VERSION ""

NS_ :

BS_:

BU_: RAD_RR RAD_RL RAD_FR RAD_FL RAD_FC CGW APA ADC

BO_ 537 VCU_CGW_219: 8 CGW
 SG_ VCURemainingRng : 17|10@0+ (1,0) [0|1000] "" Vector__XXX
 SG_ VCUMotOverSpd : 55|1@0+ (1,0) [0|1] "" Vector__XXX
 SG_ VCUPwrDisp : 33|10@0+ (1,-300) [-300|700] "kw" Vector__XXX
 SG_ VCUMotOverTemp : 54|1@0+ (1,0) [0|1] "" Vector__XXX
 SG_ VCUImdStopDriving : 63|1@0+ (1,0) [0|1] "" Vector__XXX
 SG_ VCUDrvModIndcn : 20|3@0+ (1,0) [0|7] "" Vector__XXX
 SG_ VCURmvAcChger : 62|1@0+ (1,0) [0|1] "" Vector__XXX
 SG_ CrrntLimdClsAirCdnrIndcn : 4|1@0+ (1,0) [0|1] "" Vector__XXX
 SG_ DCStationCrrntLimdIndcn : 15|1@0+ (1,0) [0|1] "" Vector__XXX
 SG_ DCChrgrPluginSts : 9|1@0+ (1,0) [0|1] "" Vector__XXX
 SG_ CrrntLimdLockVehIndcn : 5|1@0+ (1,0) [0|1] "" Vector__XXX
 SG_ ACChrgrOverT : 39|1@0+ (1,0) [0|1] "" Vector__XXX
 SG_ VehPwrLimdlampReq : 61|1@0+ (1,0) [0|1] "" Vector__XXX
 SG_ DCChrgPortTempHighIndcn : 1|1@0+ (1,0) [0|1] "" Vector__XXX
 SG_ VCURgnCpLimdIndcn : 14|1@0+ (1,0) [0|1] "" Vector__XXX
 SG_ VCUElecLockfail : 8|1@0+ (1,0) [0|1] "" Vector__XXX
 SG_ VCUShiftChangefail : 59|1@0+ (1,0) [0|1] "" Vector__XXX
 SG_ VCUBrakeRemind : 60|1@0+ (1,0) [0|1] "" Vector__XXX
 SG_ VCUVehRdy : 53|1@0+ (1,0) [0|1] ""  RAD_FC
 SG_ VCURegenSts : 49|2@0+ (1,0) [0|3] "" Vector__XXX
 SG_ DCChrgrOverT : 38|1@0+ (1,0) [0|1] "" Vector__XXX
 SG_ HiVoltCntctrSts : 58|3@0+ (1,0) [0|7] "" Vector__XXX
 SG_ ACChrgrPluginSts : 52|1@0+ (1,0) [0|1] "" Vector__XXX
 SG_ VCUChrgDispLampReq : 23|3@0+ (1,0) [0|7] "" Vector__XXX
 SG_ DCChrgPortTempLowIndcn : 0|1@0+ (1,0) [0|1] "" Vector__XXX
 SG_ ACChrgPortTempLowIndcn : 2|1@0+ (1,0) [0|1] "" Vector__XXX
 SG_ VCUHVILError : 51|1@0+ (1,0) [0|1] "" Vector__XXX
 SG_ ACChrgCurrentRng : 11|2@0+ (1,0) [0|3] "" Vector__XXX
 SG_ ACChrgPortTempHighIndcn : 3|1@0+ (1,0) [0|1] "" Vector__XXX
 SG_ ACChrgCmplSts : 13|2@0+ (1,0) [0|3] "" Vector__XXX
 SG_ VCUFourWhlDrvIndcn : 37|2@0+ (1,0) [0|3] "" Vector__XXX
 SG_ EPFaultLevelWarning : 35|2@0+ (1,0) [0|3] "" Vector__XXX
 SG_ VCUChgLineSts : 50|1@0+ (1,0) [0|1] "" Vector__XXX

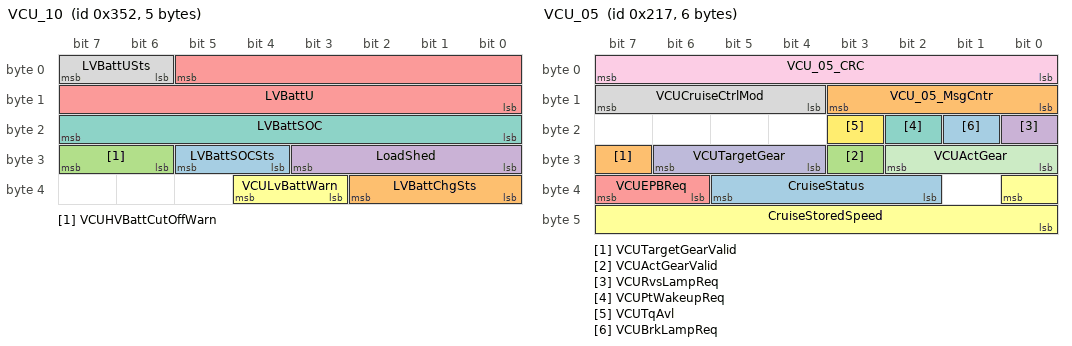
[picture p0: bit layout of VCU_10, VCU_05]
BO_ 850 VCU_10: 5 CGW
 SG_ LVBattSOCSts : 29|2@0+ (1,0) [0|3] "" Vector__XXX
 SG_ LVBattChgSts : 34|3@0+ (1,0) [0|7] "" Vector__XXX
 SG_ VCUHVBattCutOffWarn : 31|2@0+ (1,0) [0|3] "" Vector__XXX
 SG_ LoadShed : 27|4@0+ (1,0) [0|15] "" Vector__XXX
 SG_ LVBattU : 5|14@0+ (0.000976563,3) [3|18] "V"  RAD_RL,RAD_FR,ADC,RAD_RR,RAD_FC,RAD_FL
 SG_ VCULvBattWarn : 36|2@0+ (1,0) [0|3] "" Vector__XXX
 SG_ LVBattSOC : 23|8@0+ (1,0) [0|100] "%" Vector__XXX
 SG_ LVBattUSts : 7|2@0+ (1,0) [0|3] ""  ADC,RAD_FC,RAD_RL,APA,RAD_FR,RAD_FL,RAD_RR

BO_ 535 VCU_05: 6 CGW
 SG_ CruiseStatus : 37|4@0+ (1,0) [0|15] "" Vector__XXX
 SG_ VCUTargetGearValid : 31|1@0+ (1,0) [0|1] "" Vector__XXX
 SG_ VCUActGearValid : 27|1@0+ (1,0) [0|1] ""  RAD_FL,RAD_RR,APA,RAD_RL,RAD_FC,RAD_FR
 SG_ VCURvsLampReq : 16|1@0+ (1,0) [0|1] "" Vector__XXX
 SG_ VCUEPBReq : 39|2@0+ (1,0) [0|3] "" Vector__XXX
 SG_ CruiseStoredSpeed : 32|9@0+ (0.5,0) [0|255.5] "" Vector__XXX
 SG_ VCUPtWakeupReq : 18|1@0+ (1,0) [0|1] "" Vector__XXX
 SG_ VCUCruiseCtrlMod : 15|4@0+ (1,0) [0|15] "" Vector__XXX
 SG_ VCU_05_CRC : 7|8@0+ (1,0) [0|255] ""  RAD_FR,RAD_FC,RAD_FL,RAD_RL,APA,RAD_RR
 SG_ VCUTargetGear : 30|3@0+ (1,0) [0|7] "" Vector__XXX
 SG_ VCUActGear : 26|3@0+ (1,0) [0|7] ""  RAD_RR,APA,RAD_FL,RAD_RL,RAD_FC,RAD_FR
 SG_ VCUTqAvl : 19|1@0+ (1,0) [0|1] ""  ADC
 SG_ VCUBrkLampReq : 17|1@0+ (1,0) [0|1] "" Vector__XXX
 SG_ VCU_05_MsgCntr : 11|4@0+ (1,0) [0|15] ""  RAD_RL,APA,RAD_RR,RAD_FC,RAD_FR,RAD_FL

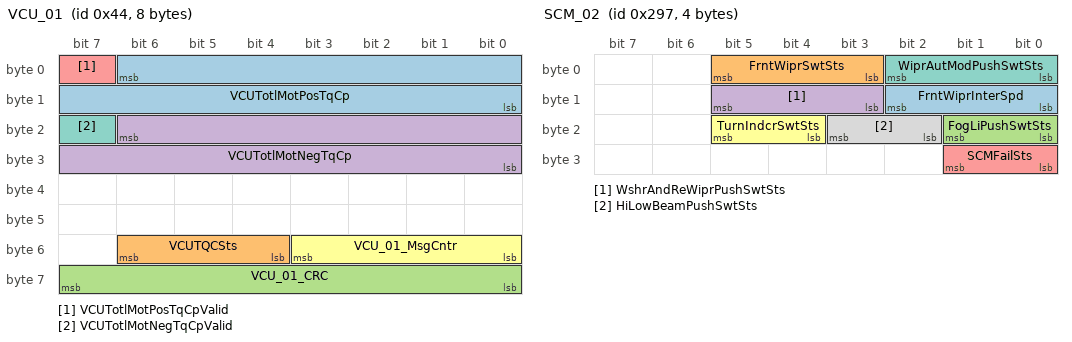
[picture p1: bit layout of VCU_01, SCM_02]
BO_ 68 VCU_01: 8 CGW
 SG_ VCUTotlMotPosTqCp : 6|15@0- (0.125,0) [-2048|2047.875] "Nm"  ADC
 SG_ VCUTQCSts : 54|3@0+ (1,0) [0|7] ""  ADC
 SG_ VCU_01_CRC : 63|8@0+ (1,0) [0|255] "" Vector__XXX
 SG_ VCUTotlMotNegTqCp : 22|15@0- (0.125,0) [-2048|2047.875] "Nm"  ADC
 SG_ VCUTotlMotPosTqCpValid : 7|1@0+ (1,0) [0|1] "" Vector__XXX
 SG_ VCU_01_MsgCntr : 51|4@0+ (1,0) [0|15] "" Vector__XXX
 SG_ VCUTotlMotNegTqCpValid : 23|1@0+ (1,0) [0|1] "" Vector__XXX

BO_ 663 SCM_02: 4 CGW
 SG_ FrntWiprInterSpd : 10|3@0+ (1,0) [0|7] "" Vector__XXX
 SG_ FrntWiprSwtSts : 5|3@0+ (1,0) [0|7] "" Vector__XXX
 SG_ FogLiPushSwtSts : 17|2@0+ (1,0) [0|3] "" Vector__XXX
 SG_ WshrAndReWiprPushSwtSts : 13|3@0+ (1,0) [0|7] "" Vector__XXX
 SG_ SCMFailSts : 25|2@0+ (1,0) [0|3] "" Vector__XXX
 SG_ TurnIndcrSwtSts : 21|2@0+ (1,0) [0|3] ""  RAD_RR,RAD_RL,RAD_FR,RAD_FL
 SG_ WiprAutModPushSwtSts : 2|3@0+ (1,0) [0|3] "" Vector__XXX
 SG_ HiLowBeamPushSwtSts : 19|2@0+ (1,0) [0|3] "" Vector__XXX

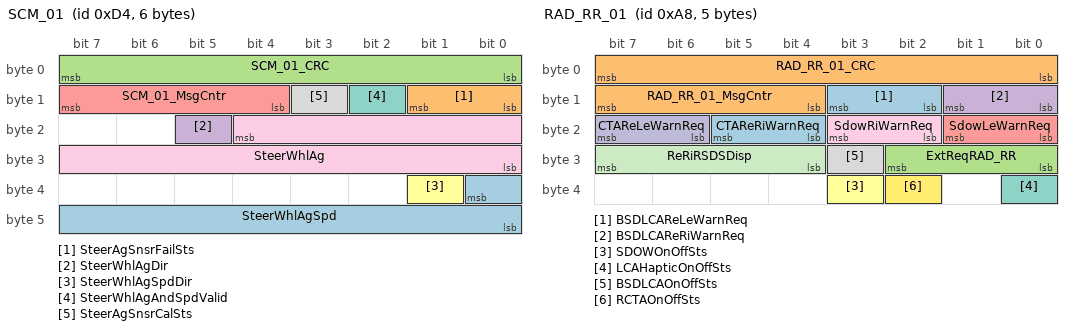
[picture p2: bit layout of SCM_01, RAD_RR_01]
BO_ 212 SCM_01: 6 CGW
 SG_ SteerWhlAgSpd : 32|9@0+ (5,0) [0|2550] "Deg/sec"  RAD_RR,RAD_FL,RAD_FR,RAD_FC,RAD_RL
 SG_ SteerAgSnsrFailSts : 9|2@0+ (1,0) [0|3] ""  RAD_FR,RAD_FL,RAD_RR,RAD_RL,RAD_FC
 SG_ SCM_01_CRC : 7|8@0+ (1,0) [0|255] ""  RAD_RL,RAD_RR,RAD_FL,RAD_FR,RAD_FC
 SG_ SteerWhlAgDir : 21|1@0+ (1,0) [0|1] ""  RAD_FR,RAD_FC,RAD_RR,RAD_FL,RAD_RL
 SG_ SCM_01_MsgCntr : 15|4@0+ (1,0) [0|15] ""  RAD_RL,RAD_FR,RAD_FC,RAD_RR,RAD_FL
 SG_ SteerWhlAgSpdDir : 33|1@0+ (1,0) [0|1] ""  RAD_RR,RAD_FL,RAD_RL,RAD_FC,RAD_FR
 SG_ SteerWhlAgAndSpdValid : 10|1@0+ (1,0) [0|1] ""  RAD_FC,RAD_RR,RAD_FL,RAD_FR,RAD_RL
 SG_ SteerAgSnsrCalSts : 11|1@0+ (1,0) [0|1] ""  RAD_RL,RAD_FR,RAD_FL,RAD_FC,RAD_RR
 SG_ SteerWhlAg : 20|13@0+ (0.1,0) [0|800] "Deg"  RAD_FL,RAD_RL,RAD_FR,RAD_FC,RAD_RR

BO_ 168 RAD_RR_01: 5 RAD_RR
 SG_ BSDLCAReLeWarnReq : 11|2@0+ (1,0) [0|3] ""  CGW
 SG_ RAD_RR_01_MsgCntr : 15|4@0+ (1,0) [0|15] ""  CGW
 SG_ ExtReqRAD_RR : 26|3@0+ (1,0) [0|7] ""  CGW
 SG_ BSDLCAReRiWarnReq : 9|2@0+ (1,0) [0|3] ""  CGW
 SG_ SdowLeWarnReq : 17|2@0+ (1,0) [0|3] ""  CGW
 SG_ SDOWOnOffSts : 35|1@0+ (1,0) [0|1] ""  CGW
 SG_ LCAHapticOnOffSts : 32|1@0+ (1,0) [0|1] ""  CGW
 SG_ BSDLCAOnOffSts : 27|1@0+ (1,0) [0|1] ""  CGW
 SG_ SdowRiWarnReq : 19|2@0+ (1,0) [0|3] ""  CGW
 SG_ CTAReLeWarnReq : 23|2@0+ (1,0) [0|3] ""  CGW
 SG_ ReRiRSDSDisp : 31|4@0+ (1,0) [0|15] ""  CGW
 SG_ RCTAOnOffSts : 34|1@0+ (1,0) [0|1] ""  CGW
 SG_ CTAReRiWarnReq : 21|2@0+ (1,0) [0|3] ""  CGW
 SG_ RAD_RR_01_CRC : 7|8@0+ (1,0) [0|255] ""  CGW

BO_ 607 RAD_RL_SYNC: 8 RAD_RL
 SG_ Dummy_RAD_RL : 7|8@0+ (1,0) [0|255] ""  RAD_RR,CGW

BO_ 603 RAD_FR_SYNC: 8 RAD_FR
 SG_ Dummy_RAD_FR : 7|8@0+ (1,0) [0|255] ""  CGW

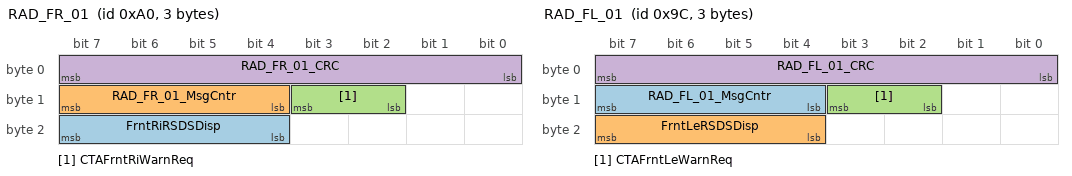
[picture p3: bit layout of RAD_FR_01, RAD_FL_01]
BO_ 160 RAD_FR_01: 3 ADC
 SG_ FrntRiRSDSDisp : 23|4@0+ (1,0) [0|15] ""  CGW
 SG_ RAD_FR_01_MsgCntr : 15|4@0+ (1,0) [0|15] ""  CGW
 SG_ CTAFrntRiWarnReq : 11|2@0+ (1,0) [0|3] ""  CGW
 SG_ RAD_FR_01_CRC : 7|8@0+ (1,0) [0|255] ""  CGW

BO_ 599 RAD_FL_SYNC: 8 RAD_FL
 SG_ Dummy_RAD_FL : 7|8@0+ (1,0) [0|255] ""  CGW

BO_ 156 RAD_FL_01: 3 ADC
 SG_ RAD_FL_01_MsgCntr : 15|4@0+ (1,0) [0|15] ""  CGW
 SG_ FrntLeRSDSDisp : 23|4@0+ (1,0) [0|15] ""  CGW
 SG_ CTAFrntLeWarnReq : 11|2@0+ (1,0) [0|3] ""  CGW
 SG_ RAD_FL_01_CRC : 7|8@0+ (1,0) [0|255] ""  CGW

BO_ 567 RAD_FC_SYNC: 8 RAD_FC
 SG_ Dummy_RAD_FC : 7|8@0+ (1,0) [0|255] ""  CGW

BO_ 126 RAD_FC_03: 8 ADC
 SG_ ClsObjTyp : 59|4@0+ (1,0) [0|15] ""  CGW
 SG_ DisplayVelocitySet : 31|9@0+ (0.5,0) [0|255.5] "Km/h"  CGW
 SG_ PCWLatentWarnOnOffSts : 19|1@0+ (1,0) [0|1] ""  CGW
 SG_ GoNotifierOnOffSts : 8|1@0+ (1,0) [0|1] ""  CGW
 SG_ Textinfo : 44|5@0+ (1,0) [0|15] ""  CGW
 SG_ TSRSpdLimDataOnOffSts : 9|1@0+ (1,0) [0|1] ""  CGW
 SG_ AEBSts : 11|2@0+ (1,0) [0|3] ""  CGW
 SG_ ClsObjDst : 55|8@0+ (1,0) [0|255] ""  CGW
 SG_ FCWSetSts : 21|2@0+ (1,0) [0|3] ""  CGW
 SG_ RAD_FC_03_MsgCntr : 15|4@0+ (1,0) [0|15] ""  CGW
 SG_ RAD_FC_03_CRC : 7|8@0+ (1,0) [0|255] ""  CGW
 SG_ TakeOverReq : 35|1@0+ (1,0) [0|1] ""  CGW
 SG_ ObjValid : 38|1@0+ (1,0) [0|1] ""  CGW
 SG_ PCWPreWarnOnOffSts : 18|1@0+ (1,0) [0|1] ""  CGW
 SG_ ACC_FreeSpaceIntrusion : 63|2@0+ (1,0) [0|3] ""  CGW
 SG_ ACC_CutInDetected : 61|2@0+ (1,0) [0|3] ""  CGW
 SG_ ACCMode : 34|3@0+ (1,0) [0|7] ""  CGW
 SG_ GoNotifierReq : 17|2@0+ (1,0) [0|3] ""  CGW
 SG_ PCW_latentWarning : 37|1@0+ (1,0) [0|1] ""  CGW
 SG_ TauGapSet : 47|3@0+ (1,0) [0|7] ""  CGW
 SG_ PCW_preWarning : 36|1@0+ (1,0) [0|1] ""  CGW

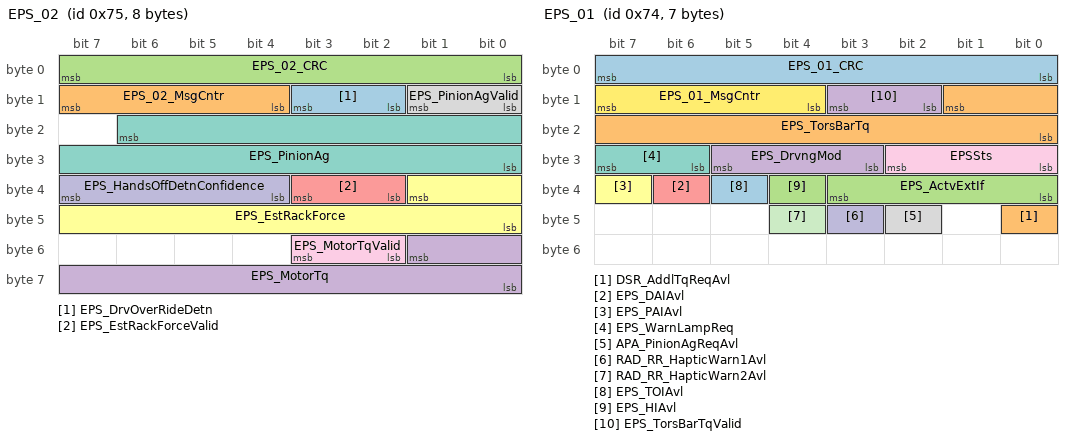
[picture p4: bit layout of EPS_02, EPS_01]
BO_ 117 EPS_02: 8 CGW
 SG_ EPS_DrvOverRideDetn : 11|2@0+ (1,0) [0|3] ""  APA
 SG_ EPS_02_MsgCntr : 15|4@0+ (1,0) [0|15] ""  RAD_RR,RAD_FC,RAD_FR,RAD_RL,RAD_FL,APA
 SG_ EPS_02_CRC : 7|8@0+ (1,0) [0|255] ""  RAD_FC,RAD_RL,APA,RAD_FL,RAD_FR,RAD_RR
 SG_ EPS_MotorTq : 49|10@0+ (0.02,-10.24) [-10.24|10.22] "Nm" Vector__XXX
 SG_ EPS_EstRackForceValid : 35|2@0+ (1,0) [0|3] "" Vector__XXX
 SG_ EPS_EstRackForce : 33|10@0+ (0.04,-20.48) [-20.48|20.44] "KN" Vector__XXX
 SG_ EPS_PinionAg : 22|15@0+ (0.1,-1638.4) [-1638.4|1638.2] "Deg"  RAD_RR,RAD_FL,RAD_FC,RAD_RL,RAD_FR,APA
 SG_ EPS_PinionAgValid : 9|2@0+ (1,0) [0|3] ""  APA,RAD_FC,RAD_RL,RAD_RR,RAD_FR,RAD_FL
 SG_ EPS_MotorTqValid : 51|2@0+ (1,0) [0|3] "" Vector__XXX
 SG_ EPS_HandsOffDetnConfidence : 39|4@0+ (1,0) [0|15] "" Vector__XXX

BO_ 116 EPS_01: 7 CGW
 SG_ EPS_01_CRC : 7|8@0+ (1,0) [0|255] ""  APA,RAD_RR
 SG_ DSR_AddlTqReqAvl : 40|1@0+ (1,0) [0|1] "" Vector__XXX
 SG_ EPS_ActvExtIf : 35|4@0+ (1,0) [0|15] ""  APA,RAD_RR
 SG_ EPS_DrvngMod : 29|3@0+ (1,0) [0|7] "" Vector__XXX
 SG_ EPS_DAIAvl : 38|1@0+ (1,0) [0|1] "" Vector__XXX
 SG_ EPS_PAIAvl : 39|1@0+ (1,0) [0|1] "" Vector__XXX
 SG_ EPS_WarnLampReq : 31|2@0+ (1,0) [0|3] "" Vector__XXX
 SG_ APA_PinionAgReqAvl : 42|1@0+ (1,0) [0|1] ""  APA
 SG_ EPSSts : 26|3@0+ (1,0) [0|7] ""  APA,RAD_RR
 SG_ RAD_RR_HapticWarn1Avl : 43|1@0+ (1,0) [0|1] ""  RAD_RR
 SG_ RAD_RR_HapticWarn2Avl : 44|1@0+ (1,0) [0|1] ""  RAD_RR
 SG_ EPS_01_MsgCntr : 15|4@0+ (1,0) [0|15] ""  RAD_RR,APA
 SG_ EPS_TOIAvl : 37|1@0+ (1,0) [0|1] "" Vector__XXX
 SG_ EPS_TorsBarTq : 9|10@0+ (0.02,-10.24) [-10.24|10.22] "Nm" Vector__XXX
 SG_ EPS_HIAvl : 36|1@0+ (1,0) [0|1] "" Vector__XXX
 SG_ EPS_TorsBarTqValid : 11|2@0+ (1,0) [0|3] "" Vector__XXX

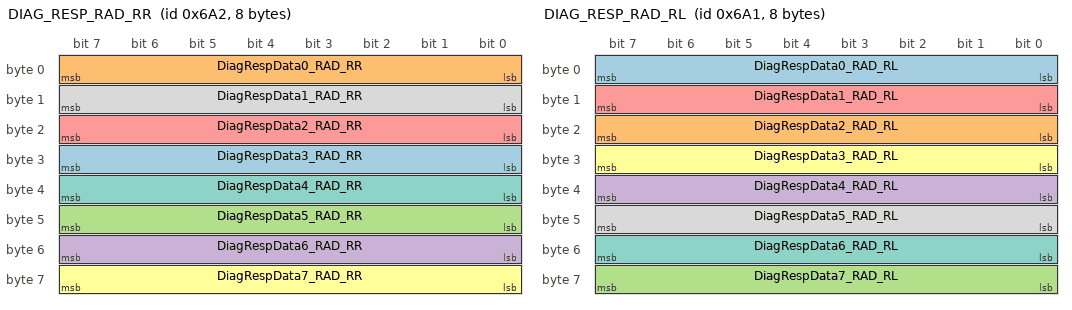
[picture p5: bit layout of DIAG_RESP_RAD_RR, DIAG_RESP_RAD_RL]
BO_ 1698 DIAG_RESP_RAD_RR: 8 RAD_RR
 SG_ DiagRespData3_RAD_RR : 31|8@0+ (1,0) [0|255] ""  CGW
 SG_ DiagRespData0_RAD_RR : 7|8@0+ (1,0) [0|255] ""  CGW
 SG_ DiagRespData5_RAD_RR : 47|8@0+ (1,0) [0|255] ""  CGW
 SG_ DiagRespData6_RAD_RR : 55|8@0+ (1,0) [0|255] ""  CGW
 SG_ DiagRespData2_RAD_RR : 23|8@0+ (1,0) [0|255] ""  CGW
 SG_ DiagRespData7_RAD_RR : 63|8@0+ (1,0) [0|255] ""  CGW
 SG_ DiagRespData4_RAD_RR : 39|8@0+ (1,0) [0|255] ""  CGW
 SG_ DiagRespData1_RAD_RR : 15|8@0+ (1,0) [0|255] ""  CGW

BO_ 1697 DIAG_RESP_RAD_RL: 8 RAD_RL
 SG_ DiagRespData0_RAD_RL : 7|8@0+ (1,0) [0|255] ""  CGW
 SG_ DiagRespData2_RAD_RL : 23|8@0+ (1,0) [0|255] ""  CGW
 SG_ DiagRespData7_RAD_RL : 63|8@0+ (1,0) [0|255] ""  CGW
 SG_ DiagRespData4_RAD_RL : 39|8@0+ (1,0) [0|255] ""  CGW
 SG_ DiagRespData1_RAD_RL : 15|8@0+ (1,0) [0|255] ""  CGW
 SG_ DiagRespData3_RAD_RL : 31|8@0+ (1,0) [0|255] ""  CGW
 SG_ DiagRespData6_RAD_RL : 55|8@0+ (1,0) [0|255] ""  CGW
 SG_ DiagRespData5_RAD_RL : 47|8@0+ (1,0) [0|255] ""  CGW

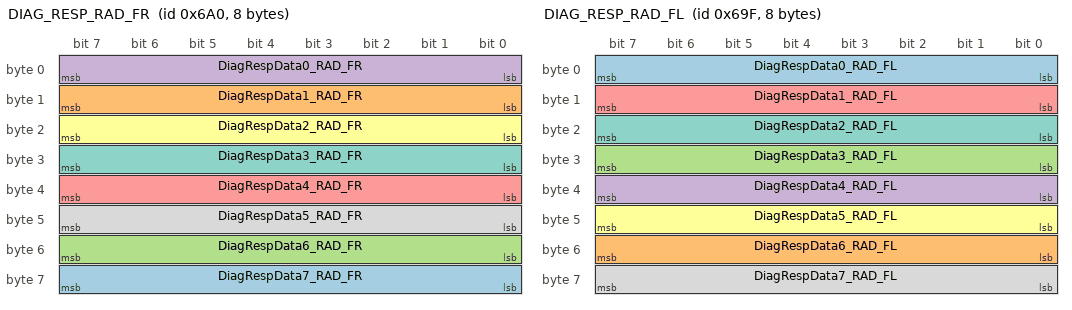
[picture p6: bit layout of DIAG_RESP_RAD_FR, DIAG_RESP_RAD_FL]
BO_ 1696 DIAG_RESP_RAD_FR: 8 RAD_FR
 SG_ DiagRespData7_RAD_FR : 63|8@0+ (1,0) [0|255] ""  CGW
 SG_ DiagRespData1_RAD_FR : 15|8@0+ (1,0) [0|255] ""  CGW
 SG_ DiagRespData6_RAD_FR : 55|8@0+ (1,0) [0|255] ""  CGW
 SG_ DiagRespData0_RAD_FR : 7|8@0+ (1,0) [0|255] ""  CGW
 SG_ DiagRespData4_RAD_FR : 39|8@0+ (1,0) [0|255] ""  CGW
 SG_ DiagRespData2_RAD_FR : 23|8@0+ (1,0) [0|255] ""  CGW
 SG_ DiagRespData3_RAD_FR : 31|8@0+ (1,0) [0|255] ""  CGW
 SG_ DiagRespData5_RAD_FR : 47|8@0+ (1,0) [0|255] ""  CGW

BO_ 1695 DIAG_RESP_RAD_FL: 8 RAD_FL
 SG_ DiagRespData0_RAD_FL : 7|8@0+ (1,0) [0|255] ""  CGW
 SG_ DiagRespData6_RAD_FL : 55|8@0+ (1,0) [0|255] ""  CGW
 SG_ DiagRespData3_RAD_FL : 31|8@0+ (1,0) [0|255] ""  CGW
 SG_ DiagRespData4_RAD_FL : 39|8@0+ (1,0) [0|255] ""  CGW
 SG_ DiagRespData1_RAD_FL : 15|8@0+ (1,0) [0|255] ""  CGW
 SG_ DiagRespData5_RAD_FL : 47|8@0+ (1,0) [0|255] ""  CGW
 SG_ DiagRespData2_RAD_FL : 23|8@0+ (1,0) [0|255] ""  CGW
 SG_ DiagRespData7_RAD_FL : 63|8@0+ (1,0) [0|255] ""  CGW

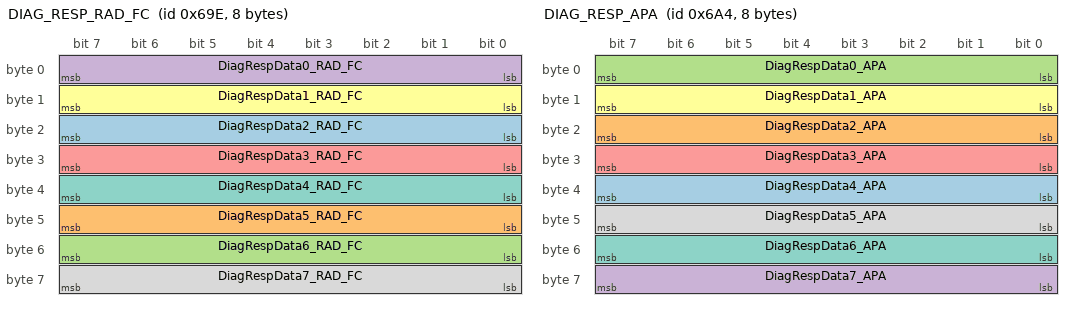
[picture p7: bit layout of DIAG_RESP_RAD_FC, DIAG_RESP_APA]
BO_ 1694 DIAG_RESP_RAD_FC: 8 RAD_FC
 SG_ DiagRespData2_RAD_FC : 23|8@0+ (1,0) [0|255] ""  CGW
 SG_ DiagRespData5_RAD_FC : 47|8@0+ (1,0) [0|255] ""  CGW
 SG_ DiagRespData6_RAD_FC : 55|8@0+ (1,0) [0|255] ""  CGW
 SG_ DiagRespData0_RAD_FC : 7|8@0+ (1,0) [0|255] ""  CGW
 SG_ DiagRespData3_RAD_FC : 31|8@0+ (1,0) [0|255] ""  CGW
 SG_ DiagRespData1_RAD_FC : 15|8@0+ (1,0) [0|255] ""  CGW
 SG_ DiagRespData4_RAD_FC : 39|8@0+ (1,0) [0|255] ""  CGW
 SG_ DiagRespData7_RAD_FC : 63|8@0+ (1,0) [0|255] ""  CGW

BO_ 1700 DIAG_RESP_APA: 8 APA
 SG_ DiagRespData4_APA : 39|8@0+ (1,0) [0|255] ""  CGW
 SG_ DiagRespData2_APA : 23|8@0+ (1,0) [0|255] ""  CGW
 SG_ DiagRespData0_APA : 7|8@0+ (1,0) [0|255] ""  CGW
 SG_ DiagRespData7_APA : 63|8@0+ (1,0) [0|255] ""  CGW
 SG_ DiagRespData3_APA : 31|8@0+ (1,0) [0|255] ""  CGW
 SG_ DiagRespData1_APA : 15|8@0+ (1,0) [0|255] ""  CGW
 SG_ DiagRespData6_APA : 55|8@0+ (1,0) [0|255] ""  CGW
 SG_ DiagRespData5_APA : 47|8@0+ (1,0) [0|255] ""  CGW

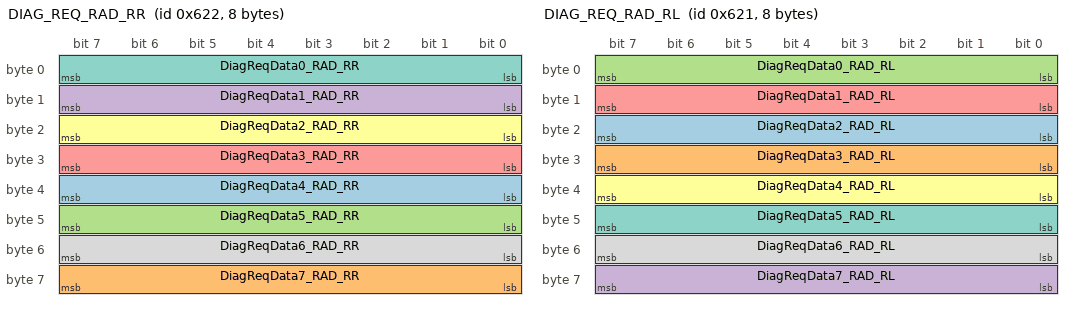
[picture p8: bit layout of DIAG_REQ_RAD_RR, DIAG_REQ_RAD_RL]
BO_ 1570 DIAG_REQ_RAD_RR: 8 CGW
 SG_ DiagReqData4_RAD_RR : 39|8@0+ (1,0) [0|255] ""  RAD_RR
 SG_ DiagReqData7_RAD_RR : 63|8@0+ (1,0) [0|255] ""  RAD_RR
 SG_ DiagReqData5_RAD_RR : 47|8@0+ (1,0) [0|255] ""  RAD_RR
 SG_ DiagReqData1_RAD_RR : 15|8@0+ (1,0) [0|255] ""  RAD_RR
 SG_ DiagReqData3_RAD_RR : 31|8@0+ (1,0) [0|255] ""  RAD_RR
 SG_ DiagReqData2_RAD_RR : 23|8@0+ (1,0) [0|255] ""  RAD_RR
 SG_ DiagReqData0_RAD_RR : 7|8@0+ (1,0) [0|255] ""  RAD_RR
 SG_ DiagReqData6_RAD_RR : 55|8@0+ (1,0) [0|255] ""  RAD_RR

BO_ 1569 DIAG_REQ_RAD_RL: 8 CGW
 SG_ DiagReqData2_RAD_RL : 23|8@0+ (1,0) [0|255] ""  RAD_RL
 SG_ DiagReqData3_RAD_RL : 31|8@0+ (1,0) [0|255] ""  RAD_RL
 SG_ DiagReqData0_RAD_RL : 7|8@0+ (1,0) [0|255] ""  RAD_RL
 SG_ DiagReqData7_RAD_RL : 63|8@0+ (1,0) [0|255] ""  RAD_RL
 SG_ DiagReqData1_RAD_RL : 15|8@0+ (1,0) [0|255] ""  RAD_RL
 SG_ DiagReqData4_RAD_RL : 39|8@0+ (1,0) [0|255] ""  RAD_RL
 SG_ DiagReqData5_RAD_RL : 47|8@0+ (1,0) [0|255] ""  RAD_RL
 SG_ DiagReqData6_RAD_RL : 55|8@0+ (1,0) [0|255] ""  RAD_RL

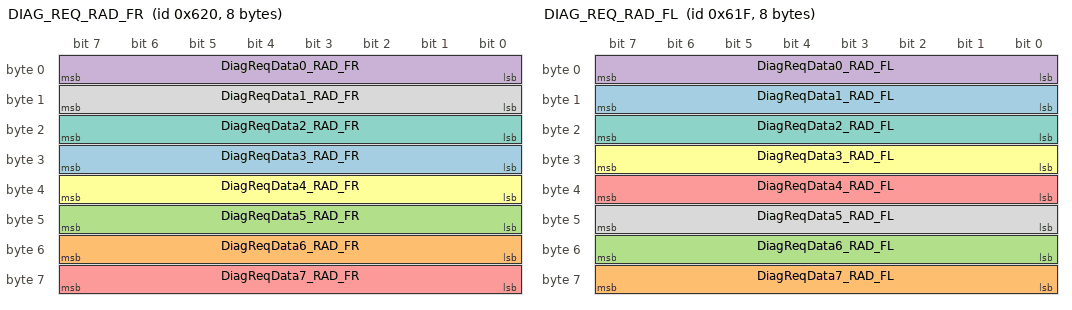
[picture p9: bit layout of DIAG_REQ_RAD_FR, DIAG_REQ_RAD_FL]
BO_ 1568 DIAG_REQ_RAD_FR: 8 CGW
 SG_ DiagReqData3_RAD_FR : 31|8@0+ (1,0) [0|255] ""  RAD_FR
 SG_ DiagReqData6_RAD_FR : 55|8@0+ (1,0) [0|255] ""  RAD_FR
 SG_ DiagReqData5_RAD_FR : 47|8@0+ (1,0) [0|255] ""  RAD_FR
 SG_ DiagReqData0_RAD_FR : 7|8@0+ (1,0) [0|255] ""  RAD_FR
 SG_ DiagReqData7_RAD_FR : 63|8@0+ (1,0) [0|255] ""  RAD_FR
 SG_ DiagReqData4_RAD_FR : 39|8@0+ (1,0) [0|255] ""  RAD_FR
 SG_ DiagReqData2_RAD_FR : 23|8@0+ (1,0) [0|255] ""  RAD_FR
 SG_ DiagReqData1_RAD_FR : 15|8@0+ (1,0) [0|255] ""  RAD_FR

BO_ 1567 DIAG_REQ_RAD_FL: 8 CGW
 SG_ DiagReqData1_RAD_FL : 15|8@0+ (1,0) [0|255] ""  RAD_FL
 SG_ DiagReqData7_RAD_FL : 63|8@0+ (1,0) [0|255] ""  RAD_FL
 SG_ DiagReqData6_RAD_FL : 55|8@0+ (1,0) [0|255] ""  RAD_FL
 SG_ DiagReqData0_RAD_FL : 7|8@0+ (1,0) [0|255] ""  RAD_FL
 SG_ DiagReqData4_RAD_FL : 39|8@0+ (1,0) [0|255] ""  RAD_FL
 SG_ DiagReqData3_RAD_FL : 31|8@0+ (1,0) [0|255] ""  RAD_FL
 SG_ DiagReqData2_RAD_FL : 23|8@0+ (1,0) [0|255] ""  RAD_FL
 SG_ DiagReqData5_RAD_FL : 47|8@0+ (1,0) [0|255] ""  RAD_FL

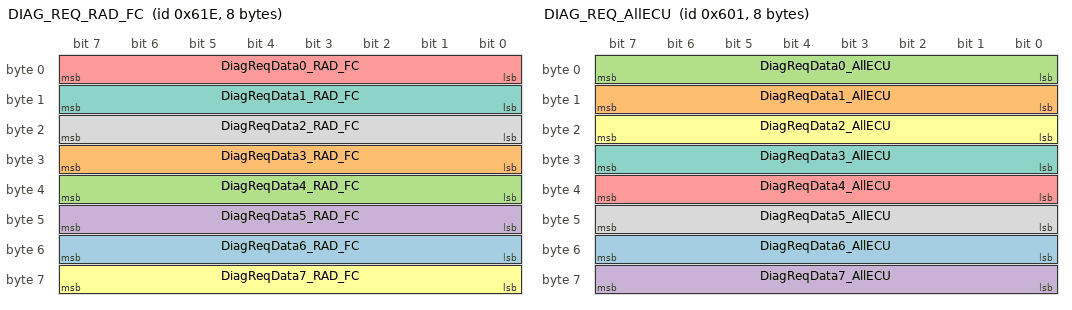
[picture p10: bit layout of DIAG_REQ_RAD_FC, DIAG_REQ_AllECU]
BO_ 1566 DIAG_REQ_RAD_FC: 8 CGW
 SG_ DiagReqData6_RAD_FC : 55|8@0+ (1,0) [0|255] ""  RAD_FC
 SG_ DiagReqData3_RAD_FC : 31|8@0+ (1,0) [0|255] ""  RAD_FC
 SG_ DiagReqData4_RAD_FC : 39|8@0+ (1,0) [0|255] ""  RAD_FC
 SG_ DiagReqData5_RAD_FC : 47|8@0+ (1,0) [0|255] ""  RAD_FC
 SG_ DiagReqData0_RAD_FC : 7|8@0+ (1,0) [0|255] ""  RAD_FC
 SG_ DiagReqData7_RAD_FC : 63|8@0+ (1,0) [0|255] ""  RAD_FC
 SG_ DiagReqData1_RAD_FC : 15|8@0+ (1,0) [0|255] ""  RAD_FC
 SG_ DiagReqData2_RAD_FC : 23|8@0+ (1,0) [0|255] ""  RAD_FC

BO_ 1537 DIAG_REQ_AllECU: 8 CGW
 SG_ DiagReqData6_AllECU : 55|8@0+ (1,0) [0|255] ""  APA,RAD_FR,RAD_FL,RAD_FC,RAD_RR,RAD_RL
 SG_ DiagReqData1_AllECU : 15|8@0+ (1,0) [0|255] ""  RAD_FR,RAD_FL,APA,RAD_RL,RAD_FC,RAD_RR
 SG_ DiagReqData0_AllECU : 7|8@0+ (1,0) [0|255] ""  RAD_RR,RAD_FL,RAD_FR,RAD_RL,RAD_FC,APA
 SG_ DiagReqData7_AllECU : 63|8@0+ (1,0) [0|255] ""  RAD_FL,RAD_FR,RAD_FC,RAD_RL,RAD_RR,APA
 SG_ DiagReqData4_AllECU : 39|8@0+ (1,0) [0|255] ""  RAD_RL,RAD_FL,RAD_RR,RAD_FC,APA,RAD_FR
 SG_ DiagReqData2_AllECU : 23|8@0+ (1,0) [0|255] ""  RAD_RR,RAD_FR,APA,RAD_RL,RAD_FL,RAD_FC
 SG_ DiagReqData3_AllECU : 31|8@0+ (1,0) [0|255] ""  RAD_RR,RAD_FL,RAD_RL,RAD_FC,RAD_FR,APA
 SG_ DiagReqData5_AllECU : 47|8@0+ (1,0) [0|255] ""  RAD_FL,RAD_FR,RAD_RL,RAD_RR,APA,RAD_FC

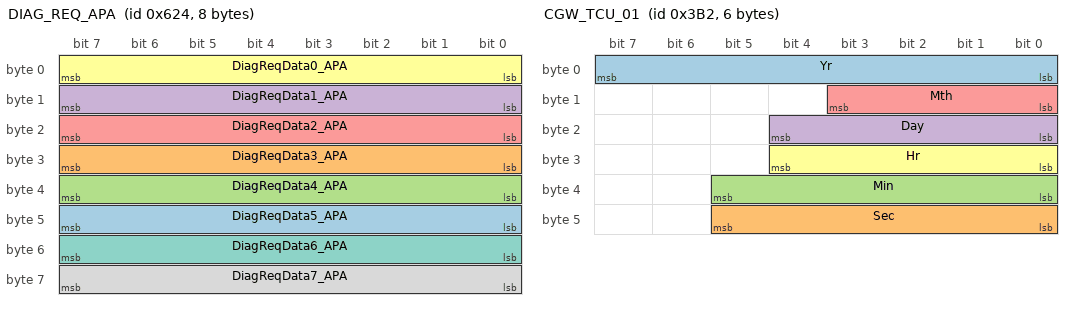
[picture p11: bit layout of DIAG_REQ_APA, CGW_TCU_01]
BO_ 1572 DIAG_REQ_APA: 8 CGW
 SG_ DiagReqData5_APA : 47|8@0+ (1,0) [0|255] ""  APA
 SG_ DiagReqData3_APA : 31|8@0+ (1,0) [0|255] ""  APA
 SG_ DiagReqData4_APA : 39|8@0+ (1,0) [0|255] ""  APA
 SG_ DiagReqData1_APA : 15|8@0+ (1,0) [0|255] ""  APA
 SG_ DiagReqData2_APA : 23|8@0+ (1,0) [0|255] ""  APA
 SG_ DiagReqData0_APA : 7|8@0+ (1,0) [0|255] ""  APA
 SG_ DiagReqData6_APA : 55|8@0+ (1,0) [0|255] ""  APA
 SG_ DiagReqData7_APA : 63|8@0+ (1,0) [0|255] ""  APA

BO_ 946 CGW_TCU_01: 6 CGW
 SG_ Yr : 7|8@0+ (1,2000) [2000|2254] "Year"  RAD_FR,RAD_FL,RAD_RR,RAD_RL,APA,RAD_FC
 SG_ Sec : 45|6@0+ (1,0) [0|59] "Sec"  RAD_FL,RAD_FC,RAD_RL,RAD_RR,RAD_FR,APA
 SG_ Min : 37|6@0+ (1,0) [0|59] "min"  RAD_FL,RAD_FC,APA,RAD_RL,RAD_RR,RAD_FR
 SG_ Day : 20|5@0+ (1,0) [0|31] "Day"  APA,RAD_FL,RAD_RL,RAD_RR,RAD_FR,RAD_FC
 SG_ Mth : 11|4@0+ (1,0) [0|15] ""  RAD_RL,RAD_RR,APA,RAD_FR,RAD_FC,RAD_FL
 SG_ Hr : 28|5@0+ (1,0) [0|23] "Hour"  RAD_FC,RAD_FR,APA,RAD_RL,RAD_RR,RAD_FL

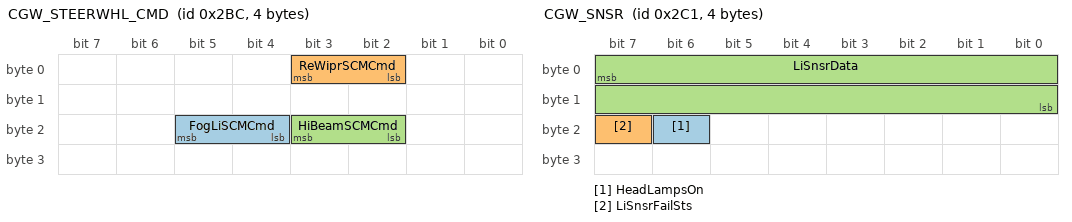
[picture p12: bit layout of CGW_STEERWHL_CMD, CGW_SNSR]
BO_ 700 CGW_STEERWHL_CMD: 4 CGW
 SG_ FogLiSCMCmd : 21|2@0+ (1,0) [0|3] ""  ADC
 SG_ ReWiprSCMCmd : 3|2@0+ (1,0) [0|3] ""  ADC
 SG_ HiBeamSCMCmd : 19|2@0+ (1,0) [0|3] ""  ADC

BO_ 705 CGW_SNSR: 4 CGW
 SG_ HeadLampsOn : 22|1@0+ (1,0) [0|1] "" Vector__XXX
 SG_ LiSnsrFailSts : 23|1@0+ (1,0) [0|1] ""  ADC
 SG_ LiSnsrData : 7|16@0+ (1,0) [0|10000] "cd/m2"  ADC

BO_ 957 CGW_BULB_OUT: 3 CGW
 SG_ BulbOutFogLiFrntLe : 4|1@0+ (1,0) [0|1] "" Vector__XXX
 SG_ BulbOutHiBeamRi : 17|1@0+ (1,0) [0|1] "" Vector__XXX
 SG_ BulbOutTurnIndcnFrntLe : 0|1@0+ (1,0) [0|1] "" Vector__XXX
 SG_ BulbOutTrBrkPosnLiReRi : 13|1@0+ (1,0) [0|1] "" Vector__XXX
 SG_ BulbOutDayTiRunngLiFrntLe : 8|1@0+ (1,0) [0|1] "" Vector__XXX
 SG_ BulbOutLoBeamLe : 18|1@0+ (1,0) [0|1] "" Vector__XXX
 SG_ BulbOutFenderBrkPosnLiReRi : 11|1@0+ (1,0) [0|1] ""  ADC
 SG_ BulbOutTrBrkPosnLiReLe : 12|1@0+ (1,0) [0|1] "" Vector__XXX
 SG_ BulbOutFogLiFrntRi : 5|1@0+ (1,0) [0|1] "" Vector__XXX
 SG_ BulbOutLoBeamRi : 19|1@0+ (1,0) [0|1] "" Vector__XXX
 SG_ BulbOutHiBeamLe : 16|1@0+ (1,0) [0|1] "" Vector__XXX
 SG_ BulbOutResvLiLe : 20|1@0+ (1,0) [0|1] "" Vector__XXX
 SG_ BulbOutTurnIndcnReRi : 3|1@0+ (1,0) [0|1] "" Vector__XXX
 SG_ BulbOutFogLiReRi : 7|1@0+ (1,0) [0|1] "" Vector__XXX
 SG_ BulbOutBrkLiTop : 14|1@0+ (1,0) [0|1] ""  ADC
 SG_ BulbOutTurnIndcnFrntRi : 1|1@0+ (1,0) [0|1] "" Vector__XXX
 SG_ BulbOutTurnIndcnReLe : 2|1@0+ (1,0) [0|1] "" Vector__XXX
 SG_ BulbOutFogLiReLe : 6|1@0+ (1,0) [0|1] "" Vector__XXX
 SG_ BulbOutDayTiRunngLiFrntRi : 9|1@0+ (1,0) [0|1] "" Vector__XXX
 SG_ BulbOutFenderBrkPosnLiReLe : 10|1@0+ (1,0) [0|1] ""  ADC
 SG_ BulbOutResvLiRi : 21|1@0+ (1,0) [0|1] "" Vector__XXX

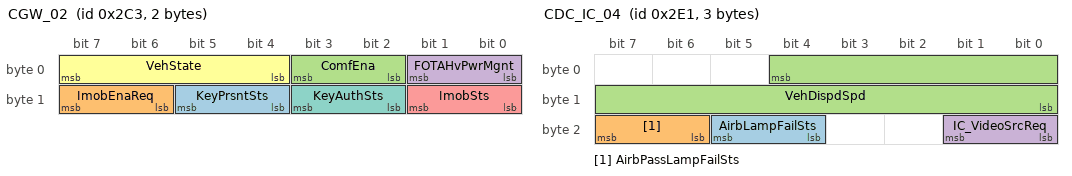
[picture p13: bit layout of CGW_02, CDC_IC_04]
BO_ 707 CGW_02: 2 CGW
 SG_ KeyPrsntSts : 13|2@0+ (1,0) [0|3] "" Vector__XXX
 SG_ ImobEnaReq : 15|2@0+ (1,0) [0|3] "" Vector__XXX
 SG_ ComfEna : 3|2@0+ (1,0) [0|3] "" Vector__XXX
 SG_ FOTAHvPwrMgnt : 1|2@0+ (1,0) [0|3] "" Vector__XXX
 SG_ ImobSts : 9|2@0+ (1,0) [0|3] "" Vector__XXX
 SG_ VehState : 7|4@0+ (1,0) [0|15] ""  APA,RAD_FC,RAD_RL,RAD_FL,RAD_FR,RAD_RR
 SG_ KeyAuthSts : 11|2@0+ (1,0) [0|3] "" Vector__XXX

BO_ 737 CDC_IC_04: 3 CGW
 SG_ AirbLampFailSts : 21|2@0+ (1,0) [0|3] "" Vector__XXX
 SG_ AirbPassLampFailSts : 23|2@0+ (1,0) [0|3] "" Vector__XXX
 SG_ VehDispdSpd : 4|13@0+ (0.05625,0) [0|360] "km/h"  RAD_FC
 SG_ IC_VideoSrcReq : 17|2@0+ (1,0) [0|3] "" Vector__XXX

BO_ 938 CDC_IC_01: 3 CGW
 SG_ VehOdometer : 7|24@0+ (1,0) [0|16777214] "km"  RAD_FL,APA,RAD_RL,RAD_RR,RAD_FR,RAD_FC

BO_ 686 CDC_HU_09: 7 CGW
 SG_ TowModActv : 41|2@0+ (1,0) [0|3] "" Vector__XXX
 SG_ ACChrgCurrentLimReq : 55|2@0+ (1,0) [0|3] "" Vector__XXX
 SG_ HVPwrInhbReq : 37|2@0+ (1,0) [0|3] "" Vector__XXX
 SG_ HMIStopChargingReq : 51|2@0+ (1,0) [0|3] "" Vector__XXX
 SG_ UPAReq : 17|2@0+ (1,0) [0|3] ""  APA,ADC
 SG_ HillDescentControlReq : 39|2@0+ (1,0) [0|3] "" Vector__XXX
 SG_ ESCAndTCSReq : 25|2@0+ (1,0) [0|3] "" Vector__XXX
 SG_ APAReq : 21|4@0+ (1,0) [0|15] ""  ADC,APA
 SG_ TowEPBReq : 44|3@0+ (1,0) [0|7] "" Vector__XXX
 SG_ LC_EasyEntryEna : 29|2@0+ (1,0) [0|3] "" Vector__XXX
 SG_ CreepOnOff : 49|2@0+ (1,0) [0|3] "" Vector__XXX
 SG_ TowModOnOff : 33|2@0+ (1,0) [0|3] "" Vector__XXX
 SG_ CargoReq : 27|2@0+ (1,0) [0|3] "" Vector__XXX
 SG_ APAPrkgModReq : 11|4@0+ (1,0) [0|3] "" Vector__XXX
 SG_ HU_09_CRC : 7|8@0+ (1,0) [0|255] "" Vector__XXX
 SG_ PassAirbInhbnReq : 35|2@0+ (1,0) [0|3] "" Vector__XXX
 SG_ HU_09_MsgCntr : 15|4@0+ (1,0) [0|15] "" Vector__XXX
 SG_ CDCUnlockACChrgr : 53|2@0+ (1,0) [0|3] "" Vector__XXX
 SG_ CDC_EPBSwtSts : 46|2@0+ (1,0) [0|3] "" Vector__XXX
 SG_ LC_Deactivation_Request : 31|2@0+ (1,0) [0|3] "" Vector__XXX

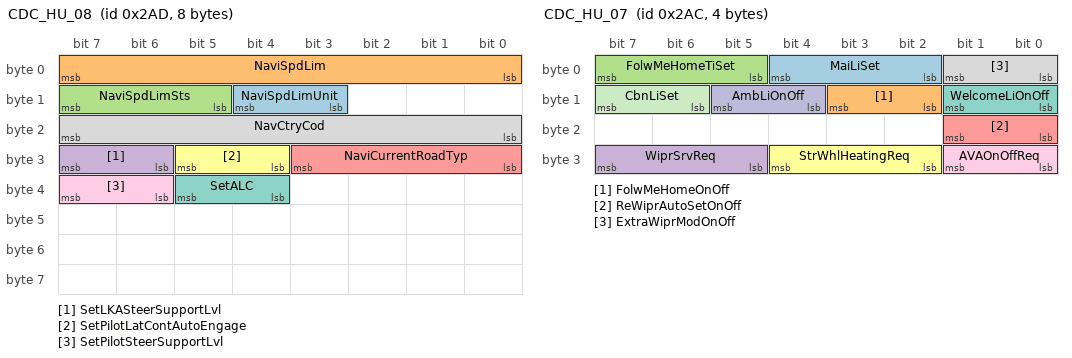
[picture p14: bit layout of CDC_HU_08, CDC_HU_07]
BO_ 685 CDC_HU_08: 8 CGW
 SG_ NaviSpdLimUnit : 12|2@0+ (1,0) [0|3] ""  ADC
 SG_ NaviSpdLim : 7|8@0+ (1,0) [0|255] "km/h"  ADC
 SG_ NaviSpdLimSts : 15|3@0+ (1,0) [0|3] ""  ADC
 SG_ SetLKASteerSupportLvl : 31|2@0+ (1,0) [0|3] ""  ADC
 SG_ NaviCurrentRoadTyp : 27|4@0+ (1,0) [0|7] ""  ADC
 SG_ SetPilotLatContAutoEngage : 29|2@0+ (1,0) [0|3] ""  ADC
 SG_ SetALC : 37|2@0+ (1,0) [0|3] ""  ADC
 SG_ NavCtryCod : 23|8@0+ (1,0) [0|155] ""  ADC
 SG_ SetPilotSteerSupportLvl : 39|2@0+ (1,0) [0|3] ""  ADC

BO_ 684 CDC_HU_07: 4 CGW
 SG_ MaiLiSet : 4|3@0+ (1,0) [0|7] ""  ADC
 SG_ FolwMeHomeOnOff : 11|2@0+ (1,0) [0|3] "" Vector__XXX
 SG_ FolwMeHomeTiSet : 7|3@0+ (1,0) [0|7] "Sec" Vector__XXX
 SG_ WiprSrvReq : 31|3@0+ (1,0) [0|7] "" Vector__XXX
 SG_ ReWiprAutoSetOnOff : 17|2@0+ (1,0) [0|3] "" Vector__XXX
 SG_ StrWhlHeatingReq : 28|3@0+ (1,0) [0|7] "" Vector__XXX
 SG_ WelcomeLiOnOff : 9|2@0+ (1,0) [0|3] "" Vector__XXX
 SG_ ExtraWiprModOnOff : 1|2@0+ (1,0) [0|3] "" Vector__XXX
 SG_ AVAOnOffReq : 25|2@0+ (1,0) [0|3] "" Vector__XXX
 SG_ AmbLiOnOff : 13|2@0+ (1,0) [0|3] "" Vector__XXX
 SG_ CbnLiSet : 15|2@0+ (1,0) [0|3] "" Vector__XXX

BO_ 680 CDC_HU_03: 8 CGW
 SG_ GuestModCdcReq : 37|2@0+ (1,0) [0|3] "" Vector__XXX
 SG_ CDC_HU_03_MsgCntr : 51|4@0+ (1,0) [0|15] ""  ADC
 SG_ DriverAlertSystemOnOff : 5|2@0+ (1,0) [0|3] ""  ADC
 SG_ TSRSpdLimDataOnOff : 17|2@0+ (1,0) [0|3] "" Vector__XXX
 SG_ SetTSR : 19|2@0+ (1,0) [0|3] ""  ADC
 SG_ LCAOnOff : 35|2@0+ (1,0) [0|3] ""  RAD_RR
 SG_ FCWSet : 15|2@0+ (1,0) [0|3] "" Vector__XXX
 SG_ SetLaneAssiAidTyp : 42|3@0+ (1,0) [0|7] ""  ADC
 SG_ CDC_FailSts : 47|2@0+ (1,0) [0|3] ""  ADC
 SG_ CDC_ADAS_FailSts : 45|1@0+ (1,0) [0|1] ""  ADC
 SG_ PCW_PreWarningOnOff : 9|2@0+ (1,0) [0|3] "" Vector__XXX
 SG_ PCW_LatentWarningOnOff : 11|2@0+ (1,0) [0|3] "" Vector__XXX
 SG_ AEBOnOff : 3|2@0+ (1,0) [0|3] ""  ADC
 SG_ DAS_TactileOnOff : 44|2@0+ (1,0) [0|3] ""  ADC
 SG_ LaneAssistTactileOnOff : 28|2@0+ (1,0) [0|3] ""  ADC
 SG_ ACCTauGapStored : 26|3@0+ (1,0) [0|7] ""  ADC
 SG_ SdowOnOffReq : 31|2@0+ (1,0) [0|3] ""  RAD_RR
 SG_ LCATactileWarningOnOff : 33|2@0+ (1,0) [0|3] ""  RAD_RR
 SG_ FCTAOnOffCmd : 7|2@0+ (1,0) [0|3] "" Vector__XXX
 SG_ VldKeyfobChkReq : 1|2@0+ (1,0) [0|3] "" Vector__XXX
 SG_ GoNotifierOnOff : 13|2@0+ (1,0) [0|3] ""  ADC
 SG_ SetHMA : 21|2@0+ (1,0) [0|3] ""  ADC
 SG_ SetLaneAssiSnvty : 54|2@0+ (1,0) [0|3] ""  ADC
 SG_ RCTAReq : 23|2@0+ (1,0) [0|3] ""  RAD_RR
 SG_ CDC_HU_03_CRC : 63|8@0+ (1,0) [0|255] ""  ADC

BO_ 788 CCU_01: 8 CGW
 SG_ CbnACSysSts : 51|1@0+ (1,0) [0|1] "" Vector__XXX
 SG_ CCUActPwrLimEna : 50|1@0+ (1,0) [0|1] "" Vector__XXX
 SG_ PtcReFailSts : 24|1@0+ (1,0) [0|1] "" Vector__XXX
 SG_ PtcTotActPwr : 23|7@0+ (100,0) [0|12700] "W" Vector__XXX
 SG_ PtcFrntFailSts : 54|1@0+ (1,0) [0|1] "" Vector__XXX
 SG_ AmbTemp : 7|8@0+ (0.5,-40) [-40|60] "Deg Cel"  RAD_FL,RAD_RL,APA,RAD_FR,RAD_RR
 SG_ CoolgFanDutyCycReq : 63|8@0+ (0.5,0) [0|100] "%" Vector__XXX
 SG_ CmprOnOffSts : 40|1@0+ (1,0) [0|1] "" Vector__XXX
 SG_ PtcReOnOffSts : 55|1@0+ (1,0) [0|1] "" Vector__XXX
 SG_ PtcTotReqdPwr : 31|7@0+ (100,0) [0|12700] "W" Vector__XXX
 SG_ ComprReqdPwr : 47|7@0+ (100,0) [0|8000] "W" Vector__XXX
 SG_ ComprActPwr : 39|7@0+ (100,0) [0|8000] "W" Vector__XXX
 SG_ PtcFrntOnOffSts : 32|1@0+ (1,0) [0|1] "" Vector__XXX
 SG_ ComprFaultSts : 52|1@0+ (1,0) [0|1] "" Vector__XXX
 SG_ ComprlimSts : 53|1@0+ (1,0) [0|1] "" Vector__XXX
 SG_ PwrLimOfChi : 15|8@0+ (50,0) [0|12750] "" Vector__XXX
 SG_ AmbTempValid : 16|1@0+ (1,0) [0|1] ""  RAD_RL,RAD_FR,APA,RAD_RR,RAD_FL

BO_ 552 CAM_FC_03: 8 ADC
 SG_ HodWarnSeq : 37|3@0+ (1,0) [0|7] ""  CGW
 SG_ LDWLKALaneAssiTyp : 10|3@0+ (1,0) [0|7] ""  CGW
 SG_ AdasLeLine : 3|3@0+ (1,0) [0|7] ""  CGW
 SG_ ACCDecelVis : 27|2@0+ (1,0) [0|3] ""  CGW
 SG_ ACCNPSts : 15|3@0+ (1,0) [0|7] ""  CGW
 SG_ ALCSts : 43|2@0+ (1,0) [0|3] ""  CGW
 SG_ CAM_FC_03_CRC : 63|8@0+ (1,0) [0|255] ""  CGW
 SG_ PilotTarObjTrackingSts : 39|2@0+ (1,0) [0|3] ""  CGW
 SG_ ACCNPDriverMsg : 22|7@0+ (1,0) [0|127] ""  CGW
 SG_ LKSTakeoverReq : 0|1@0+ (1,0) [0|1] ""  CGW
 SG_ PilotLatContAutoEngage : 34|2@0+ (1,0) [0|3] ""  CGW
 SG_ HzrdLiReq : 53|2@0+ (1,0) [0|3] ""  CGW
 SG_ ACCAccrSts : 25|2@0+ (1,0) [0|3] ""  CGW
 SG_ PilotSteerSupportLvl : 41|2@0+ (1,0) [0|3] ""  CGW
 SG_ AdasRiLine : 6|3@0+ (1,0) [0|7] ""  CGW
 SG_ LKASteerSupportLvl : 29|2@0+ (1,0) [0|3] ""  CGW
 SG_ LaneAssiSnvty : 31|2@0+ (1,0) [0|3] ""  CGW
 SG_ LKSSnsvty : 12|2@0+ (1,0) [0|3] ""  CGW
 SG_ FCTAOnOffSts : 47|2@0+ (1,0) [0|3] ""  CGW
 SG_ DoorUnlckReq : 55|2@0+ (1,0) [0|3] ""  CGW
 SG_ ALC : 45|2@0+ (1,0) [0|3] ""  CGW
 SG_ CAM_FC_03_MsgCntr : 51|4@0+ (1,0) [0|15] ""  CGW

BO_ 94 BCU_07: 7 CGW
 SG_ QDCACCFail : 30|2@0+ (1,0) [0|3] "" Vector__XXX
 SG_ ABSActv : 7|1@0+ (1,0) [0|1] ""  APA,RAD_RL,RAD_FL,RAD_RR,RAD_FC,RAD_FR
 SG_ PEDPActv : 20|1@0+ (1,0) [0|1] "" Vector__XXX
 SG_ CDDSActv : 25|1@0+ (1,0) [0|1] "" Vector__XXX
 SG_ VDCDeactv : 5|1@0+ (1,0) [0|1] ""  RAD_RL,RAD_FR,RAD_RR,RAD_FL,RAD_FC
 SG_ AutoBrkgActv : 40|1@0+ (1,0) [0|1] "" Vector__XXX
 SG_ VDCActv : 6|1@0+ (1,0) [0|1] ""  RAD_RL,RAD_FR,RAD_FC,APA,RAD_RR,RAD_FL
 SG_ AVHSts : 23|2@0+ (1,0) [0|3] "" Vector__XXX
 SG_ ABPAvl : 10|1@0+ (1,0) [0|1] "" Vector__XXX
 SG_ AutoBrkgAvl : 41|1@0+ (1,0) [0|1] "" Vector__XXX
 SG_ HRBActv : 35|1@0+ (1,0) [0|1] "" Vector__XXX
 SG_ CDPAvail : 46|1@0+ (1,0) [0|1] "" Vector__XXX
 SG_ ABAAvl : 8|1@0+ (1,0) [0|1] "" Vector__XXX
 SG_ EBDActv : 2|1@0+ (1,0) [0|1] "" Vector__XXX
 SG_ ABPActv : 11|1@0+ (1,0) [0|1] "" Vector__XXX
 SG_ AEBAvl : 12|1@0+ (1,0) [0|1] "" Vector__XXX
 SG_ HBAActv : 31|1@0+ (1,0) [0|1] "" Vector__XXX
 SG_ ECDTTempOffs : 47|1@0+ (1,0) [0|1] "" Vector__XXX
 SG_ HHCActv : 32|1@0+ (1,0) [0|1] "" Vector__XXX
 SG_ AWBAvl : 38|1@0+ (1,0) [0|1] "" Vector__XXX
 SG_ HFCActv : 33|1@0+ (1,0) [0|1] "" Vector__XXX
 SG_ DTCActv : 1|1@0+ (1,0) [0|1] ""  APA,RAD_FC,RAD_RR,RAD_FR,RAD_RL,RAD_FL
 SG_ HDCSts : 18|2@0+ (1,0) [0|3] "" Vector__XXX
 SG_ StandstillSts : 51|3@0+ (1,0) [0|7] "" Vector__XXX
 SG_ EBAActv : 15|1@0+ (1,0) [0|1] "" Vector__XXX
 SG_ AEBActv : 13|1@0+ (1,0) [0|1] "" Vector__XXX
 SG_ AWBActv : 39|1@0+ (1,0) [0|1] "" Vector__XXX
 SG_ ABAActv : 9|1@0+ (1,0) [0|1] "" Vector__XXX
 SG_ TCSDeactv : 3|1@0+ (1,0) [0|1] ""  RAD_FC,RAD_RR,RAD_FR,RAD_RL,RAD_FL
 SG_ CDPActv : 37|1@0+ (1,0) [0|1] "" Vector__XXX
 SG_ EBAAvl : 28|1@0+ (1,0) [0|1] "" Vector__XXX
 SG_ SCMAvl : 26|1@0+ (1,0) [0|1] "" Vector__XXX
 SG_ CDDSAvl : 24|1@0+ (1,0) [0|1] "" Vector__XXX
 SG_ SCMActv : 27|1@0+ (1,0) [0|1] "" Vector__XXX
 SG_ HHCAvail : 45|1@0+ (1,0) [0|1] "" Vector__XXX
 SG_ PEDPAvl : 19|1@0+ (1,0) [0|1] "" Vector__XXX
 SG_ TCSActv : 4|1@0+ (1,0) [0|1] ""  RAD_RL,RAD_RR,RAD_FC,APA,RAD_FR,RAD_FL

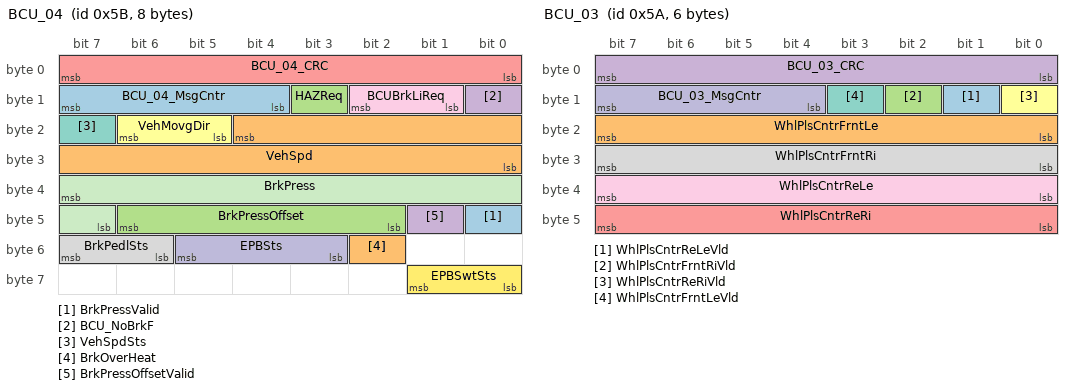
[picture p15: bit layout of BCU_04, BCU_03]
BO_ 91 BCU_04: 8 CGW
 SG_ BrkPressValid : 40|1@0+ (1,0) [0|1] ""  RAD_RL,RAD_RR
 SG_ VehSpd : 20|13@0+ (0.05625,0) [0|360] "km/h"  RAD_FR,APA,RAD_FL,RAD_FC,RAD_RL,RAD_RR
 SG_ BrkPressOffset : 46|5@0+ (1,-15) [-15|15] "Bar"  RAD_RR,RAD_RL
 SG_ BCU_NoBrkF : 8|1@0+ (1,0) [0|1] ""  RAD_FR,RAD_FL,RAD_FC,RAD_RL,RAD_RR
 SG_ BCU_04_CRC : 7|8@0+ (1,0) [0|255] ""  RAD_FR,RAD_RR,RAD_RL,RAD_FC,APA,RAD_FL
 SG_ VehMovgDir : 22|2@0+ (1,0) [0|3] ""  RAD_FC,RAD_RL,RAD_RR,RAD_FL,RAD_FR
 SG_ VehSpdSts : 23|1@0+ (1,0) [0|1] ""  RAD_RL,RAD_RR,RAD_FR,RAD_FL,APA,RAD_FC
 SG_ BrkPedlSts : 55|2@0+ (1,0) [0|3] ""  RAD_RR,RAD_RL
 SG_ BCUBrkLiReq : 10|2@0+ (1,0) [0|3] "" Vector__XXX
 SG_ EPBSts : 53|3@0+ (1,0) [0|7] ""  APA
 SG_ BrkPress : 39|9@0+ (1,-42.5) [-42.5|425.5] "Bar"  RAD_RR,RAD_RL
 SG_ EPBSwtSts : 57|2@0+ (1,0) [0|3] "" Vector__XXX
 SG_ BCU_04_MsgCntr : 15|4@0+ (1,0) [0|15] ""  RAD_RR,RAD_FC,RAD_FL,RAD_RL,APA,RAD_FR
 SG_ BrkOverHeat : 50|1@0+ (1,0) [0|1] "" Vector__XXX
 SG_ HAZReq : 11|1@0+ (1,0) [0|1] "" Vector__XXX
 SG_ BrkPressOffsetValid : 41|1@0+ (1,0) [0|1] ""  RAD_RL,RAD_RR

BO_ 90 BCU_03: 6 CGW
 SG_ WhlPlsCntrReLeVld : 9|1@0+ (1,0) [0|1] ""  RAD_FC,APA
 SG_ WhlPlsCntrFrntLe : 23|8@0+ (1,0) [0|254] "Pulse"  APA,RAD_FC
 SG_ WhlPlsCntrFrntRiVld : 10|1@0+ (1,0) [0|1] ""  RAD_FC,APA
 SG_ BCU_03_CRC : 7|8@0+ (1,0) [0|255] ""  RAD_FC,APA
 SG_ WhlPlsCntrReRi : 47|8@0+ (1,0) [0|254] "Pulse"  APA,RAD_FC
 SG_ WhlPlsCntrReRiVld : 8|1@0+ (1,0) [0|1] ""  APA,RAD_FC
 SG_ WhlPlsCntrFrntLeVld : 11|1@0+ (1,0) [0|1] ""  APA,RAD_FC
 SG_ WhlPlsCntrFrntRi : 31|8@0+ (1,0) [0|254] "Pulse"  APA,RAD_FC
 SG_ WhlPlsCntrReLe : 39|8@0+ (1,0) [0|254] "Pulse"  APA,RAD_FC
 SG_ BCU_03_MsgCntr : 15|4@0+ (1,0) [0|15] ""  APA,RAD_FC

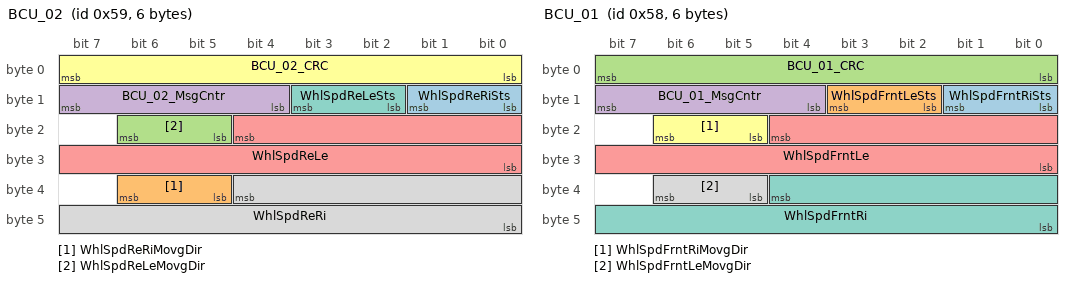
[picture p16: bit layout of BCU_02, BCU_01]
BO_ 89 BCU_02: 6 CGW
 SG_ WhlSpdReRiSts : 9|2@0+ (1,0) [0|3] ""  RAD_FC,RAD_RR,RAD_FL,RAD_FR,RAD_RL,APA
 SG_ WhlSpdReRiMovgDir : 38|2@0+ (1,0) [0|3] ""  RAD_RR,RAD_FC,APA,RAD_FR,RAD_RL,RAD_FL
 SG_ WhlSpdReLeMovgDir : 22|2@0+ (1,0) [0|3] ""  APA,RAD_FC,RAD_RR,RAD_FL,RAD_RL,RAD_FR
 SG_ BCU_02_MsgCntr : 15|4@0+ (1,0) [0|15] ""  RAD_FC,APA,RAD_FL,RAD_RL,RAD_FR,RAD_RR
 SG_ WhlSpdReLe : 20|13@0+ (0.05625,0) [0|360] "km/h"  RAD_RL,RAD_FC,RAD_FL,APA,RAD_RR,RAD_FR
 SG_ BCU_02_CRC : 7|8@0+ (1,0) [0|255] ""  APA,RAD_FL,RAD_RL,RAD_FC,RAD_FR,RAD_RR
 SG_ WhlSpdReLeSts : 11|2@0+ (1,0) [0|3] ""  RAD_RL,RAD_FL,RAD_RR,APA,RAD_FC,RAD_FR
 SG_ WhlSpdReRi : 36|13@0+ (0.05625,0) [0|360] "km/h"  RAD_FC,RAD_FR,RAD_FL,RAD_RL,RAD_RR,APA

BO_ 88 BCU_01: 6 CGW
 SG_ WhlSpdFrntRiSts : 9|2@0+ (1,0) [0|3] ""  RAD_FL,RAD_FC,APA,RAD_RR,RAD_RL,RAD_FR
 SG_ WhlSpdFrntLeSts : 11|2@0+ (1,0) [0|3] ""  RAD_FC,RAD_FR,RAD_RL,APA,RAD_FL,RAD_RR
 SG_ BCU_01_CRC : 7|8@0+ (1,0) [0|255] ""  RAD_FL,RAD_FR,RAD_RL,APA,RAD_FC,RAD_RR
 SG_ BCU_01_MsgCntr : 15|4@0+ (1,0) [0|15] ""  RAD_RL,RAD_RR,APA,RAD_FC,RAD_FR,RAD_FL
 SG_ WhlSpdFrntLe : 20|13@0+ (0.05625,0) [0|360] "km/h"  RAD_FR,RAD_RR,APA,RAD_RL,RAD_FL,RAD_FC
 SG_ WhlSpdFrntRiMovgDir : 22|2@0+ (1,0) [0|3] ""  RAD_RL,RAD_FR,RAD_FL,RAD_RR,APA,RAD_FC
 SG_ WhlSpdFrntRi : 36|13@0+ (0.05625,0) [0|360] "km/h"  RAD_RR,RAD_FC,RAD_FL,RAD_RL,APA,RAD_FR
 SG_ WhlSpdFrntLeMovgDir : 38|2@0+ (1,0) [0|3] ""  RAD_FR,RAD_RR,RAD_RL,APA,RAD_FL,RAD_FC

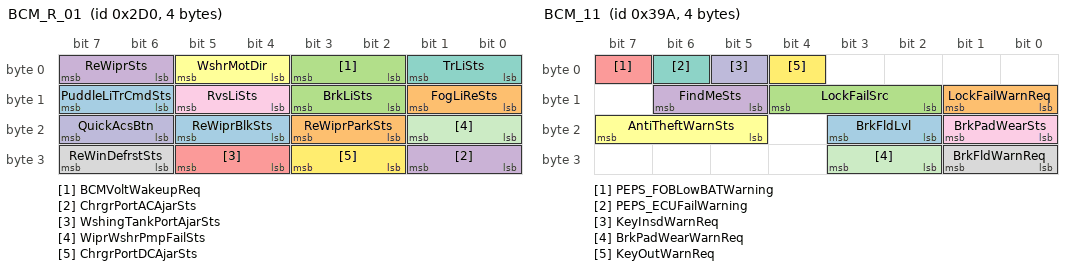
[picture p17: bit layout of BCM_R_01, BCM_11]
BO_ 720 BCM_R_01: 4 CGW
 SG_ PuddleLiTrCmdSts : 15|2@0+ (1,0) [0|3] "" Vector__XXX
 SG_ FogLiReSts : 9|2@0+ (1,0) [0|3] ""  ADC
 SG_ BCMVoltWakeupReq : 3|2@0+ (1,0) [0|3] "" Vector__XXX
 SG_ ChrgrPortACAjarSts : 25|2@0+ (1,0) [0|3] "" Vector__XXX
 SG_ WshingTankPortAjarSts : 29|2@0+ (1,0) [0|3] "" Vector__XXX
 SG_ WshrMotDir : 5|2@0+ (1,0) [0|3] "" Vector__XXX
 SG_ TrLiSts : 1|2@0+ (1,0) [0|3] "" Vector__XXX
 SG_ ReWinDefrstSts : 31|2@0+ (1,0) [0|3] "" Vector__XXX
 SG_ RvsLiSts : 13|2@0+ (1,0) [0|3] "" Vector__XXX
 SG_ QuickAcsBtn : 23|2@0+ (1,0) [0|3] "" Vector__XXX
 SG_ WiprWshrPmpFailSts : 17|2@0+ (1,0) [0|3] "" Vector__XXX
 SG_ ChrgrPortDCAjarSts : 27|2@0+ (1,0) [0|3] "" Vector__XXX
 SG_ ReWiprBlkSts : 21|2@0+ (1,0) [0|3] "" Vector__XXX
 SG_ ReWiprParkSts : 19|2@0+ (1,0) [0|3] "" Vector__XXX
 SG_ BrkLiSts : 11|2@0+ (1,0) [0|3] "" Vector__XXX
 SG_ ReWiprSts : 7|2@0+ (1,0) [0|3] ""  ADC

BO_ 709 BCM_13: 8 CGW
 SG_ TpmsFrntLeWhlTempSts : 8|1@0+ (1,0) [0|1] "" Vector__XXX
 SG_ TpmsFrntLeWhlPressSts : 1|2@0+ (1,0) [0|3] "" Vector__XXX
 SG_ TpmsReLeBatSts : 18|1@0+ (1,0) [0|1] "" Vector__XXX
 SG_ TpmsFrntRiWhlPressSts : 3|2@0+ (1,0) [0|3] "" Vector__XXX
 SG_ TpmsReRiWhlTempSts : 11|1@0+ (1,0) [0|1] "" Vector__XXX
 SG_ TpmsFrntRiWhlTempSts : 9|1@0+ (1,0) [0|1] "" Vector__XXX
 SG_ TpmsReLeWhlDeltaPressSts : 14|1@0+ (1,0) [0|1] ""  ADC
 SG_ TpmsFrntLeBatSts : 16|1@0+ (1,0) [0|1] "" Vector__XXX
 SG_ TpmsReRiBatSts : 19|1@0+ (1,0) [0|1] "" Vector__XXX
 SG_ TpmsReRiSnsrFailSts : 27|1@0+ (1,0) [0|1] "" Vector__XXX
 SG_ TpmsFrntRiBatSts : 17|1@0+ (1,0) [0|1] "" Vector__XXX
 SG_ TpmsFrntLeWhlDeltaPressSts : 12|1@0+ (1,0) [0|1] ""  ADC
 SG_ TpmsReRiWhlPressSts : 7|2@0+ (1,0) [0|3] "" Vector__XXX
 SG_ TpmsFrntLeSnsrFailSts : 24|1@0+ (1,0) [0|1] "" Vector__XXX
 SG_ TpmsReLeWhlPressSts : 5|2@0+ (1,0) [0|3] "" Vector__XXX
 SG_ TpmsReLeWhlTempSts : 10|1@0+ (1,0) [0|1] "" Vector__XXX
 SG_ TpmsSts : 29|2@0+ (1,0) [0|3] "" Vector__XXX
 SG_ TpmsFrntRiSnsrFailSts : 25|1@0+ (1,0) [0|1] "" Vector__XXX
 SG_ TpmsReLeSnsrFailSts : 26|1@0+ (1,0) [0|1] "" Vector__XXX
 SG_ TpmsFrntRiWhlDeltaPressSts : 13|1@0+ (1,0) [0|1] ""  ADC
 SG_ TpmsReRiWhlDeltaPressSts : 15|1@0+ (1,0) [0|1] ""  ADC

BO_ 922 BCM_11: 4 CGW
 SG_ BrkFldLvl : 19|2@0+ (1,0) [0|3] ""  ADC
 SG_ LockFailWarnReq : 9|2@0+ (1,0) [0|1] "" Vector__XXX
 SG_ LockFailSrc : 12|3@0+ (1,0) [0|7] "" Vector__XXX
 SG_ FindMeSts : 14|2@0+ (1,0) [0|3] "" Vector__XXX
 SG_ PEPS_FOBLowBATWarning : 7|1@0+ (1,0) [0|1] "" Vector__XXX
 SG_ AntiTheftWarnSts : 23|3@0+ (1,0) [0|7] "" Vector__XXX
 SG_ PEPS_ECUFailWarning : 6|1@0+ (1,0) [0|1] "" Vector__XXX
 SG_ BrkFldWarnReq : 25|2@0+ (1,0) [0|3] "" Vector__XXX
 SG_ BrkPadWearSts : 17|2@0+ (1,0) [0|3] ""  ADC
 SG_ KeyInsdWarnReq : 5|1@0+ (1,0) [0|1] "" Vector__XXX
 SG_ BrkPadWearWarnReq : 27|2@0+ (1,0) [0|3] "" Vector__XXX
 SG_ KeyOutWarnReq : 4|1@0+ (1,0) [0|1] "" Vector__XXX

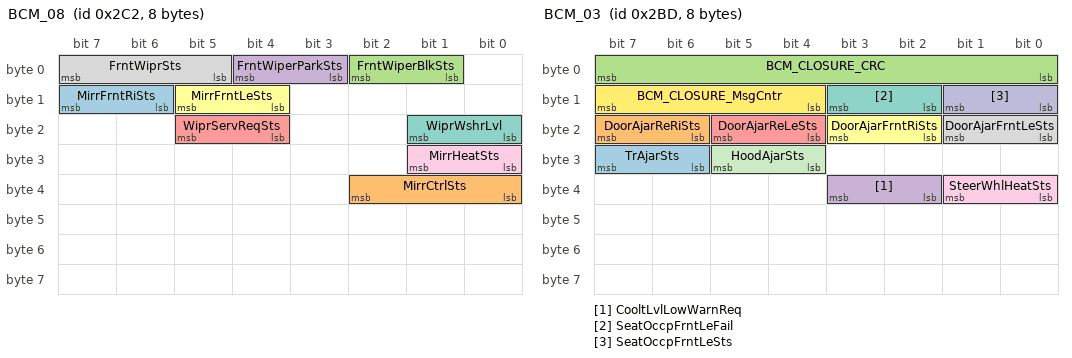
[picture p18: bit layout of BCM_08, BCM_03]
BO_ 706 BCM_08: 8 CGW
 SG_ MirrFrntRiSts : 15|2@0+ (1,0) [0|3] "" Vector__XXX
 SG_ MirrCtrlSts : 34|3@0+ (1,0) [0|7] "" Vector__XXX
 SG_ FrntWiperBlkSts : 2|2@0+ (1,0) [0|3] "" Vector__XXX
 SG_ FrntWiperParkSts : 4|2@0+ (1,0) [0|3] ""  ADC
 SG_ WiprServReqSts : 21|2@0+ (1,0) [0|3] "" Vector__XXX
 SG_ MirrFrntLeSts : 13|2@0+ (1,0) [0|3] "" Vector__XXX
 SG_ WiprWshrLvl : 17|2@0+ (1,0) [0|3] "" Vector__XXX
 SG_ FrntWiprSts : 7|3@0+ (1,0) [0|7] ""  ADC
 SG_ MirrHeatSts : 25|2@0+ (1,0) [0|3] "" Vector__XXX

BO_ 704 BCM_06: 8 CGW
 SG_ ScurKeyInvd : 53|2@0+ (1,0) [0|3] "" Vector__XXX
 SG_ FogLiFrntRiDrvrSts : 21|2@0+ (1,0) [0|3] "" Vector__XXX
 SG_ FogLiFrntSts : 3|2@0+ (1,0) [0|3] ""  ADC
 SG_ WelcomeLiReq : 9|2@0+ (1,0) [0|3] "" Vector__XXX
 SG_ HzrdWarnSts : 11|2@0+ (1,0) [0|3] ""  ADC
 SG_ DrowsinessIndexSts : 43|2@0+ (1,0) [0|3] "" Vector__XXX
 SG_ DrowsinessIndex : 47|4@0+ (1,0) [0|15] "" Vector__XXX
 SG_ RiTurnIndcrLiSts : 15|2@0+ (1,0) [0|3] ""  ADC,RAD_FL,RAD_RL,RAD_FR,RAD_RR
 SG_ LeTurnIndcrLiSts : 13|2@0+ (1,0) [0|3] ""  RAD_RR,ADC,RAD_FR,RAD_RL,RAD_FL
 SG_ PuddleLiFrntLeSts : 25|2@0+ (1,0) [0|3] "" Vector__XXX
 SG_ PuddleLiReLeSts : 29|2@0+ (1,0) [0|3] "" Vector__XXX
 SG_ ImmoAuthWarning : 54|1@0+ (1,0) [0|1] "" Vector__XXX
 SG_ DrowsyWarning : 55|1@0+ (1,0) [0|1] "" Vector__XXX
 SG_ HndlLiSts : 35|2@0+ (1,0) [0|3] "" Vector__XXX
 SG_ LtgPwrSplyEnaSts : 37|2@0+ (1,0) [0|3] "" Vector__XXX
 SG_ LoBeamSts : 5|2@0+ (1,0) [0|3] ""  ADC
 SG_ IntrLiFootWellSts : 33|2@0+ (1,0) [0|3] "" Vector__XXX
 SG_ DASFctSts : 41|2@0+ (1,0) [0|3] "" Vector__XXX
 SG_ HiBeamSts : 7|2@0+ (1,0) [0|3] ""  ADC
 SG_ PosnLiSts : 1|2@0+ (1,0) [0|3] "" Vector__XXX
 SG_ FogLiFrntLeDrvrSts : 19|2@0+ (1,0) [0|3] "" Vector__XXX
 SG_ DayTiRunngLiSts : 17|2@0+ (1,0) [0|3] "" Vector__XXX
 SG_ PuddleLiFrntRiSts : 27|2@0+ (1,0) [0|3] "" Vector__XXX
 SG_ PuddleLiReRiSts : 31|2@0+ (1,0) [0|3] "" Vector__XXX

BO_ 701 BCM_03: 8 CGW
 SG_ TrAjarSts : 31|2@0+ (1,0) [0|3] ""  APA
 SG_ DoorAjarReRiSts : 23|2@0+ (1,0) [0|3] ""  RAD_RR
 SG_ BCM_CLOSURE_CRC : 7|8@0+ (1,0) [0|255] "" Vector__XXX
 SG_ CooltLvlLowWarnReq : 35|2@0+ (1,0) [0|3] "" Vector__XXX
 SG_ DoorAjarReLeSts : 21|2@0+ (1,0) [0|3] ""  RAD_RR
 SG_ DoorAjarFrntRiSts : 19|2@0+ (1,0) [0|3] ""  RAD_RR
 SG_ SeatOccpFrntLeFail : 11|2@0+ (1,0) [0|3] "" Vector__XXX
 SG_ DoorAjarFrntLeSts : 17|2@0+ (1,0) [0|3] ""  APA,RAD_RR
 SG_ SteerWhlHeatSts : 33|2@0+ (1,0) [0|3] "" Vector__XXX
 SG_ SeatOccpFrntLeSts : 9|2@0+ (1,0) [0|3] ""  RAD_RR
 SG_ HoodAjarSts : 29|2@0+ (1,0) [0|3] "" Vector__XXX
 SG_ BCM_CLOSURE_MsgCntr : 15|4@0+ (1,0) [0|15] "" Vector__XXX

CM_ SG_ 537 VCURemainingRng " ";
CM_ SG_ 537 VCUMotOverSpd " ";
CM_ SG_ 537 VCUPwrDisp " ";
CM_ SG_ 537 VCUMotOverTemp " ";
CM_ SG_ 537 VCUImdStopDriving " ";
CM_ SG_ 537 VCUDrvModIndcn " ";
CM_ SG_ 537 VCURmvAcChger " ";
CM_ SG_ 537 DCChrgrPluginSts "DC Chargeing Plugin Status";
CM_ SG_ 537 ACChrgrOverT "AC Charger port over tempature alarm";
CM_ SG_ 537 VehPwrLimdlampReq " vehicle power limited lamp request";
CM_ SG_ 537 VCURgnCpLimdIndcn "VCU regen capacity limited(reserved for ES8 G1.F)";
CM_ SG_ 537 VCUElecLockfail " ";
CM_ SG_ 537 VCUShiftChangefail " ";
CM_ SG_ 537 VCUBrakeRemind " ";
CM_ SG_ 537 VCUVehRdy "Powertrain Ready   ";
CM_ SG_ 537 VCURegenSts " ";
CM_ SG_ 537 DCChrgrOverT "DC Charger port over tempature alarm";
CM_ SG_ 537 HiVoltCntctrSts "VCU high voltage contactor status";
CM_ SG_ 537 ACChrgrPluginSts "AC Chargeing Plugin Status";
CM_ SG_ 537 VCUChrgDispLampReq " ";
CM_ SG_ 537 VCUHVILError " ";
CM_ SG_ 537 ACChrgCurrentRng "AC charging current range";
CM_ SG_ 537 ACChrgCmplSts "AC charging complete status";
CM_ SG_ 537 VCUFourWhlDrvIndcn " ";
CM_ SG_ 537 EPFaultLevelWarning "E Power fault system warning ";
CM_ SG_ 537 VCUChgLineSts " ";
CM_ SG_ 850 LVBattSOCSts "12V battery State of Charge (SOC) status   ";
CM_ SG_ 850 LVBattChgSts "Low battery charging status ";
CM_ SG_ 850 VCUHVBattCutOffWarn "HV battery cut off warning ";
CM_ SG_ 850 LoadShed "Load shed   ";
CM_ SG_ 850 LVBattU "12V battery voltage   ";
CM_ SG_ 850 VCULvBattWarn "Low voltage battery warning ";
CM_ SG_ 850 LVBattSOC "12V battery State of Charge (SOC)   ";
CM_ SG_ 850 LVBattUSts "12V battery voltage status   ";
CM_ SG_ 535 CruiseStatus " ";
CM_ SG_ 535 VCUTargetGearValid " ";
CM_ SG_ 535 VCUActGearValid " ";
CM_ SG_ 535 VCURvsLampReq " ";
CM_ SG_ 535 VCUEPBReq " ";
CM_ SG_ 535 CruiseStoredSpeed " ";
CM_ SG_ 535 VCUPtWakeupReq " ";
CM_ SG_ 535 VCUCruiseCtrlMod "Cruise control mode";
CM_ SG_ 535 VCU_05_CRC " ";
CM_ SG_ 535 VCUTargetGear "VCU target gear   ";
CM_ SG_ 535 VCUActGear "VCU actual gear   ";
CM_ SG_ 535 VCUTqAvl "VCU toqure available";
CM_ SG_ 535 VCUBrkLampReq " ";
CM_ SG_ 535 VCU_05_MsgCntr " ";
CM_ SG_ 68 VCUTotlMotPosTqCp "Total motor positive torque capacity ";
CM_ SG_ 68 VCUTQCSts "VCU TQC Status";
CM_ SG_ 68 VCU_01_CRC "Checksum   ";
CM_ SG_ 68 VCUTotlMotNegTqCp "Total motor negative torque capacity ";
CM_ SG_ 68 VCUTotlMotPosTqCpValid "Total motor positive torque capacity validity ";
CM_ SG_ 68 VCU_01_MsgCntr "Rolling Counter   ";
CM_ SG_ 68 VCUTotlMotNegTqCpValid "Total motor negative torque capacity validity ";
CM_ SG_ 663 FrntWiprInterSpd "Front wiper intermediate speed   ";
CM_ SG_ 663 FrntWiprSwtSts "Front wiper switch status    ";
CM_ SG_ 663 FogLiPushSwtSts "Fog light push switch status    ";
CM_ SG_ 663 WshrAndReWiprPushSwtSts "Washer and rear wiper push switch status    ";
CM_ SG_ 663 SCMFailSts "Steering Column Module (SCM) fail status    ";
CM_ SG_ 663 TurnIndcrSwtSts "Turn indicator switch status (includes lane change)   ";
CM_ SG_ 663 WiprAutModPushSwtSts "Wiper automatic mode switch status    ";
CM_ SG_ 663 HiLowBeamPushSwtSts "High beam flash push switch status    ";
CM_ SG_ 212 SteerWhlAgSpd "Steering wheel angle speed
Invalid value 1FF   ";
CM_ SG_ 212 SteerAgSnsrFailSts "Steering angle sensor fail status    ";
CM_ SG_ 212 SCM_01_CRC "SCM_01 CRC    ";
CM_ SG_ 212 SteerWhlAgDir "Steering wheel angle direction   ";
CM_ SG_ 212 SCM_01_MsgCntr "SCM_01 Message Counter    ";
CM_ SG_ 212 SteerWhlAgSpdDir "Steering wheel angle speed direction   ";
CM_ SG_ 212 SteerWhlAgAndSpdValid "Steering wheel angle and speed validity    ";
CM_ SG_ 212 SteerAgSnsrCalSts "Steering angle sensor calibration status    ";
CM_ SG_ 212 SteerWhlAg "Steering wheel angle
Invalid value 1F41 - 1FFF   ";
CM_ SG_ 168 BSDLCAReLeWarnReq "Blind Spot Detection (BSD) and Lane Change Assist (LCA) rear left warning request   ";
CM_ SG_ 168 RAD_RR_01_MsgCntr "RAD_RR_01 Message Counter    ";
CM_ SG_ 168 ExtReqRAD_RR "External request RAD_RR
Lane Change Assist (LCA) haptic request ";
CM_ SG_ 168 BSDLCAReRiWarnReq "Blind Spot Detection (BSD) and Lane Change Assist (LCA) rear right warning request   ";
CM_ SG_ 168 SdowLeWarnReq "Warning request indicating that the driver/passenger is opening the left side door while the radar has detected an object arriving from the back ";
CM_ SG_ 168 SDOWOnOffSts "Radar internal setting function on off";
CM_ SG_ 168 LCAHapticOnOffSts "LCA(Lane Change Assistant) haptic setting status";
CM_ SG_ 168 BSDLCAOnOffSts "Blind Spot Detection (BSD) and Lane Change Assist (LCA) On Off status
Feedback for illumination (Optional, no receiver)    ";
CM_ SG_ 168 SdowRiWarnReq "Warning request indicating that the passenger is opening the right side door while the radar has detected an object arriving from the back ";
CM_ SG_ 168 CTAReLeWarnReq "(Rear) Cross Traffic Alert (RCTA) rear left (corner) warning request   ";
CM_ SG_ 168 ReRiRSDSDisp "Rear right RDDS display   ";
CM_ SG_ 168 RCTAOnOffSts "Radar internal setting function on off";
CM_ SG_ 168 CTAReRiWarnReq "(Rear) Cross Traffic Alert (RCTA) rear right (corner) warning request   ";
CM_ SG_ 168 RAD_RR_01_CRC "RAD_RR_01 CRC   ";
CM_ SG_ 607 Dummy_RAD_RL "dummy signal used for monitior";
CM_ SG_ 603 Dummy_RAD_FR "dummy signal used for monitior";
CM_ SG_ 160 FrntRiRSDSDisp "Front right radar fault display   ";
CM_ SG_ 160 RAD_FR_01_MsgCntr "RAD_FR_01 message counter   ";
CM_ SG_ 160 CTAFrntRiWarnReq "(Front) Cross Traffic Alert (FCTA) front right  warning request   ";
CM_ SG_ 160 RAD_FR_01_CRC "RAD_FR_01 CRC    ";
CM_ SG_ 599 Dummy_RAD_FL "dummy signal used for monitior";
CM_ SG_ 156 RAD_FL_01_MsgCntr "RAD_FL_01 message counter   ";
CM_ SG_ 156 FrntLeRSDSDisp "Front Left radar fault display   ";
CM_ SG_ 156 CTAFrntLeWarnReq "(Front) Cross Traffic Alert (FCTA) front left warning request
   ";
CM_ SG_ 156 RAD_FL_01_CRC "RAD_FL_01 CRC    ";
CM_ SG_ 567 Dummy_RAD_FC "dummy signal used for monitior";
CM_ SG_ 126 ClsObjTyp "Close object type ";
CM_ SG_ 126 DisplayVelocitySet "The set speed from driver, should be available as long as ACC is active   ";
CM_ SG_ 126 PCWLatentWarnOnOffSts "PCW Latent warning On Off Status";
CM_ SG_ 126 GoNotifierOnOffSts "Radar internal setting for go notifier on off";
CM_ SG_ 126 Textinfo "Text info for driver which is displayed in dashboard   ";
CM_ SG_ 126 TSRSpdLimDataOnOffSts "Radar internal setting TSR speed limit set speed on off status ";
CM_ SG_ 126 AEBSts "Automatic Emergency Braking (AEB) Status Indicated whetheer the function has been switched ON/Off by the driver and  if the function is active (Triggered by RAD_FC)  ";
CM_ SG_ 126 ClsObjDst "Close object distance ";
CM_ SG_ 126 FCWSetSts "FCW setting status";
CM_ SG_ 126 RAD_FC_03_MsgCntr "RAD_FC_03 Message Counter   ";
CM_ SG_ 126 RAD_FC_03_CRC "RAD_FC_03 CRC   ";
CM_ SG_ 126 TakeOverReq "The limits of the ACC control reaches, driver should take over.   ";
CM_ SG_ 126 ObjValid "An ahead target object detected by ACC, to inform the driver.   ";
CM_ SG_ 126 PCWPreWarnOnOffSts "PCW Pre warning On Off Status";
CM_ SG_ 126 ACC_FreeSpaceIntrusion "ACC free space intrusion";
CM_ SG_ 126 ACC_CutInDetected "ACC Cut_in detected";
CM_ SG_ 126 ACCMode "The status of the ACC control unit.
The ACC mode should be contained in every message sent by ACC. ";
CM_ SG_ 126 GoNotifierReq "Go notifier request   ";
CM_ SG_ 126 PCW_latentWarning "Visual warning. Used with PCW_Enable signal   ";
CM_ SG_ 126 TauGapSet "The set timeGap from driver, should be displayed to driver and if the set value changes   ";
CM_ SG_ 126 PCW_preWarning "Acoustic pre warning.Used with PCW_Enable signal.   ";
CM_ SG_ 117 EPS_DrvOverRideDetn "Driver input above torque threshold (defined per interface) detected";
CM_ SG_ 117 EPS_02_MsgCntr "EPS_02 message counter  ";
CM_ SG_ 117 EPS_02_CRC "EPS_02 CRC ";
CM_ SG_ 117 EPS_MotorTq "EPS motor torque(CCW+, CW-)";
CM_ SG_ 117 EPS_EstRackForceValid "EPS estimate rack force valid";
CM_ SG_ 117 EPS_EstRackForce "EPS estimate rack force base on handle(CCW positive, CW negative)";
CM_ SG_ 117 EPS_PinionAg "EPS pinion angle (Invalid value 0x7FFF)
Clock-Wise = Right = Minus
Counter Clock-Wise = Left = Plus
";
CM_ SG_ 117 EPS_PinionAgValid "EPS pinion angle validity ";
CM_ SG_ 117 EPS_MotorTqValid "EPS motor torque validity";
CM_ SG_ 117 EPS_HandsOffDetnConfidence "EPS Hands-Off detection confidence ";
CM_ SG_ 116 EPS_01_CRC "EPS_01 CRC    ";
CM_ SG_ 116 EPS_ActvExtIf "Eletronic Power Steering (EPS) active external interface ";
CM_ SG_ 116 EPS_DrvngMod "EPS driving mode selected     ";
CM_ SG_ 116 EPS_DAIAvl "NP pinion angle overlay request available";
CM_ SG_ 116 EPS_PAIAvl "APA absolute pinion angle request available";
CM_ SG_ 116 EPS_WarnLampReq "Electronic Power Steering (EPS) warning lamp request. Illuminated in case of EPS failure     ";
CM_ SG_ 116 EPSSts "Electronic Power Steering (EPS) status   ";
CM_ SG_ 116 EPS_01_MsgCntr "EPS_01 Message counter    ";
CM_ SG_ 116 EPS_TOIAvl "LKA column torque request available";
CM_ SG_ 116 EPS_TorsBarTq "Driver steering torque
Clock - Wise = Right = Minus
Counter Clock - Wise = Left = Plus";
CM_ SG_ 116 EPS_HIAvl "Haptic warning request available";
CM_ SG_ 116 EPS_TorsBarTqValid "Driver steering torque validity     ";
CM_ SG_ 1698 DiagRespData3_RAD_RR "Diagnostic response data 3 RAD_RR   ";
CM_ SG_ 1698 DiagRespData0_RAD_RR "Diagnostic response data 0 RAD_RR   ";
CM_ SG_ 1698 DiagRespData5_RAD_RR "Diagnostic response data 5 RAD_RR   ";
CM_ SG_ 1698 DiagRespData6_RAD_RR "Diagnostic response data 6 RAD_RR   ";
CM_ SG_ 1698 DiagRespData2_RAD_RR "Diagnostic response data 2 RAD_RR   ";
CM_ SG_ 1698 DiagRespData7_RAD_RR "Diagnostic response data 7 RAD_RR   ";
CM_ SG_ 1698 DiagRespData4_RAD_RR "Diagnostic response data 4 RAD_RR   ";
CM_ SG_ 1698 DiagRespData1_RAD_RR "Diagnostic response data 1 RAD_RR   ";
CM_ SG_ 1697 DiagRespData0_RAD_RL "Diagnostic response data 0 RAD_RL   ";
CM_ SG_ 1697 DiagRespData2_RAD_RL "Diagnostic response data 2 RAD_RL   ";
CM_ SG_ 1697 DiagRespData7_RAD_RL "Diagnostic response data 7 RAD_RL   ";
CM_ SG_ 1697 DiagRespData4_RAD_RL "Diagnostic response data 4 RAD_RL   ";
CM_ SG_ 1697 DiagRespData1_RAD_RL "Diagnostic response data 1 RAD_RL   ";
CM_ SG_ 1697 DiagRespData3_RAD_RL "Diagnostic response data 3 RAD_RL   ";
CM_ SG_ 1697 DiagRespData6_RAD_RL "Diagnostic response data 6 RAD_RL   ";
CM_ SG_ 1697 DiagRespData5_RAD_RL "Diagnostic response data 5 RAD_RL   ";
CM_ SG_ 1696 DiagRespData7_RAD_FR "Diagnostic response data 7 RAD_FR   ";
CM_ SG_ 1696 DiagRespData1_RAD_FR "Diagnostic response data 1 RAD_FR   ";
CM_ SG_ 1696 DiagRespData6_RAD_FR "Diagnostic response data 6 RAD_FR   ";
CM_ SG_ 1696 DiagRespData0_RAD_FR "Diagnostic response data 0 RAD_FR   ";
CM_ SG_ 1696 DiagRespData4_RAD_FR "Diagnostic response data 4 RAD_FR   ";
CM_ SG_ 1696 DiagRespData2_RAD_FR "Diagnostic response data 2 RAD_FR   ";
CM_ SG_ 1696 DiagRespData3_RAD_FR "Diagnostic response data 3 RAD_FR   ";
CM_ SG_ 1696 DiagRespData5_RAD_FR "Diagnostic response data 5 RAD_FR   ";
CM_ SG_ 1695 DiagRespData0_RAD_FL "Diagnostic response data 0 RAD_FL   ";
CM_ SG_ 1695 DiagRespData6_RAD_FL "Diagnostic response data 6 RAD_FL   ";
CM_ SG_ 1695 DiagRespData3_RAD_FL "Diagnostic response data 3 RAD_FL   ";
CM_ SG_ 1695 DiagRespData4_RAD_FL "Diagnostic response data 4 RAD_FL   ";
CM_ SG_ 1695 DiagRespData1_RAD_FL "Diagnostic response data 1 RAD_FL   ";
CM_ SG_ 1695 DiagRespData5_RAD_FL "Diagnostic response data 5 RAD_FL   ";
CM_ SG_ 1695 DiagRespData2_RAD_FL "Diagnostic response data 2 RAD_FL   ";
CM_ SG_ 1695 DiagRespData7_RAD_FL "Diagnostic response data 7 RAD_FL   ";
CM_ SG_ 1694 DiagRespData2_RAD_FC "Diagnostic response data 2 RAD_FC   ";
CM_ SG_ 1694 DiagRespData5_RAD_FC "Diagnostic response data 5 RAD_FC   ";
CM_ SG_ 1694 DiagRespData6_RAD_FC "Diagnostic response data 6 RAD_FC   ";
CM_ SG_ 1694 DiagRespData0_RAD_FC "Diagnostic response data 0 RAD_FC   ";
CM_ SG_ 1694 DiagRespData3_RAD_FC "Diagnostic response data 3 RAD_FC   ";
CM_ SG_ 1694 DiagRespData1_RAD_FC "Diagnostic response data 1 RAD_FC   ";
CM_ SG_ 1694 DiagRespData4_RAD_FC "Diagnostic response data 4 RAD_FC   ";
CM_ SG_ 1694 DiagRespData7_RAD_FC "Diagnostic response data 7 RAD_FC   ";
CM_ SG_ 1700 DiagRespData4_APA "Diagnostic response data 4 APA   ";
CM_ SG_ 1700 DiagRespData2_APA "Diagnostic response data 2 APA   ";
CM_ SG_ 1700 DiagRespData0_APA "Diagnostic response data 0 APA   ";
CM_ SG_ 1700 DiagRespData7_APA "Diagnostic response data 7 APA   ";
CM_ SG_ 1700 DiagRespData3_APA "Diagnostic response data 3 APA   ";
CM_ SG_ 1700 DiagRespData1_APA "Diagnostic response data 1 APA   ";
CM_ SG_ 1700 DiagRespData6_APA "Diagnostic response data 6 APA   ";
CM_ SG_ 1700 DiagRespData5_APA "Diagnostic response data 5 APA   ";
CM_ SG_ 1570 DiagReqData4_RAD_RR "Diagnostic request data 4 RAD_RR   ";
CM_ SG_ 1570 DiagReqData7_RAD_RR "Diagnostic request data 7 RAD_RR   ";
CM_ SG_ 1570 DiagReqData5_RAD_RR "Diagnostic request data 5 RAD_RR   ";
CM_ SG_ 1570 DiagReqData1_RAD_RR "Diagnostic request data 1 RAD_RR   ";
CM_ SG_ 1570 DiagReqData3_RAD_RR "Diagnostic request data 3 RAD_RR   ";
CM_ SG_ 1570 DiagReqData2_RAD_RR "Diagnostic request data 2 RAD_RR   ";
CM_ SG_ 1570 DiagReqData0_RAD_RR "Diagnostic request data 0 RAD_RR   ";
CM_ SG_ 1570 DiagReqData6_RAD_RR "Diagnostic request data 6 RAD_RR   ";
CM_ SG_ 1569 DiagReqData2_RAD_RL "Diagnostic request data 2 RAD_RL   ";
CM_ SG_ 1569 DiagReqData3_RAD_RL "Diagnostic request data 3 RAD_RL   ";
CM_ SG_ 1569 DiagReqData0_RAD_RL "Diagnostic request data 0 RAD_RL   ";
CM_ SG_ 1569 DiagReqData7_RAD_RL "Diagnostic request data 7 RAD_RL   ";
CM_ SG_ 1569 DiagReqData1_RAD_RL "Diagnostic request data 1 RAD_RL   ";
CM_ SG_ 1569 DiagReqData4_RAD_RL "Diagnostic request data 4 RAD_RL   ";
CM_ SG_ 1569 DiagReqData5_RAD_RL "Diagnostic request data 5 RAD_RL   ";
CM_ SG_ 1569 DiagReqData6_RAD_RL "Diagnostic request data 6 RAD_RL   ";
CM_ SG_ 1568 DiagReqData3_RAD_FR "Diagnostic request data 3 RAD_FR   ";
CM_ SG_ 1568 DiagReqData6_RAD_FR "Diagnostic request data 6 RAD_FR   ";
CM_ SG_ 1568 DiagReqData5_RAD_FR "Diagnostic request data 5 RAD_FR   ";
CM_ SG_ 1568 DiagReqData0_RAD_FR "Diagnostic request data 0 RAD_FR   ";
CM_ SG_ 1568 DiagReqData7_RAD_FR "Diagnostic request data 7 RAD_FR   ";
CM_ SG_ 1568 DiagReqData4_RAD_FR "Diagnostic request data 4 RAD_FR   ";
CM_ SG_ 1568 DiagReqData2_RAD_FR "Diagnostic request data 2 RAD_FR   ";
CM_ SG_ 1568 DiagReqData1_RAD_FR "Diagnostic request data 1 RAD_FR   ";
CM_ SG_ 1567 DiagReqData1_RAD_FL "Diagnostic request data 1 RAD_FL   ";
CM_ SG_ 1567 DiagReqData7_RAD_FL "Diagnostic request data 7 RAD_FL   ";
CM_ SG_ 1567 DiagReqData6_RAD_FL "Diagnostic request data 6 RAD_FL   ";
CM_ SG_ 1567 DiagReqData0_RAD_FL "Diagnostic request data 0 RAD_FL   ";
CM_ SG_ 1567 DiagReqData4_RAD_FL "Diagnostic request data 4 RAD_FL   ";
CM_ SG_ 1567 DiagReqData3_RAD_FL "Diagnostic request data 3 RAD_FL   ";
CM_ SG_ 1567 DiagReqData2_RAD_FL "Diagnostic request data 2 RAD_FL   ";
CM_ SG_ 1567 DiagReqData5_RAD_FL "Diagnostic request data 5 RAD_FL   ";
CM_ SG_ 1566 DiagReqData6_RAD_FC "Diagnostic request data 6 RAD_FC   ";
CM_ SG_ 1566 DiagReqData3_RAD_FC "Diagnostic request data 3 RAD_FC   ";
CM_ SG_ 1566 DiagReqData4_RAD_FC "Diagnostic request data 4 RAD_FC   ";
CM_ SG_ 1566 DiagReqData5_RAD_FC "Diagnostic request data 5 RAD_FC   ";
CM_ SG_ 1566 DiagReqData0_RAD_FC "Diagnostic request data 0 RAD_FC   ";
CM_ SG_ 1566 DiagReqData7_RAD_FC "Diagnostic request data 7 RAD_FC   ";
CM_ SG_ 1566 DiagReqData1_RAD_FC "Diagnostic request data 1 RAD_FC   ";
CM_ SG_ 1566 DiagReqData2_RAD_FC "Diagnostic request data 2 RAD_FC   ";
CM_ SG_ 1537 DiagReqData6_AllECU "Diagnostic request data 6 for all ECUs (Functional address mode)   ";
CM_ SG_ 1537 DiagReqData1_AllECU "Diagnostic request data 1 for all ECUs (Functional address mode)   ";
CM_ SG_ 1537 DiagReqData0_AllECU "Diagnostic request data 0 for all ECUs (Functional address mode)   ";
CM_ SG_ 1537 DiagReqData7_AllECU "Diagnostic request data 7 for all ECUs (Functional address mode)   ";
CM_ SG_ 1537 DiagReqData4_AllECU "Diagnostic request data 4 for all ECUs (Functional address mode)   ";
CM_ SG_ 1537 DiagReqData2_AllECU "Diagnostic request data 2 for all ECUs (Functional address mode)   ";
CM_ SG_ 1537 DiagReqData3_AllECU "Diagnostic request data 3 for all ECUs (Functional address mode)   ";
CM_ SG_ 1537 DiagReqData5_AllECU "Diagnostic request data 5 for all ECUs (Functional address mode)   ";
CM_ SG_ 1572 DiagReqData5_APA "Diagnostic request data 5 APA   ";
CM_ SG_ 1572 DiagReqData3_APA "Diagnostic request data 3 APA   ";
CM_ SG_ 1572 DiagReqData4_APA "Diagnostic request data 4 APA   ";
CM_ SG_ 1572 DiagReqData1_APA "Diagnostic request data 1 APA   ";
CM_ SG_ 1572 DiagReqData2_APA "Diagnostic request data 2 APA   ";
CM_ SG_ 1572 DiagReqData0_APA "Diagnostic request data 0 APA   ";
CM_ SG_ 1572 DiagReqData6_APA "Diagnostic request data 6 APA   ";
CM_ SG_ 1572 DiagReqData7_APA "Diagnostic request data 7 APA   ";
CM_ SG_ 946 Yr "Year
Invalid values FF     ";
CM_ SG_ 946 Sec "Second
Reserved 3C - 3E    
Invalid values 3F     ";
CM_ SG_ 946 Min "Minute
Reserved 3C - 3E
Invalid values 3F       ";
CM_ SG_ 946 Day "Day     ";
CM_ SG_ 946 Mth "Month Invalid value F     ";
CM_ SG_ 946 Hr "Hour
Reserved 18 - 1E
Invalid values 1F     ";
CM_ SG_ 700 FogLiSCMCmd "Fog light command    ";
CM_ SG_ 700 ReWiprSCMCmd "Rear wiper command    ";
CM_ SG_ 700 HiBeamSCMCmd "High beam command    ";
CM_ SG_ 705 HeadLampsOn "Headlamp/Low-beam On request(Day Night sensor)";
CM_ SG_ 705 LiSnsrFailSts "Light sensor fail status  ";
CM_ SG_ 705 LiSnsrData "Light sensor    ";
CM_ SG_ 957 BulbOutFogLiFrntLe "Bulb outage fog light front left  ";
CM_ SG_ 957 BulbOutHiBeamRi "Bulb outage high beam right ";
CM_ SG_ 957 BulbOutTurnIndcnFrntLe "Bulb outage turn indication front left  ";
CM_ SG_ 957 BulbOutTrBrkPosnLiReRi "Bulb outage trunk(tailgate) brake position light rear right ";
CM_ SG_ 957 BulbOutDayTiRunngLiFrntLe "Bulb outage (position) daytime running light front left ";
CM_ SG_ 957 BulbOutLoBeamLe "Bulb outage low beam left ";
CM_ SG_ 957 BulbOutFenderBrkPosnLiReRi "Bulb outage fender brake position light rear right ";
CM_ SG_ 957 BulbOutTrBrkPosnLiReLe "Bulb outage trunk(tailgate) brake position light rear left ";
CM_ SG_ 957 BulbOutFogLiFrntRi "Bulb outage fog light front right ";
CM_ SG_ 957 BulbOutLoBeamRi "Bulb outage low beam right ";
CM_ SG_ 957 BulbOutHiBeamLe "Bulb outage high beam left ";
CM_ SG_ 957 BulbOutResvLiLe "Bulb outage reserve light left ";
CM_ SG_ 957 BulbOutTurnIndcnReRi "Bulb outage turn indication rear right ";
CM_ SG_ 957 BulbOutFogLiReRi "Bulb outage fog light rear right ";
CM_ SG_ 957 BulbOutBrkLiTop "Bulb outage top brake light(CHMSL) ";
CM_ SG_ 957 BulbOutTurnIndcnFrntRi "Bulb outage turn indication front right ";
CM_ SG_ 957 BulbOutTurnIndcnReLe "Bulb outage turn indication rear left  ";
CM_ SG_ 957 BulbOutFogLiReLe "Bulb outage fog light rear left  ";
CM_ SG_ 957 BulbOutDayTiRunngLiFrntRi "Bulb outage (position) daytime running light front right ";
CM_ SG_ 957 BulbOutFenderBrkPosnLiReLe "Bulb outage fender brake position light rear left ";
CM_ SG_ 957 BulbOutResvLiRi "Bulb outage reserve light right ";
CM_ SG_ 707 KeyPrsntSts "Key present status";
CM_ SG_ 707 ImobEnaReq "Immobilizer enable request to WLC";
CM_ SG_ 707 ComfEna "Comfort enable  ";
CM_ SG_ 707 FOTAHvPwrMgnt "FOTA high voltage power management.
This signal only be used under FOTA(VehState equal to Software update)";
CM_ SG_ 707 ImobSts "Immobilizer status    ";
CM_ SG_ 707 VehState "Vehicle state (Replaces vehicle power mode)   ";
CM_ SG_ 707 KeyAuthSts "key authentication status    ";
CM_ SG_ 737 AirbLampFailSts "Airbag lamp fail status     ";
CM_ SG_ 737 AirbPassLampFailSts "Airbag passenger lamp fail status     ";
CM_ SG_ 737 VehDispdSpd "Vehicle displayed speed. Invalid values 1901 - 1FFF     ";
CM_ SG_ 737 IC_VideoSrcReq "CDC LVDS video source request";
CM_ SG_ 938 VehOdometer "Vehicle odometer
Invalid value FFFFFF     ";
CM_ SG_ 686 TowModActv "Tow mode request ";
CM_ SG_ 686 ACChrgCurrentLimReq "AC charging current limit request";
CM_ SG_ 686 HVPwrInhbReq "High voltage inhibit request";
CM_ SG_ 686 HMIStopChargingReq "HMI stop charging request";
CM_ SG_ 686 UPAReq "Ultrasonic Park Assist (UPA) request  ";
CM_ SG_ 686 HillDescentControlReq "Hill Descent Control setting    ";
CM_ SG_ 686 ESCAndTCSReq "Electronic Stability Control setting    ";
CM_ SG_ 686 APAReq "Advanced Parking Assist setting    ";
CM_ SG_ 686 TowEPBReq "Tow EPB request ";
CM_ SG_ 686 LC_EasyEntryEna "Easy Entry Level enable
(Enable the easy entry level when conditions are fulfilled)    ";
CM_ SG_ 686 CreepOnOff "Creeping On Off request ";
CM_ SG_ 686 TowModOnOff "Tow mode request On Off ";
CM_ SG_ 686 CargoReq "Cargo request ";
CM_ SG_ 686 APAPrkgModReq "Advanced Park Assist (APA) parking mode request  ";
CM_ SG_ 686 HU_09_CRC "CDC_HU_09 CRC  ";
CM_ SG_ 686 PassAirbInhbnReq "Passenger airbag inhibition request    ";
CM_ SG_ 686 HU_09_MsgCntr "CDC_HU_09 message counter  ";
CM_ SG_ 686 CDCUnlockACChrgr "CDC unlock AC charging";
CM_ SG_ 686 CDC_EPBSwtSts "CDC EPB switch status (command from central screen) ";
CM_ SG_ 686 LC_Deactivation_Request "Request for Level Control deactivation    ";
CM_ SG_ 685 NaviSpdLimUnit "Navigation speed limit unit    ";
CM_ SG_ 685 NaviSpdLim "Navigation speed limit Invalid value FF    ";
CM_ SG_ 685 NaviSpdLimSts "Navigation speed limit status    ";
CM_ SG_ 685 SetLKASteerSupportLvl "This signal allows the driver to set the strength of the torque jerk that 
is applied to the steering wheel when a LKA event is being triggered.";
CM_ SG_ 685 NaviCurrentRoadTyp "Navigation current road type    ";
CM_ SG_ 685 SetPilotLatContAutoEngage "'AUTO' means that there is a special state in L2-Pilot with only longitudinal control 
(called 'Lateral Unavailable') out of which the system can automatically switch back into 'Pilot Active'
 once there is a new lateral control target.
'MANUAL' means there is no such state and whenever the lateral control targets are lost, 
the system switches from 'Pilot Active' to 'ACC Active'.";
CM_ SG_ 685 SetALC "This setting defines whether or not Auto Lane Change for L2-Pilot shall be active or not and in case it is active,
 what kind of user input is required to trigger it.";
CM_ SG_ 685 NavCtryCod "Navigation country code    ";
CM_ SG_ 685 SetPilotSteerSupportLvl "This signal allows the driver to set how strict L2-Pilot does the lane centering.
 In 'light' mode, it is very easy for the driver to move the vehicle off ceter and he will only feel light resistence by the steering wheel when doing so.
 In 'strong' mode, it will feel as if the vehicle is driving on rails and the driver needs to apply considerable force to get the vehicle off center.";
CM_ SG_ 684 MaiLiSet "Main light set  ";
CM_ SG_ 684 FolwMeHomeOnOff "Follow me home On Off  ";
CM_ SG_ 684 FolwMeHomeTiSet "Follow me home time set  ";
CM_ SG_ 684 WiprSrvReq "Wiper service request Enables the driver to change wipers  ";
CM_ SG_ 684 ReWiprAutoSetOnOff "Rear wiper auto set On Off  ";
CM_ SG_ 684 StrWhlHeatingReq "Steering wheel heating setting    ";
CM_ SG_ 684 WelcomeLiOnOff "Welcome light On Off  ";
CM_ SG_ 684 ExtraWiprModOnOff "Extra wiper mode On Off  ";
CM_ SG_ 684 AVAOnOffReq "Acoustic Vehicle Alert (AVA) On Off request  ";
CM_ SG_ 684 AmbLiOnOff "Ambient light On Off   ";
CM_ SG_ 684 CbnLiSet "Cabine ligh setting
Define if cabin ligth are enabled if door openened ";
CM_ SG_ 680 GuestModCdcReq "Guest Mode selection";
CM_ SG_ 680 CDC_HU_03_MsgCntr "CDC_HU_03 message counter  ";
CM_ SG_ 680 DriverAlertSystemOnOff "If driver sleepy based on steering angle input    ";
CM_ SG_ 680 TSRSpdLimDataOnOff "ACC used speed limit data from TST (On Off)   ";
CM_ SG_ 680 SetTSR "Set Traffic Sign Recognition (TSR)    ";
CM_ SG_ 680 LCAOnOff "Set Change Assist (LCA). Includes blind spot detection    ";
CM_ SG_ 680 FCWSet "Set Forward Collision Warning (FCW)    ";
CM_ SG_ 680 SetLaneAssiAidTyp "Set Lane Assist (LA) aid type    

Via this setting the user can choose a steering wheel reaction when an unintended lane departure has been detected. This can either be a vibration (LDW) or a torque impulse, which also pulls the vehicle back towards the lane center (LKA).";
CM_ SG_ 680 CDC_FailSts "CDC failure status (internal)";
CM_ SG_ 680 CDC_ADAS_FailSts "CDC ADAS failure status
Set to Failure if CDC detects communication error with ADAS ECUs (for the moment only RAD_FC)";
CM_ SG_ 680 PCW_PreWarningOnOff "Pre Collision Warning (PCW) pre-warning On Off   ";
CM_ SG_ 680 PCW_LatentWarningOnOff "Pre Collision Warning (PCW) latent warning On Off   ";
CM_ SG_ 680 AEBOnOff "(Automatic Emergenvy Braking (AEB) system On Off   ";
CM_ SG_ 680 DAS_TactileOnOff "DAS tactile On Off ";
CM_ SG_ 680 LaneAssistTactileOnOff "Lane assist tactile On Off  ";
CM_ SG_ 680 ACCTauGapStored "ACC Tau gap stored  ";
CM_ SG_ 680 SdowOnOffReq "Enable/disable Sdow function. This function is used to warn the front passengers when they are opening the door while an object approaching at the back is detected by the radar. ";
CM_ SG_ 680 LCATactileWarningOnOff "lane Change Assit (LCA) tactile warning On Off  ";
CM_ SG_ 680 FCTAOnOffCmd "Set Front Cross Traffic Alert (FCTA)    ";
CM_ SG_ 680 VldKeyfobChkReq "Valid keyfob check request";
CM_ SG_ 680 GoNotifierOnOff "Go notifier On Off   ";
CM_ SG_ 680 SetHMA "Set High Beam Assist (HMA)    ";
CM_ SG_ 680 SetLaneAssiSnvty "Set Lane Assist (LA) sensitivity    ";
CM_ SG_ 680 RCTAReq "Rear Cross Traffic Alert setting    ";
CM_ SG_ 680 CDC_HU_03_CRC "CDC_HU_03 CRC  ";
CM_ SG_ 788 CbnACSysSts "Cabin AC system status";
CM_ SG_ 788 CCUActPwrLimEna "CCU actual power limited enable";
CM_ SG_ 788 PtcReFailSts "PTC rear failure status  ";
CM_ SG_ 788 PtcTotActPwr "PTC total actual power (PTC front and rear)  ";
CM_ SG_ 788 PtcFrntFailSts "PTC front failure status  ";
CM_ SG_ 788 AmbTemp "Ambient temperature (outside vehicle)    ";
CM_ SG_ 788 CoolgFanDutyCycReq "Cooling fan duty cycle (PWM) request  ";
CM_ SG_ 788 CmprOnOffSts "Compressor On Off status  ";
CM_ SG_ 788 PtcReOnOffSts "PTC rear On Off status  ";
CM_ SG_ 788 PtcTotReqdPwr "PTC total requested power (PTC front and rear)  ";
CM_ SG_ 788 ComprReqdPwr "Compressor requested electric power  ";
CM_ SG_ 788 ComprActPwr "Compressor actual electric power  ";
CM_ SG_ 788 PtcFrntOnOffSts "PTC front On Off status  ";
CM_ SG_ 788 ComprFaultSts "Compressor fault status  ";
CM_ SG_ 788 ComprlimSts "Compressor rpm limit status";
CM_ SG_ 788 PwrLimOfChi "Limited power of chillier";
CM_ SG_ 788 AmbTempValid "Ambient temperature (outside vehicle) validity  ";
CM_ SG_ 552 HodWarnSeq "'This signal triggers the visualizations and audio warnings in CDC for the various levels in the hands-off escalation sequence.";
CM_ SG_ 552 LDWLKALaneAssiTyp "Lane Keeping Assist (LKS) type of assistance Feedback from HU command.";
CM_ SG_ 552 AdasLeLine "Lane Keeping System (LKS) left tracking status.";
CM_ SG_ 552 ACCDecelVis "ACC HMI related.";
CM_ SG_ 552 ACCNPSts "This signal shows the status of the ACC/L2-Pilot system";
CM_ SG_ 552 ALCSts "This signal informs the NIO Pilot static HMI about the curent status of the ALC feature, so that it can display a respective status symbol if needed.";
CM_ SG_ 552 CAM_FC_03_CRC "CAM_FC_03 CRC  ";
CM_ SG_ 552 PilotTarObjTrackingSts "This signal indicates whether or not the longitudinal control target 
is also used as a lateral control target at the same time.";
CM_ SG_ 552 ACCNPDriverMsg "ACC NIO pilot driver message";
CM_ SG_ 552 LKSTakeoverReq "Lane Keeping System (LKS) Take over request    ";
CM_ SG_ 552 PilotLatContAutoEngage "This is ADC's confirmation to {SetPilotLatContAutoEngage} on CDC_HC_03";
CM_ SG_ 552 HzrdLiReq "This is used in the hands-off escalation sequence: When the driver is not taking back 
control after being warned several times and the vehicle is starting to decelerate, 
then ADC will send a trigger to activate the hazard lights.";
CM_ SG_ 552 ACCAccrSts "ACC HMI shall indicate when the vehicle is requesting deceleration.";
CM_ SG_ 552 PilotSteerSupportLvl "This signal allows the driver to set how strict L2-Pilot does the lane centering.
 In 'light' mode, it is very easy for the driver to move the vehicle off ceter and he will only feel light resistence by the steering wheel when doing so. 
In 'strong' mode, it will feel as if the vehicle is driving on rails and the driver needs to apply considerable force to get the vehicle off center.";
CM_ SG_ 552 AdasRiLine "Lane Keeping System (LKS) right tracking status ";
CM_ SG_ 552 LKASteerSupportLvl "This is ADC's confirmation to {SetLKASteerSupportLvl} on CDC_HC_03";
CM_ SG_ 552 LaneAssiSnvty "This is ADC's confirmation to {SetLaneAssiSnvty} on CDC_HC_03";
CM_ SG_ 552 LKSSnsvty "Lane Keeping Assist (LKS) sensitivity Feedback from HU command    ";
CM_ SG_ 552 FCTAOnOffSts "this is a confirmation to signal  FCTAOnOffCmd";
CM_ SG_ 552 DoorUnlckReq "This is used in the hands-off escalation sequence: When the driver is not taking back control
 after being warned several times and the vehile has been braught to a standstill, 
then ADC will send a trigger to unlock the doors.";
CM_ SG_ 552 ALC "This setting defines whether or not Auto Lane Change for L2-Pilot shall be active or not and in case it is active, what kind of user input is required to trigger it.";
CM_ SG_ 552 CAM_FC_03_MsgCntr "CAM_FC_03 message counter  ";
CM_ SG_ 94 QDCACCFail "Error detected by ESC for MRR (ACC and AEB) in CAN frame information  such as Timeout, invalid values, CRC or alive counter.  ";
CM_ SG_ 94 ABSActv "Antilock Brake System (ABS) active      ";
CM_ SG_ 94 PEDPActv "Pedestrian Protection (PEDP) active (Reserved and BCU should send value 0)  ";
CM_ SG_ 94 CDDSActv "Controlled Deceleration for DAS (Driver Assistant System) active   ";
CM_ SG_ 94 VDCDeactv "Vehicle Dynamic Control (VDC) deactivated.     ";
CM_ SG_ 94 AutoBrkgActv "Automatic braking Active
Gathers all kind of automatic braking intervention e.g. AEB, SCM, PEDP, etc. 
if AEBActv or SCMActv or PEDPActv is active, this signal is active";
CM_ SG_ 94 VDCActv "Vehicle Dynamic Control (VDC) active   ";
CM_ SG_ 94 AVHSts "Automatic Vehicle Hold (AVH) status";
CM_ SG_ 94 ABPAvl "Automatic Brake Prefill (EBP) available   ";
CM_ SG_ 94 AutoBrkgAvl "Automatic braking available
Gathers all kind of automatic braking intervention e.g. AEB, SCM, PEDP, etc.
if AEBAvl or SCMAvl or PEDPAvl is active, this signal is active";
CM_ SG_ 94 HRBActv "Hydraulic Rear wheel Boost (HRB) active      ";
CM_ SG_ 94 CDPAvail "Controlled Deceleration for Parking brake (CDP) available      ";
CM_ SG_ 94 ABAAvl "Adaptive Brake Assist (ABA) available      ";
CM_ SG_ 94 EBDActv "Electronic Brake Distribution (EBD) active      ";
CM_ SG_ 94 ABPActv "Automatic Brake Prefill (EBP) active   ";
CM_ SG_ 94 AEBAvl "Automatic Emergency Braking (AEB) available (Reserved and BCU should send value 0) ";
CM_ SG_ 94 HBAActv "Hydraulic Brake Assist (HBA) active
EBA (Emergency Brake Assist?) or deceleration support in ADAS request   ";
CM_ SG_ 94 ECDTTempOffs "ECDT temperature offset      ";
CM_ SG_ 94 HHCActv "Hill Hold Control (HHC) active ";
CM_ SG_ 94 AWBAvl "Automatic Warn Braking (AWB) available      ";
CM_ SG_ 94 HFCActv "Hydraulic Fading Compensation (HFC) active      ";
CM_ SG_ 94 DTCActv "Drag Torque Control (DTC) active    ";
CM_ SG_ 94 HDCSts "Hill Descent Control (HDC) status";
CM_ SG_ 94 StandstillSts "Styandstill status from Brake (not wheel speed)   ";
CM_ SG_ 94 EBAActv "Emergency Brake Assist (EBA) active      ";
CM_ SG_ 94 AEBActv "Automatic Emergency Braking (AEB) active (Reserved and BCU should send value 0)  ";
CM_ SG_ 94 AWBActv "Automatic Warn Braking (AWB) active      ";
CM_ SG_ 94 ABAActv "Adaptive Brake assist (ABA) active      ";
CM_ SG_ 94 TCSDeactv "Traction Control System (TCS) active   ";
CM_ SG_ 94 CDPActv "Controled Deceleration for Parking brake (CDP) active      ";
CM_ SG_ 94 EBAAvl "Emergency Brake Assist (EBA) available      ";
CM_ SG_ 94 SCMAvl "Secondary Colision Mitigation (SCM) available (Reserved and BCU should send value 0)   ";
CM_ SG_ 94 CDDSAvl "Controlled Deceleration for DAS (Driver Assistant System) available     ";
CM_ SG_ 94 SCMActv "Secondary Colision Mitigation (SCM) active (Reserved and BCU should send value 0)  ";
CM_ SG_ 94 HHCAvail "Hill Hold Control (HHC) available      ";
CM_ SG_ 94 PEDPAvl "Pedestrian Protection (PEDP) available (Reserved and BCU should send value 0) ";
CM_ SG_ 94 TCSActv "Traction Control System (TCS) active   ";
CM_ SG_ 91 BrkPressValid "Brake pressure Validity      ";
CM_ SG_ 91 VehSpd "Vehicle speed. Invalid values 1901 - 1FFF      ";
CM_ SG_ 91 BrkPressOffset "Brake Pressure Offset.Required by Front Radar. What does it mean?      ";
CM_ SG_ 91 BCU_NoBrkF "No brake force applied on the wheel or No brake pressure applied?      ";
CM_ SG_ 91 BCU_04_CRC "BCU_04 CRC      ";
CM_ SG_ 91 VehMovgDir "Vehicle moving direction      ";
CM_ SG_ 91 VehSpdSts "Vehicle speed validity and initialization status      ";
CM_ SG_ 91 BrkPedlSts "Brake pedal status.      ";
CM_ SG_ 91 BCUBrkLiReq "BCU brake light request      ";
CM_ SG_ 91 EPBSts "Electric Park Brake (EPB) status      ";
CM_ SG_ 91 BrkPress "Brake Pressure Invalid values 0x1D5 - 0x1FF      ";
CM_ SG_ 91 EPBSwtSts "Electric Park Brake (EPB) switch status      ";
CM_ SG_ 91 BCU_04_MsgCntr "BCU_04 Message counter      ";
CM_ SG_ 91 BrkOverHeat "Brake overheat   ";
CM_ SG_ 91 HAZReq "Hazard warning (HAZ) request      ";
CM_ SG_ 91 BrkPressOffsetValid "Brake pressure offset validity      ";
CM_ SG_ 90 WhlPlsCntrReLeVld "Wheel pluse counter rear left valid      ";
CM_ SG_ 90 WhlPlsCntrFrntLe "Wheel pluse counter front left       ";
CM_ SG_ 90 WhlPlsCntrFrntRiVld "Wheel pluse counter front right valid      ";
CM_ SG_ 90 BCU_03_CRC "BCU_03 CRC      ";
CM_ SG_ 90 WhlPlsCntrReRi "Wheel pluse counter rear right       ";
CM_ SG_ 90 WhlPlsCntrReRiVld "Wheel pluse counter rear right valid      ";
CM_ SG_ 90 WhlPlsCntrFrntLeVld "Wheel pluse counter front left valid      ";
CM_ SG_ 90 WhlPlsCntrFrntRi "Wheel pluse counter front right       ";
CM_ SG_ 90 WhlPlsCntrReLe "Wheel pluse counter rear left       ";
CM_ SG_ 90 BCU_03_MsgCntr "BCU_03 Message counter      ";
CM_ SG_ 89 WhlSpdReRiSts "Wheel speed rear left validity and initialization status      ";
CM_ SG_ 89 WhlSpdReRiMovgDir "Wheel speed rear right moving direction      ";
CM_ SG_ 89 WhlSpdReLeMovgDir "Wheel speed rear left moving direction      ";
CM_ SG_ 89 BCU_02_MsgCntr "BCU_02 Message counter      ";
CM_ SG_ 89 WhlSpdReLe "Wheel speed rear left. Invalid values 1901 - 1FFF      ";
CM_ SG_ 89 BCU_02_CRC "BCU_02 CRC      ";
CM_ SG_ 89 WhlSpdReLeSts "Wheel speed rear left validity and initialization status      ";
CM_ SG_ 89 WhlSpdReRi "Wheel speed rear right. Invalid values 1901 - 1FFF      ";
CM_ SG_ 88 WhlSpdFrntRiSts "Wheel speed front right validity and initialization status      ";
CM_ SG_ 88 WhlSpdFrntLeSts "Wheel speed front left validity and initialization status      ";
CM_ SG_ 88 BCU_01_CRC "BCU_01 CRC      ";
CM_ SG_ 88 BCU_01_MsgCntr "BCU_01 Message counter      ";
CM_ SG_ 88 WhlSpdFrntLe "Wheel speed front left. Invalid values 1901 - 1FFF      ";
CM_ SG_ 88 WhlSpdFrntRiMovgDir "Wheel speed front right moving direction      ";
CM_ SG_ 88 WhlSpdFrntRi "Wheel speed front right. Invalid values 1901 - 1FFF      ";
CM_ SG_ 88 WhlSpdFrntLeMovgDir "Wheel speed front left moving direction      ";
CM_ SG_ 720 PuddleLiTrCmdSts "Puddle light trunk command status ";
CM_ SG_ 720 FogLiReSts "Fog light rear status    ";
CM_ SG_ 720 BCMVoltWakeupReq "BCM volt wakeup request";
CM_ SG_ 720 ChrgrPortACAjarSts "AC Charger port status";
CM_ SG_ 720 WshingTankPortAjarSts "Washing tank port ajar status";
CM_ SG_ 720 WshrMotDir "Washer motor direction  ";
CM_ SG_ 720 TrLiSts "Trunk light status ";
CM_ SG_ 720 ReWinDefrstSts "Rear window defrost status";
CM_ SG_ 720 RvsLiSts "Reverse light status    ";
CM_ SG_ 720 QuickAcsBtn "Quick access button ";
CM_ SG_ 720 WiprWshrPmpFailSts "Wiper washer pump fail status    ";
CM_ SG_ 720 ChrgrPortDCAjarSts "DC Charger port status";
CM_ SG_ 720 ReWiprBlkSts "Rear wiper block status    ";
CM_ SG_ 720 ReWiprParkSts "Rear wiper park position status    ";
CM_ SG_ 720 BrkLiSts "Brake light status    ";
CM_ SG_ 720 ReWiprSts "Rear wiper status    ";
CM_ SG_ 709 TpmsFrntLeWhlTempSts "Tire Pressure Monitoring System (TPMS) front left wheel temperature status    ";
CM_ SG_ 709 TpmsFrntLeWhlPressSts "Tire Pressure Monitoring System (TPMS) front left wheel pressure status    ";
CM_ SG_ 709 TpmsReLeBatSts "Tire Pressure Monitoring System (TPMS) rear left battery status  ";
CM_ SG_ 709 TpmsFrntRiWhlPressSts "Tire Pressure Monitoring System (TPMS) front right wheel pressure status    ";
CM_ SG_ 709 TpmsReRiWhlTempSts "Tire Pressure Monitoring System (TPMS) rear rightt wheel temperature status    ";
CM_ SG_ 709 TpmsFrntRiWhlTempSts "Tire Pressure Monitoring System (TPMS) front right wheel temperature status    ";
CM_ SG_ 709 TpmsReLeWhlDeltaPressSts "Tire Pressure Monitoring System (TPMS) rear left wheel delta pressure status
(Fast leakage)   ";
CM_ SG_ 709 TpmsFrntLeBatSts "Tire Pressure Monitoring System (TPMS) front left battery status  ";
CM_ SG_ 709 TpmsReRiBatSts "Tire Pressure Monitoring System (TPMS) rear right sensor status  ";
CM_ SG_ 709 TpmsReRiSnsrFailSts "Tire Pressure Monitoring System (TPMS) rear right battery status  ";
CM_ SG_ 709 TpmsFrntRiBatSts "Tire Pressure Monitoring System (TPMS) front right battery status  ";
CM_ SG_ 709 TpmsFrntLeWhlDeltaPressSts "Tire Pressure Monitoring System (TPMS) front left wheel delta pressure status
(Fast leakage)  ";
CM_ SG_ 709 TpmsReRiWhlPressSts "Tire Pressure Monitoring System (TPMS) rear right wheel pressure status    ";
CM_ SG_ 709 TpmsFrntLeSnsrFailSts "Tire Pressure Monitoring System (TPMS) front left sensor status  ";
CM_ SG_ 709 TpmsReLeWhlPressSts "Tire Pressure Monitoring System (TPMS) rear left wheel pressure status    ";
CM_ SG_ 709 TpmsReLeWhlTempSts "Tire Pressure Monitoring System (TPMS) rear left wheel temperature status    ";
CM_ SG_ 709 TpmsSts "Tire Pressure Monitoring System (TPMS) status    ";
CM_ SG_ 709 TpmsFrntRiSnsrFailSts "Tire Pressure Monitoring System (TPMS) front right sensor status  ";
CM_ SG_ 709 TpmsReLeSnsrFailSts "Tire Pressure Monitoring System (TPMS) rear left sensor status  ";
CM_ SG_ 709 TpmsFrntRiWhlDeltaPressSts "Tire Pressure Monitoring System (TPMS) front right wheel delta pressure status
(Fast leakage)";
CM_ SG_ 709 TpmsReRiWhlDeltaPressSts "Tire Pressure Monitoring System (TPMS) rear right wheel delta pressure status
(Fast leakage)    ";
CM_ SG_ 922 BrkFldLvl "Brake fluid level    ";
CM_ SG_ 922 LockFailWarnReq "Lock failed due to not matching locking condition e.g. driving mode, door opened, etc.  ";
CM_ SG_ 922 LockFailSrc "If two failure source occurs at the same time, priority is defined in BCM i.e. only one reason is sent.  ";
CM_ SG_ 922 FindMeSts "FindMe function status";
CM_ SG_ 922 PEPS_FOBLowBATWarning "key low battery status warning    ";
CM_ SG_ 922 AntiTheftWarnSts "anti theft warning status    ";
CM_ SG_ 922 PEPS_ECUFailWarning "PEPS ECU Fail Warning    ";
CM_ SG_ 922 BrkFldWarnReq "Brake fluid level warning request ";
CM_ SG_ 922 BrkPadWearSts "Brake pad wear status    ";
CM_ SG_ 922 KeyInsdWarnReq "Valid key detected inside vehicle    ";
CM_ SG_ 922 BrkPadWearWarnReq "Brake pad wear warning request ";
CM_ SG_ 922 KeyOutWarnReq "Key outside warning request   ";
CM_ SG_ 706 MirrFrntRiSts "Mirror front right    ";
CM_ SG_ 706 MirrCtrlSts "Mirror Control Status";
CM_ SG_ 706 FrntWiperBlkSts "Front wiper block position status ";
CM_ SG_ 706 FrntWiperParkSts "Front wiper park position status ";
CM_ SG_ 706 WiprServReqSts "Wiper service request status  ";
CM_ SG_ 706 MirrFrntLeSts "Mirror front left    ";
CM_ SG_ 706 WiprWshrLvl "Wiper washer level    ";
CM_ SG_ 706 FrntWiprSts "Front wiper status    ";
CM_ SG_ 706 MirrHeatSts "Mirror Heating Status ";
CM_ SG_ 704 ScurKeyInvd "Key certification Valid";
CM_ SG_ 704 FogLiFrntRiDrvrSts "Fog light front right driver status    ";
CM_ SG_ 704 FogLiFrntSts "Fog light front status    ";
CM_ SG_ 704 WelcomeLiReq "Welcome light request";
CM_ SG_ 704 HzrdWarnSts "Hazard warning status    ";
CM_ SG_ 704 DrowsinessIndexSts "Validity of Drowsiness index";
CM_ SG_ 704 DrowsinessIndex "Drowsiness HFC index";
CM_ SG_ 704 RiTurnIndcrLiSts "Right turn indicator light status    ";
CM_ SG_ 704 LeTurnIndcrLiSts "Left turn indicator light status    ";
CM_ SG_ 704 PuddleLiFrntLeSts "Puddle light front left status ";
CM_ SG_ 704 PuddleLiReLeSts "Puddle light rear left status ";
CM_ SG_ 704 ImmoAuthWarning "IMMO backup Indication";
CM_ SG_ 704 DrowsyWarning "DAS first level warning active from BCM ";
CM_ SG_ 704 HndlLiSts "handle light status ";
CM_ SG_ 704 LtgPwrSplyEnaSts "lighting power supply enable status ";
CM_ SG_ 704 LoBeamSts "Low beam status    ";
CM_ SG_ 704 IntrLiFootWellSts "Footwell light status ";
CM_ SG_ 704 DASFctSts "DAS function status from BCM to CDC";
CM_ SG_ 704 HiBeamSts "High beam status    ";
CM_ SG_ 704 PosnLiSts "Position light front status    ";
CM_ SG_ 704 FogLiFrntLeDrvrSts "Fog light front left driver status    ";
CM_ SG_ 704 DayTiRunngLiSts "Daytime running light  status    ";
CM_ SG_ 704 PuddleLiFrntRiSts "Puddle light front right status ";
CM_ SG_ 704 PuddleLiReRiSts "Puddle light rear right status ";
CM_ SG_ 701 TrAjarSts "Trunk ajar status    ";
CM_ SG_ 701 DoorAjarReRiSts "Door ajar rear right status    ";
CM_ SG_ 701 BCM_CLOSURE_CRC "BCM_CLOSURE CRC    ";
CM_ SG_ 701 CooltLvlLowWarnReq "Coolant level low warning request";
CM_ SG_ 701 DoorAjarReLeSts "Door ajar rear left status    ";
CM_ SG_ 701 DoorAjarFrntRiSts "Door ajar front right status    ";
CM_ SG_ 701 SeatOccpFrntLeFail "Seat occupant front left (driver) failure status";
CM_ SG_ 701 DoorAjarFrntLeSts "Door ajar front left status    ";
CM_ SG_ 701 SteerWhlHeatSts "Steering Wheel Heating Status ";
CM_ SG_ 701 SeatOccpFrntLeSts "Seat occupant front left (driver) status ";
CM_ SG_ 701 HoodAjarSts "Hood ajar status    ";
CM_ SG_ 701 BCM_CLOSURE_MsgCntr "BCM_CLOSURE message counter    ";
BA_DEF_ BO_  "GenMsgCycleTime" INT 0 0;
BA_DEF_ BO_  "GenMsgSendType" ENUM  "Cyclic","NotUsed","NotUsed","NotUsed","NotUsed","NotUsed","NotUsed","IfActive","NoMsgSendType","NotUsed";
BA_DEF_ SG_  "GenSigStartValue" INT 0 0;
BA_DEF_ SG_  "GenSigCycleTimeActive" INT 0 0;
BA_DEF_ SG_  "GenSigCycleTime" INT 0 0;
BA_DEF_ SG_  "GenSigSendType" ENUM  "Cyclic","OnWrite","OnWriteWithRepetition","OnChange","OnChangeWithRepetition","IfActive","IfActiveWithRepetition","NoSigSendType","NotUsed","NotUsed","NotUsed","NotUsed","NotUsed";
BA_DEF_  "Baudrate" INT 0 1000000;
BA_DEF_  "BusType" STRING ;
BA_DEF_  "NmType" STRING ;
BA_DEF_  "Manufacturer" STRING ;
BA_DEF_ BU_  "NodeLayerModules" STRING ;
BA_DEF_ BU_  "NmStationAddress" HEX 0 255;
BA_DEF_ BU_  "NmNode" ENUM  "no","yes";
BA_DEF_  "NmAsrWaitBusSleepTime" INT 0 65535;
BA_DEF_  "NmAsrTimeoutTime" INT 1 65535;
BA_DEF_  "NmAsrRepeatMessageTime" INT 0 65535;
BA_DEF_ BU_  "NmAsrNodeIdentifier" HEX 0 255;
BA_DEF_ BU_  "NmAsrNode" ENUM  "no","yes";
BA_DEF_  "NmAsrMessageCount" INT 1 256;
BA_DEF_ BU_  "NmAsrCanMsgReducedTime" INT 1 65535;
BA_DEF_  "NmAsrCanMsgCycleTime" INT 1 65535;
BA_DEF_ BU_  "NmAsrCanMsgCycleOffset" INT 0 65535;
BA_DEF_  "NmAsrBaseAddress" HEX 0 2047;
BA_DEF_ BU_  "ILUsed" ENUM  "no","yes";
BA_DEF_ SG_  "GenSigTimeoutValue" INT 0 65535;
BA_DEF_ BO_  "GenMsgILSupport" ENUM  "no","yes";
BA_DEF_ BO_  "DiagState" ENUM  "no","yes";
BA_DEF_ BO_  "DiagResponse" ENUM  "no","yes";
BA_DEF_ BO_  "DiagRequest" ENUM  "no","yes";
BA_DEF_  "DBName" STRING ;
BA_DEF_REL_ BU_SG_REL_  "GenSigTimeoutTime" INT 0 65535;
BA_DEF_DEF_  "GenMsgCycleTime" 0;
BA_DEF_DEF_  "GenMsgSendType" "Cyclic";
BA_DEF_DEF_  "GenSigStartValue" 0;
BA_DEF_DEF_  "GenSigCycleTimeActive" 0;
BA_DEF_DEF_  "GenSigCycleTime" 0;
BA_DEF_DEF_  "GenSigSendType" "Cyclic";
BA_DEF_DEF_  "Baudrate" 500000;
BA_DEF_DEF_  "BusType" "";
BA_DEF_DEF_  "NmType" "";
BA_DEF_DEF_  "Manufacturer" "Vector";
BA_DEF_DEF_  "NodeLayerModules" " ";
BA_DEF_DEF_  "NmStationAddress" 0;
BA_DEF_DEF_  "NmNode" "no";
BA_DEF_DEF_  "NmAsrWaitBusSleepTime" 1500;
BA_DEF_DEF_  "NmAsrTimeoutTime" 2000;
BA_DEF_DEF_  "NmAsrRepeatMessageTime" 3200;
BA_DEF_DEF_  "NmAsrNodeIdentifier" 50;
BA_DEF_DEF_  "NmAsrNode" "no";
BA_DEF_DEF_  "NmAsrMessageCount" 128;
BA_DEF_DEF_  "NmAsrCanMsgReducedTime" 320;
BA_DEF_DEF_  "NmAsrCanMsgCycleTime" 640;
BA_DEF_DEF_  "NmAsrCanMsgCycleOffset" 0;
BA_DEF_DEF_  "NmAsrBaseAddress" 1280;
BA_DEF_DEF_  "ILUsed" "no";
BA_DEF_DEF_  "GenSigTimeoutValue" 0;
BA_DEF_DEF_  "GenMsgILSupport" "no";
BA_DEF_DEF_  "DiagState" "no";
BA_DEF_DEF_  "DiagResponse" "no";
BA_DEF_DEF_  "DiagRequest" "no";
BA_DEF_DEF_  "DBName" "";
BA_DEF_DEF_REL_ "GenSigTimeoutTime" 0;
BA_ "NmType" "NmAsr";
BA_ "BusType" "CAN";
BA_ "NmAsrWaitBusSleepTime" 2000;
BA_ "DBName" "NIO_ES8_ADAS_CAN_SR_V7_5_2";
BA_ "ILUsed" BU_ RAD_RR 1;
BA_ "NmAsrNode" BU_ RAD_RR 1;
BA_ "NmAsrNodeIdentifier" BU_ RAD_RR 34;
BA_ "NmStationAddress" BU_ RAD_RR 34;
BA_ "ILUsed" BU_ RAD_RL 1;
BA_ "NmAsrNode" BU_ RAD_RL 1;
BA_ "NmAsrNodeIdentifier" BU_ RAD_RL 33;
BA_ "NmStationAddress" BU_ RAD_RL 33;
BA_ "ILUsed" BU_ RAD_FR 1;
BA_ "NmAsrNode" BU_ RAD_FR 1;
BA_ "NmAsrNodeIdentifier" BU_ RAD_FR 32;
BA_ "NmStationAddress" BU_ RAD_FR 32;
BA_ "ILUsed" BU_ RAD_FL 1;
BA_ "NmAsrNode" BU_ RAD_FL 1;
BA_ "NmAsrNodeIdentifier" BU_ RAD_FL 31;
BA_ "NmStationAddress" BU_ RAD_FL 31;
BA_ "ILUsed" BU_ RAD_FC 1;
BA_ "NmAsrNode" BU_ RAD_FC 1;
BA_ "NmAsrNodeIdentifier" BU_ RAD_FC 30;
BA_ "NmStationAddress" BU_ RAD_FC 30;
BA_ "ILUsed" BU_ CGW 1;
BA_ "NmAsrNode" BU_ CGW 1;
BA_ "NmAsrNodeIdentifier" BU_ CGW 5;
BA_ "NmStationAddress" BU_ CGW 5;
BA_ "ILUsed" BU_ APA 1;
BA_ "NmAsrNode" BU_ APA 1;
BA_ "NmAsrNodeIdentifier" BU_ APA 36;
BA_ "NmStationAddress" BU_ APA 36;
BA_ "ILUsed" BU_ ADC 1;
BA_ "NmAsrNode" BU_ ADC 1;
BA_ "NmAsrNodeIdentifier" BU_ ADC 35;
BA_ "NmStationAddress" BU_ ADC 35;
BA_ "GenMsgILSupport" BO_ 537 1;
BA_ "GenMsgCycleTime" BO_ 537 100;
BA_ "GenMsgILSupport" BO_ 850 1;
BA_ "GenMsgCycleTime" BO_ 850 1000;
BA_ "GenMsgILSupport" BO_ 535 1;
BA_ "GenMsgCycleTime" BO_ 535 20;
BA_ "GenMsgILSupport" BO_ 68 1;
BA_ "GenMsgCycleTime" BO_ 68 10;
BA_ "GenMsgILSupport" BO_ 663 1;
BA_ "GenMsgCycleTime" BO_ 663 100;
BA_ "GenMsgILSupport" BO_ 212 1;
BA_ "GenMsgCycleTime" BO_ 212 20;
BA_ "GenMsgILSupport" BO_ 168 1;
BA_ "GenMsgCycleTime" BO_ 168 20;
BA_ "GenMsgILSupport" BO_ 607 1;
BA_ "GenMsgCycleTime" BO_ 607 100;
BA_ "GenMsgILSupport" BO_ 603 1;
BA_ "GenMsgCycleTime" BO_ 603 100;
BA_ "GenMsgILSupport" BO_ 160 1;
BA_ "GenMsgCycleTime" BO_ 160 20;
BA_ "GenMsgILSupport" BO_ 599 1;
BA_ "GenMsgCycleTime" BO_ 599 100;
BA_ "GenMsgILSupport" BO_ 156 1;
BA_ "GenMsgCycleTime" BO_ 156 20;
BA_ "GenMsgILSupport" BO_ 567 1;
BA_ "GenMsgCycleTime" BO_ 567 100;
BA_ "GenMsgILSupport" BO_ 126 1;
BA_ "GenMsgCycleTime" BO_ 126 20;
BA_ "GenMsgILSupport" BO_ 117 1;
BA_ "GenMsgCycleTime" BO_ 117 20;
BA_ "GenMsgILSupport" BO_ 116 1;
BA_ "GenMsgCycleTime" BO_ 116 20;
BA_ "DiagResponse" BO_ 1698 1;
BA_ "GenMsgSendType" BO_ 1698 8;
BA_ "DiagResponse" BO_ 1697 1;
BA_ "GenMsgSendType" BO_ 1697 8;
BA_ "DiagResponse" BO_ 1696 1;
BA_ "GenMsgSendType" BO_ 1696 8;
BA_ "DiagResponse" BO_ 1695 1;
BA_ "GenMsgSendType" BO_ 1695 8;
BA_ "DiagResponse" BO_ 1694 1;
BA_ "GenMsgSendType" BO_ 1694 8;
BA_ "DiagResponse" BO_ 1700 1;
BA_ "GenMsgSendType" BO_ 1700 8;
BA_ "DiagRequest" BO_ 1570 1;
BA_ "GenMsgSendType" BO_ 1570 8;
BA_ "DiagRequest" BO_ 1569 1;
BA_ "GenMsgSendType" BO_ 1569 8;
BA_ "DiagRequest" BO_ 1568 1;
BA_ "GenMsgSendType" BO_ 1568 8;
BA_ "DiagRequest" BO_ 1567 1;
BA_ "GenMsgSendType" BO_ 1567 8;
BA_ "DiagRequest" BO_ 1566 1;
BA_ "GenMsgSendType" BO_ 1566 8;
BA_ "DiagState" BO_ 1537 1;
BA_ "GenMsgSendType" BO_ 1537 8;
BA_ "DiagRequest" BO_ 1572 1;
BA_ "GenMsgSendType" BO_ 1572 8;
BA_ "GenMsgILSupport" BO_ 946 1;
BA_ "GenMsgCycleTime" BO_ 946 1000;
BA_ "GenMsgILSupport" BO_ 700 1;
BA_ "GenMsgCycleTime" BO_ 700 100;
BA_ "GenMsgILSupport" BO_ 705 1;
BA_ "GenMsgCycleTime" BO_ 705 100;
BA_ "GenMsgILSupport" BO_ 957 1;
BA_ "GenMsgCycleTime" BO_ 957 1000;
BA_ "GenMsgILSupport" BO_ 707 1;
BA_ "GenMsgCycleTime" BO_ 707 20;
BA_ "GenMsgILSupport" BO_ 737 1;
BA_ "GenMsgCycleTime" BO_ 737 100;
BA_ "GenMsgILSupport" BO_ 938 1;
BA_ "GenMsgCycleTime" BO_ 938 1000;
BA_ "GenMsgILSupport" BO_ 686 1;
BA_ "GenMsgCycleTime" BO_ 686 100;
BA_ "GenMsgILSupport" BO_ 685 1;
BA_ "GenMsgCycleTime" BO_ 685 100;
BA_ "GenMsgILSupport" BO_ 684 1;
BA_ "GenMsgCycleTime" BO_ 684 100;
BA_ "GenMsgILSupport" BO_ 680 1;
BA_ "GenMsgCycleTime" BO_ 680 100;
BA_ "GenMsgILSupport" BO_ 788 1;
BA_ "GenMsgCycleTime" BO_ 788 100;
BA_ "GenMsgILSupport" BO_ 552 1;
BA_ "GenMsgCycleTime" BO_ 552 100;
BA_ "GenMsgILSupport" BO_ 94 1;
BA_ "GenMsgCycleTime" BO_ 94 20;
BA_ "GenMsgILSupport" BO_ 91 1;
BA_ "GenMsgCycleTime" BO_ 91 20;
BA_ "GenMsgILSupport" BO_ 90 1;
BA_ "GenMsgCycleTime" BO_ 90 20;
BA_ "GenMsgILSupport" BO_ 89 1;
BA_ "GenMsgCycleTime" BO_ 89 20;
BA_ "GenMsgILSupport" BO_ 88 1;
BA_ "GenMsgCycleTime" BO_ 88 20;
BA_ "GenMsgILSupport" BO_ 720 1;
BA_ "GenMsgCycleTime" BO_ 720 100;
BA_ "GenMsgILSupport" BO_ 709 1;
BA_ "GenMsgCycleTime" BO_ 709 200;
BA_ "GenMsgILSupport" BO_ 922 1;
BA_ "GenMsgCycleTime" BO_ 922 1000;
BA_ "GenMsgILSupport" BO_ 706 1;
BA_ "GenMsgCycleTime" BO_ 706 50;
BA_ "GenMsgILSupport" BO_ 704 1;
BA_ "GenMsgCycleTime" BO_ 704 100;
BA_ "GenMsgILSupport" BO_ 701 1;
BA_ "GenMsgCycleTime" BO_ 701 20;
BA_ "GenSigStartValue" SG_ 537 VCUPwrDisp 300;
BA_ "GenSigStartValue" SG_ 850 LVBattUSts 1;
BA_ "GenSigCycleTime" SG_ 535 VCUTqAvl 100;
BA_ "GenSigCycleTimeActive" SG_ 535 VCUTqAvl 100;
BA_ "GenSigStartValue" SG_ 168 LCAHapticOnOffSts 1;
BA_ "GenSigStartValue" SG_ 126 PCWLatentWarnOnOffSts 1;
BA_ "GenSigStartValue" SG_ 126 FCWSetSts 1;
BA_ "GenSigStartValue" SG_ 126 PCWPreWarnOnOffSts 1;
BA_ "GenSigStartValue" SG_ 117 EPS_DrvOverRideDetn 2;
BA_ "GenSigStartValue" SG_ 117 EPS_MotorTq 512;
BA_ "GenSigStartValue" SG_ 117 EPS_EstRackForceValid 2;
BA_ "GenSigStartValue" SG_ 117 EPS_EstRackForce 512;
BA_ "GenSigStartValue" SG_ 117 EPS_PinionAg 16384;
BA_ "GenSigStartValue" SG_ 117 EPS_PinionAgValid 2;
BA_ "GenSigStartValue" SG_ 117 EPS_MotorTqValid 2;
BA_ "GenSigStartValue" SG_ 117 EPS_HandsOffDetnConfidence 15;
BA_ "GenSigStartValue" SG_ 116 EPS_ActvExtIf 15;
BA_ "GenSigStartValue" SG_ 116 EPS_DrvngMod 7;
BA_ "GenSigStartValue" SG_ 116 EPS_WarnLampReq 2;
BA_ "GenSigStartValue" SG_ 116 EPS_TorsBarTq 512;
BA_ "GenSigStartValue" SG_ 116 EPS_TorsBarTqValid 2;
BA_ "GenSigSendType" SG_ 1698 DiagRespData3_RAD_RR 7;
BA_ "GenSigSendType" SG_ 1698 DiagRespData0_RAD_RR 7;
BA_ "GenSigSendType" SG_ 1698 DiagRespData5_RAD_RR 7;
BA_ "GenSigSendType" SG_ 1698 DiagRespData6_RAD_RR 7;
BA_ "GenSigSendType" SG_ 1698 DiagRespData2_RAD_RR 7;
BA_ "GenSigSendType" SG_ 1698 DiagRespData7_RAD_RR 7;
BA_ "GenSigSendType" SG_ 1698 DiagRespData4_RAD_RR 7;
BA_ "GenSigSendType" SG_ 1698 DiagRespData1_RAD_RR 7;
BA_ "GenSigSendType" SG_ 1697 DiagRespData0_RAD_RL 7;
BA_ "GenSigSendType" SG_ 1697 DiagRespData2_RAD_RL 7;
BA_ "GenSigSendType" SG_ 1697 DiagRespData7_RAD_RL 7;
BA_ "GenSigSendType" SG_ 1697 DiagRespData4_RAD_RL 7;
BA_ "GenSigSendType" SG_ 1697 DiagRespData1_RAD_RL 7;
BA_ "GenSigSendType" SG_ 1697 DiagRespData3_RAD_RL 7;
BA_ "GenSigSendType" SG_ 1697 DiagRespData6_RAD_RL 7;
BA_ "GenSigSendType" SG_ 1697 DiagRespData5_RAD_RL 7;
BA_ "GenSigSendType" SG_ 1696 DiagRespData7_RAD_FR 7;
BA_ "GenSigSendType" SG_ 1696 DiagRespData1_RAD_FR 7;
BA_ "GenSigSendType" SG_ 1696 DiagRespData6_RAD_FR 7;
BA_ "GenSigSendType" SG_ 1696 DiagRespData0_RAD_FR 7;
BA_ "GenSigSendType" SG_ 1696 DiagRespData4_RAD_FR 7;
BA_ "GenSigSendType" SG_ 1696 DiagRespData2_RAD_FR 7;
BA_ "GenSigSendType" SG_ 1696 DiagRespData3_RAD_FR 7;
BA_ "GenSigSendType" SG_ 1696 DiagRespData5_RAD_FR 7;
BA_ "GenSigSendType" SG_ 1695 DiagRespData0_RAD_FL 7;
BA_ "GenSigSendType" SG_ 1695 DiagRespData6_RAD_FL 7;
BA_ "GenSigSendType" SG_ 1695 DiagRespData3_RAD_FL 7;
BA_ "GenSigSendType" SG_ 1695 DiagRespData4_RAD_FL 7;
BA_ "GenSigSendType" SG_ 1695 DiagRespData1_RAD_FL 7;
BA_ "GenSigSendType" SG_ 1695 DiagRespData5_RAD_FL 7;
BA_ "GenSigSendType" SG_ 1695 DiagRespData2_RAD_FL 7;
BA_ "GenSigSendType" SG_ 1695 DiagRespData7_RAD_FL 7;
BA_ "GenSigSendType" SG_ 1694 DiagRespData2_RAD_FC 7;
BA_ "GenSigSendType" SG_ 1694 DiagRespData5_RAD_FC 7;
BA_ "GenSigSendType" SG_ 1694 DiagRespData6_RAD_FC 7;
BA_ "GenSigSendType" SG_ 1694 DiagRespData0_RAD_FC 7;
BA_ "GenSigSendType" SG_ 1694 DiagRespData3_RAD_FC 7;
BA_ "GenSigSendType" SG_ 1694 DiagRespData1_RAD_FC 7;
BA_ "GenSigSendType" SG_ 1694 DiagRespData4_RAD_FC 7;
BA_ "GenSigSendType" SG_ 1694 DiagRespData7_RAD_FC 7;
BA_ "GenSigSendType" SG_ 1700 DiagRespData4_APA 7;
BA_ "GenSigSendType" SG_ 1700 DiagRespData2_APA 7;
BA_ "GenSigSendType" SG_ 1700 DiagRespData0_APA 7;
BA_ "GenSigSendType" SG_ 1700 DiagRespData7_APA 7;
BA_ "GenSigSendType" SG_ 1700 DiagRespData3_APA 7;
BA_ "GenSigSendType" SG_ 1700 DiagRespData1_APA 7;
BA_ "GenSigSendType" SG_ 1700 DiagRespData6_APA 7;
BA_ "GenSigSendType" SG_ 1700 DiagRespData5_APA 7;
BA_ "GenSigSendType" SG_ 1570 DiagReqData4_RAD_RR 7;
BA_ "GenSigSendType" SG_ 1570 DiagReqData7_RAD_RR 7;
BA_ "GenSigSendType" SG_ 1570 DiagReqData5_RAD_RR 7;
BA_ "GenSigSendType" SG_ 1570 DiagReqData1_RAD_RR 7;
BA_ "GenSigSendType" SG_ 1570 DiagReqData3_RAD_RR 7;
BA_ "GenSigSendType" SG_ 1570 DiagReqData2_RAD_RR 7;
BA_ "GenSigSendType" SG_ 1570 DiagReqData0_RAD_RR 7;
BA_ "GenSigSendType" SG_ 1570 DiagReqData6_RAD_RR 7;
BA_ "GenSigSendType" SG_ 1569 DiagReqData2_RAD_RL 7;
BA_ "GenSigSendType" SG_ 1569 DiagReqData3_RAD_RL 7;
BA_ "GenSigSendType" SG_ 1569 DiagReqData0_RAD_RL 7;
BA_ "GenSigSendType" SG_ 1569 DiagReqData7_RAD_RL 7;
BA_ "GenSigSendType" SG_ 1569 DiagReqData1_RAD_RL 7;
BA_ "GenSigSendType" SG_ 1569 DiagReqData4_RAD_RL 7;
BA_ "GenSigSendType" SG_ 1569 DiagReqData5_RAD_RL 7;
BA_ "GenSigSendType" SG_ 1569 DiagReqData6_RAD_RL 7;
BA_ "GenSigSendType" SG_ 1568 DiagReqData3_RAD_FR 7;
BA_ "GenSigSendType" SG_ 1568 DiagReqData6_RAD_FR 7;
BA_ "GenSigSendType" SG_ 1568 DiagReqData5_RAD_FR 7;
BA_ "GenSigSendType" SG_ 1568 DiagReqData0_RAD_FR 7;
BA_ "GenSigSendType" SG_ 1568 DiagReqData7_RAD_FR 7;
BA_ "GenSigSendType" SG_ 1568 DiagReqData4_RAD_FR 7;
BA_ "GenSigSendType" SG_ 1568 DiagReqData2_RAD_FR 7;
BA_ "GenSigSendType" SG_ 1568 DiagReqData1_RAD_FR 7;
BA_ "GenSigSendType" SG_ 1567 DiagReqData1_RAD_FL 7;
BA_ "GenSigSendType" SG_ 1567 DiagReqData7_RAD_FL 7;
BA_ "GenSigSendType" SG_ 1567 DiagReqData6_RAD_FL 7;
BA_ "GenSigSendType" SG_ 1567 DiagReqData0_RAD_FL 7;
BA_ "GenSigSendType" SG_ 1567 DiagReqData4_RAD_FL 7;
BA_ "GenSigSendType" SG_ 1567 DiagReqData3_RAD_FL 7;
BA_ "GenSigSendType" SG_ 1567 DiagReqData2_RAD_FL 7;
BA_ "GenSigSendType" SG_ 1567 DiagReqData5_RAD_FL 7;
BA_ "GenSigSendType" SG_ 1566 DiagReqData6_RAD_FC 7;
BA_ "GenSigSendType" SG_ 1566 DiagReqData3_RAD_FC 7;
BA_ "GenSigSendType" SG_ 1566 DiagReqData4_RAD_FC 7;
BA_ "GenSigSendType" SG_ 1566 DiagReqData5_RAD_FC 7;
BA_ "GenSigSendType" SG_ 1566 DiagReqData0_RAD_FC 7;
BA_ "GenSigSendType" SG_ 1566 DiagReqData7_RAD_FC 7;
BA_ "GenSigSendType" SG_ 1566 DiagReqData1_RAD_FC 7;
BA_ "GenSigSendType" SG_ 1566 DiagReqData2_RAD_FC 7;
BA_ "GenSigSendType" SG_ 1537 DiagReqData6_AllECU 7;
BA_ "GenSigSendType" SG_ 1537 DiagReqData1_AllECU 7;
BA_ "GenSigSendType" SG_ 1537 DiagReqData0_AllECU 7;
BA_ "GenSigSendType" SG_ 1537 DiagReqData7_AllECU 7;
BA_ "GenSigSendType" SG_ 1537 DiagReqData4_AllECU 7;
BA_ "GenSigSendType" SG_ 1537 DiagReqData2_AllECU 7;
BA_ "GenSigSendType" SG_ 1537 DiagReqData3_AllECU 7;
BA_ "GenSigSendType" SG_ 1537 DiagReqData5_AllECU 7;
BA_ "GenSigSendType" SG_ 1572 DiagReqData5_APA 7;
BA_ "GenSigSendType" SG_ 1572 DiagReqData3_APA 7;
BA_ "GenSigSendType" SG_ 1572 DiagReqData4_APA 7;
BA_ "GenSigSendType" SG_ 1572 DiagReqData1_APA 7;
BA_ "GenSigSendType" SG_ 1572 DiagReqData2_APA 7;
BA_ "GenSigSendType" SG_ 1572 DiagReqData0_APA 7;
BA_ "GenSigSendType" SG_ 1572 DiagReqData6_APA 7;
BA_ "GenSigSendType" SG_ 1572 DiagReqData7_APA 7;
BA_ "GenSigCycleTime" SG_ 685 SetLKASteerSupportLvl 100;
BA_ "GenSigCycleTimeActive" SG_ 685 SetLKASteerSupportLvl 100;
BA_ "GenSigStartValue" SG_ 685 SetLKASteerSupportLvl 1;
BA_ "GenSigCycleTime" SG_ 685 SetPilotLatContAutoEngage 100;
BA_ "GenSigCycleTimeActive" SG_ 685 SetPilotLatContAutoEngage 100;
BA_ "GenSigStartValue" SG_ 685 SetPilotLatContAutoEngage 1;
BA_ "GenSigCycleTime" SG_ 685 SetALC 100;
BA_ "GenSigCycleTimeActive" SG_ 685 SetALC 100;
BA_ "GenSigCycleTime" SG_ 685 SetPilotSteerSupportLvl 100;
BA_ "GenSigCycleTimeActive" SG_ 685 SetPilotSteerSupportLvl 100;
BA_ "GenSigStartValue" SG_ 685 SetPilotSteerSupportLvl 1;
BA_ "GenSigStartValue" SG_ 684 FolwMeHomeOnOff 3;
BA_ "GenSigStartValue" SG_ 684 FolwMeHomeTiSet 7;
BA_ "GenSigStartValue" SG_ 684 WelcomeLiOnOff 3;
BA_ "GenSigStartValue" SG_ 684 AVAOnOffReq 1;
BA_ "GenSigStartValue" SG_ 684 CbnLiSet 3;
BA_ "GenSigStartValue" SG_ 680 LCAOnOff 1;
BA_ "GenSigStartValue" SG_ 680 FCWSet 1;
BA_ "GenSigStartValue" SG_ 680 SetLaneAssiAidTyp 1;
BA_ "GenSigStartValue" SG_ 680 PCW_PreWarningOnOff 1;
BA_ "GenSigStartValue" SG_ 680 PCW_LatentWarningOnOff 1;
BA_ "GenSigStartValue" SG_ 680 AEBOnOff 1;
BA_ "GenSigStartValue" SG_ 680 LaneAssistTactileOnOff 1;
BA_ "GenSigStartValue" SG_ 680 SdowOnOffReq 1;
BA_ "GenSigStartValue" SG_ 680 LCATactileWarningOnOff 1;
BA_ "GenSigStartValue" SG_ 680 FCTAOnOffCmd 1;
BA_ "GenSigStartValue" SG_ 680 GoNotifierOnOff 1;
BA_ "GenSigStartValue" SG_ 680 SetLaneAssiSnvty 1;
BA_ "GenSigStartValue" SG_ 680 RCTAReq 1;
BA_ "GenSigCycleTime" SG_ 552 HodWarnSeq 100;
BA_ "GenSigCycleTimeActive" SG_ 552 HodWarnSeq 100;
BA_ "GenSigStartValue" SG_ 552 LDWLKALaneAssiTyp 1;
BA_ "GenSigCycleTime" SG_ 552 ALCSts 100;
BA_ "GenSigCycleTimeActive" SG_ 552 ALCSts 100;
BA_ "GenSigCycleTime" SG_ 552 CAM_FC_03_CRC 100;
BA_ "GenSigCycleTimeActive" SG_ 552 CAM_FC_03_CRC 100;
BA_ "GenSigCycleTime" SG_ 552 PilotTarObjTrackingSts 100;
BA_ "GenSigCycleTimeActive" SG_ 552 PilotTarObjTrackingSts 100;
BA_ "GenSigCycleTime" SG_ 552 PilotLatContAutoEngage 100;
BA_ "GenSigCycleTimeActive" SG_ 552 PilotLatContAutoEngage 100;
BA_ "GenSigStartValue" SG_ 552 PilotLatContAutoEngage 1;
BA_ "GenSigCycleTime" SG_ 552 HzrdLiReq 100;
BA_ "GenSigCycleTimeActive" SG_ 552 HzrdLiReq 100;
BA_ "GenSigCycleTime" SG_ 552 PilotSteerSupportLvl 100;
BA_ "GenSigCycleTimeActive" SG_ 552 PilotSteerSupportLvl 100;
BA_ "GenSigStartValue" SG_ 552 PilotSteerSupportLvl 1;
BA_ "GenSigCycleTime" SG_ 552 LKASteerSupportLvl 100;
BA_ "GenSigCycleTimeActive" SG_ 552 LKASteerSupportLvl 100;
BA_ "GenSigStartValue" SG_ 552 LKASteerSupportLvl 1;
BA_ "GenSigCycleTime" SG_ 552 LaneAssiSnvty 100;
BA_ "GenSigCycleTimeActive" SG_ 552 LaneAssiSnvty 100;
BA_ "GenSigStartValue" SG_ 552 LKSSnsvty 1;
BA_ "GenSigCycleTime" SG_ 552 FCTAOnOffSts 100;
BA_ "GenSigCycleTimeActive" SG_ 552 FCTAOnOffSts 100;
BA_ "GenSigCycleTime" SG_ 552 DoorUnlckReq 100;
BA_ "GenSigCycleTimeActive" SG_ 552 DoorUnlckReq 100;
BA_ "GenSigCycleTime" SG_ 552 ALC 100;
BA_ "GenSigCycleTimeActive" SG_ 552 ALC 100;
BA_ "GenSigCycleTime" SG_ 552 CAM_FC_03_MsgCntr 100;
BA_ "GenSigCycleTimeActive" SG_ 552 CAM_FC_03_MsgCntr 100;
BA_ "GenSigStartValue" SG_ 91 BrkPressOffset 15;
BA_ "GenSigStartValue" SG_ 89 WhlSpdReRiSts 2;
BA_ "GenSigStartValue" SG_ 89 WhlSpdReLeSts 2;
BA_ "GenSigStartValue" SG_ 88 WhlSpdFrntRiSts 2;
BA_ "GenSigStartValue" SG_ 88 WhlSpdFrntLeSts 2;
BA_REL_ "GenSigTimeoutTime" BU_SG_REL_ RAD_FC SG_ 537 VCUVehRdy 500;
BA_REL_ "GenSigTimeoutTime" BU_SG_REL_ RAD_RL SG_ 850 LVBattU 5000;
BA_REL_ "GenSigTimeoutTime" BU_SG_REL_ RAD_FR SG_ 850 LVBattU 5000;
BA_REL_ "GenSigTimeoutTime" BU_SG_REL_ ADC SG_ 850 LVBattU 5000;
BA_REL_ "GenSigTimeoutTime" BU_SG_REL_ RAD_RR SG_ 850 LVBattU 5000;
BA_REL_ "GenSigTimeoutTime" BU_SG_REL_ RAD_FC SG_ 850 LVBattU 5000;
BA_REL_ "GenSigTimeoutTime" BU_SG_REL_ RAD_FL SG_ 850 LVBattU 5000;
BA_REL_ "GenSigTimeoutTime" BU_SG_REL_ ADC SG_ 850 LVBattUSts 5000;
BA_REL_ "GenSigTimeoutTime" BU_SG_REL_ RAD_FC SG_ 850 LVBattUSts 5000;
BA_REL_ "GenSigTimeoutTime" BU_SG_REL_ RAD_RL SG_ 850 LVBattUSts 5000;
BA_REL_ "GenSigTimeoutTime" BU_SG_REL_ APA SG_ 850 LVBattUSts 5000;
BA_REL_ "GenSigTimeoutTime" BU_SG_REL_ RAD_FR SG_ 850 LVBattUSts 5000;
BA_REL_ "GenSigTimeoutTime" BU_SG_REL_ RAD_FL SG_ 850 LVBattUSts 5000;
BA_REL_ "GenSigTimeoutTime" BU_SG_REL_ RAD_RR SG_ 850 LVBattUSts 5000;
BA_REL_ "GenSigTimeoutTime" BU_SG_REL_ RAD_FL SG_ 535 VCUActGearValid 150;
BA_REL_ "GenSigTimeoutTime" BU_SG_REL_ RAD_RR SG_ 535 VCUActGearValid 150;
BA_REL_ "GenSigTimeoutTime" BU_SG_REL_ APA SG_ 535 VCUActGearValid 150;
BA_REL_ "GenSigTimeoutTime" BU_SG_REL_ RAD_RL SG_ 535 VCUActGearValid 150;
BA_REL_ "GenSigTimeoutTime" BU_SG_REL_ RAD_FC SG_ 535 VCUActGearValid 150;
BA_REL_ "GenSigTimeoutTime" BU_SG_REL_ RAD_FR SG_ 535 VCUActGearValid 150;
BA_REL_ "GenSigTimeoutTime" BU_SG_REL_ RAD_FR SG_ 535 VCU_05_CRC 150;
BA_REL_ "GenSigTimeoutTime" BU_SG_REL_ RAD_FC SG_ 535 VCU_05_CRC 150;
BA_REL_ "GenSigTimeoutTime" BU_SG_REL_ RAD_FL SG_ 535 VCU_05_CRC 150;
BA_REL_ "GenSigTimeoutTime" BU_SG_REL_ RAD_RL SG_ 535 VCU_05_CRC 150;
BA_REL_ "GenSigTimeoutTime" BU_SG_REL_ APA SG_ 535 VCU_05_CRC 150;
BA_REL_ "GenSigTimeoutTime" BU_SG_REL_ RAD_RR SG_ 535 VCU_05_CRC 150;
BA_REL_ "GenSigTimeoutTime" BU_SG_REL_ RAD_RR SG_ 535 VCUActGear 150;
BA_REL_ "GenSigTimeoutTime" BU_SG_REL_ APA SG_ 535 VCUActGear 150;
BA_REL_ "GenSigTimeoutTime" BU_SG_REL_ RAD_FL SG_ 535 VCUActGear 150;
BA_REL_ "GenSigTimeoutTime" BU_SG_REL_ RAD_RL SG_ 535 VCUActGear 150;
BA_REL_ "GenSigTimeoutTime" BU_SG_REL_ RAD_FC SG_ 535 VCUActGear 150;
BA_REL_ "GenSigTimeoutTime" BU_SG_REL_ RAD_FR SG_ 535 VCUActGear 150;
BA_REL_ "GenSigTimeoutTime" BU_SG_REL_ ADC SG_ 535 VCUTqAvl 150;
BA_REL_ "GenSigTimeoutTime" BU_SG_REL_ RAD_RL SG_ 535 VCU_05_MsgCntr 150;
BA_REL_ "GenSigTimeoutTime" BU_SG_REL_ APA SG_ 535 VCU_05_MsgCntr 150;
BA_REL_ "GenSigTimeoutTime" BU_SG_REL_ RAD_RR SG_ 535 VCU_05_MsgCntr 150;
BA_REL_ "GenSigTimeoutTime" BU_SG_REL_ RAD_FC SG_ 535 VCU_05_MsgCntr 150;
BA_REL_ "GenSigTimeoutTime" BU_SG_REL_ RAD_FR SG_ 535 VCU_05_MsgCntr 150;
BA_REL_ "GenSigTimeoutTime" BU_SG_REL_ RAD_FL SG_ 535 VCU_05_MsgCntr 150;
BA_REL_ "GenSigTimeoutTime" BU_SG_REL_ ADC SG_ 68 VCUTotlMotPosTqCp 150;
BA_REL_ "GenSigTimeoutTime" BU_SG_REL_ ADC SG_ 68 VCUTQCSts 150;
BA_REL_ "GenSigTimeoutTime" BU_SG_REL_ ADC SG_ 68 VCUTotlMotNegTqCp 150;
BA_REL_ "GenSigTimeoutTime" BU_SG_REL_ RAD_RR SG_ 663 TurnIndcrSwtSts 150;
BA_REL_ "GenSigTimeoutTime" BU_SG_REL_ RAD_RL SG_ 663 TurnIndcrSwtSts 150;
BA_REL_ "GenSigTimeoutTime" BU_SG_REL_ RAD_FR SG_ 663 TurnIndcrSwtSts 150;
BA_REL_ "GenSigTimeoutTime" BU_SG_REL_ RAD_FL SG_ 663 TurnIndcrSwtSts 150;
BA_REL_ "GenSigTimeoutTime" BU_SG_REL_ RAD_RR SG_ 212 SteerWhlAgSpd 150;
BA_REL_ "GenSigTimeoutTime" BU_SG_REL_ RAD_FL SG_ 212 SteerWhlAgSpd 150;
BA_REL_ "GenSigTimeoutTime" BU_SG_REL_ RAD_FR SG_ 212 SteerWhlAgSpd 150;
BA_REL_ "GenSigTimeoutTime" BU_SG_REL_ RAD_FC SG_ 212 SteerWhlAgSpd 150;
BA_REL_ "GenSigTimeoutTime" BU_SG_REL_ RAD_RL SG_ 212 SteerWhlAgSpd 150;
BA_REL_ "GenSigTimeoutTime" BU_SG_REL_ RAD_FR SG_ 212 SteerAgSnsrFailSts 150;
BA_REL_ "GenSigTimeoutTime" BU_SG_REL_ RAD_FL SG_ 212 SteerAgSnsrFailSts 150;
BA_REL_ "GenSigTimeoutTime" BU_SG_REL_ RAD_RR SG_ 212 SteerAgSnsrFailSts 150;
BA_REL_ "GenSigTimeoutTime" BU_SG_REL_ RAD_RL SG_ 212 SteerAgSnsrFailSts 150;
BA_REL_ "GenSigTimeoutTime" BU_SG_REL_ RAD_FC SG_ 212 SteerAgSnsrFailSts 150;
BA_REL_ "GenSigTimeoutTime" BU_SG_REL_ RAD_RL SG_ 212 SCM_01_CRC 150;
BA_REL_ "GenSigTimeoutTime" BU_SG_REL_ RAD_RR SG_ 212 SCM_01_CRC 150;
BA_REL_ "GenSigTimeoutTime" BU_SG_REL_ RAD_FL SG_ 212 SCM_01_CRC 150;
BA_REL_ "GenSigTimeoutTime" BU_SG_REL_ RAD_FR SG_ 212 SCM_01_CRC 150;
BA_REL_ "GenSigTimeoutTime" BU_SG_REL_ RAD_FC SG_ 212 SCM_01_CRC 150;
BA_REL_ "GenSigTimeoutTime" BU_SG_REL_ RAD_FR SG_ 212 SteerWhlAgDir 150;
BA_REL_ "GenSigTimeoutTime" BU_SG_REL_ RAD_FC SG_ 212 SteerWhlAgDir 150;
BA_REL_ "GenSigTimeoutTime" BU_SG_REL_ RAD_RR SG_ 212 SteerWhlAgDir 150;
BA_REL_ "GenSigTimeoutTime" BU_SG_REL_ RAD_FL SG_ 212 SteerWhlAgDir 150;
BA_REL_ "GenSigTimeoutTime" BU_SG_REL_ RAD_RL SG_ 212 SteerWhlAgDir 150;
BA_REL_ "GenSigTimeoutTime" BU_SG_REL_ RAD_RL SG_ 212 SCM_01_MsgCntr 150;
BA_REL_ "GenSigTimeoutTime" BU_SG_REL_ RAD_FR SG_ 212 SCM_01_MsgCntr 150;
BA_REL_ "GenSigTimeoutTime" BU_SG_REL_ RAD_FC SG_ 212 SCM_01_MsgCntr 150;
BA_REL_ "GenSigTimeoutTime" BU_SG_REL_ RAD_RR SG_ 212 SCM_01_MsgCntr 150;
BA_REL_ "GenSigTimeoutTime" BU_SG_REL_ RAD_FL SG_ 212 SCM_01_MsgCntr 150;
BA_REL_ "GenSigTimeoutTime" BU_SG_REL_ RAD_RR SG_ 212 SteerWhlAgSpdDir 150;
BA_REL_ "GenSigTimeoutTime" BU_SG_REL_ RAD_FL SG_ 212 SteerWhlAgSpdDir 150;
BA_REL_ "GenSigTimeoutTime" BU_SG_REL_ RAD_RL SG_ 212 SteerWhlAgSpdDir 150;
BA_REL_ "GenSigTimeoutTime" BU_SG_REL_ RAD_FC SG_ 212 SteerWhlAgSpdDir 150;
BA_REL_ "GenSigTimeoutTime" BU_SG_REL_ RAD_FR SG_ 212 SteerWhlAgSpdDir 150;
BA_REL_ "GenSigTimeoutTime" BU_SG_REL_ RAD_FC SG_ 212 SteerWhlAgAndSpdValid 150;
BA_REL_ "GenSigTimeoutTime" BU_SG_REL_ RAD_RR SG_ 212 SteerWhlAgAndSpdValid 150;
BA_REL_ "GenSigTimeoutTime" BU_SG_REL_ RAD_FL SG_ 212 SteerWhlAgAndSpdValid 150;
BA_REL_ "GenSigTimeoutTime" BU_SG_REL_ RAD_FR SG_ 212 SteerWhlAgAndSpdValid 150;
BA_REL_ "GenSigTimeoutTime" BU_SG_REL_ RAD_RL SG_ 212 SteerWhlAgAndSpdValid 150;
BA_REL_ "GenSigTimeoutTime" BU_SG_REL_ RAD_RL SG_ 212 SteerAgSnsrCalSts 150;
BA_REL_ "GenSigTimeoutTime" BU_SG_REL_ RAD_FR SG_ 212 SteerAgSnsrCalSts 150;
BA_REL_ "GenSigTimeoutTime" BU_SG_REL_ RAD_FL SG_ 212 SteerAgSnsrCalSts 150;
BA_REL_ "GenSigTimeoutTime" BU_SG_REL_ RAD_FC SG_ 212 SteerAgSnsrCalSts 150;
BA_REL_ "GenSigTimeoutTime" BU_SG_REL_ RAD_RR SG_ 212 SteerAgSnsrCalSts 150;
BA_REL_ "GenSigTimeoutTime" BU_SG_REL_ RAD_FL SG_ 212 SteerWhlAg 150;
BA_REL_ "GenSigTimeoutTime" BU_SG_REL_ RAD_RL SG_ 212 SteerWhlAg 150;
BA_REL_ "GenSigTimeoutTime" BU_SG_REL_ RAD_FR SG_ 212 SteerWhlAg 150;
BA_REL_ "GenSigTimeoutTime" BU_SG_REL_ RAD_FC SG_ 212 SteerWhlAg 150;
BA_REL_ "GenSigTimeoutTime" BU_SG_REL_ RAD_RR SG_ 212 SteerWhlAg 150;
BA_REL_ "GenSigTimeoutTime" BU_SG_REL_ CGW SG_ 168 BSDLCAReLeWarnReq 150;
BA_REL_ "GenSigTimeoutTime" BU_SG_REL_ CGW SG_ 168 RAD_RR_01_MsgCntr 150;
BA_REL_ "GenSigTimeoutTime" BU_SG_REL_ CGW SG_ 168 ExtReqRAD_RR 150;
BA_REL_ "GenSigTimeoutTime" BU_SG_REL_ CGW SG_ 168 BSDLCAReRiWarnReq 150;
BA_REL_ "GenSigTimeoutTime" BU_SG_REL_ CGW SG_ 168 SdowLeWarnReq 150;
BA_REL_ "GenSigTimeoutTime" BU_SG_REL_ CGW SG_ 168 SDOWOnOffSts 150;
BA_REL_ "GenSigTimeoutTime" BU_SG_REL_ CGW SG_ 168 LCAHapticOnOffSts 150;
BA_REL_ "GenSigTimeoutTime" BU_SG_REL_ CGW SG_ 168 BSDLCAOnOffSts 150;
BA_REL_ "GenSigTimeoutTime" BU_SG_REL_ CGW SG_ 168 SdowRiWarnReq 150;
BA_REL_ "GenSigTimeoutTime" BU_SG_REL_ CGW SG_ 168 CTAReLeWarnReq 150;
BA_REL_ "GenSigTimeoutTime" BU_SG_REL_ CGW SG_ 168 ReRiRSDSDisp 150;
BA_REL_ "GenSigTimeoutTime" BU_SG_REL_ CGW SG_ 168 RCTAOnOffSts 150;
BA_REL_ "GenSigTimeoutTime" BU_SG_REL_ CGW SG_ 168 CTAReRiWarnReq 150;
BA_REL_ "GenSigTimeoutTime" BU_SG_REL_ CGW SG_ 168 RAD_RR_01_CRC 150;
BA_REL_ "GenSigTimeoutTime" BU_SG_REL_ RAD_RR SG_ 607 Dummy_RAD_RL 500;
BA_REL_ "GenSigTimeoutTime" BU_SG_REL_ CGW SG_ 607 Dummy_RAD_RL 500;
BA_REL_ "GenSigTimeoutTime" BU_SG_REL_ CGW SG_ 603 Dummy_RAD_FR 500;
BA_REL_ "GenSigTimeoutTime" BU_SG_REL_ CGW SG_ 160 FrntRiRSDSDisp 150;
BA_REL_ "GenSigTimeoutTime" BU_SG_REL_ CGW SG_ 160 RAD_FR_01_MsgCntr 150;
BA_REL_ "GenSigTimeoutTime" BU_SG_REL_ CGW SG_ 160 CTAFrntRiWarnReq 150;
BA_REL_ "GenSigTimeoutTime" BU_SG_REL_ CGW SG_ 160 RAD_FR_01_CRC 150;
BA_REL_ "GenSigTimeoutTime" BU_SG_REL_ CGW SG_ 599 Dummy_RAD_FL 500;
BA_REL_ "GenSigTimeoutTime" BU_SG_REL_ CGW SG_ 156 RAD_FL_01_MsgCntr 150;
BA_REL_ "GenSigTimeoutTime" BU_SG_REL_ CGW SG_ 156 FrntLeRSDSDisp 150;
BA_REL_ "GenSigTimeoutTime" BU_SG_REL_ CGW SG_ 156 CTAFrntLeWarnReq 150;
BA_REL_ "GenSigTimeoutTime" BU_SG_REL_ CGW SG_ 156 RAD_FL_01_CRC 150;
BA_REL_ "GenSigTimeoutTime" BU_SG_REL_ CGW SG_ 567 Dummy_RAD_FC 500;
BA_REL_ "GenSigTimeoutTime" BU_SG_REL_ CGW SG_ 126 ClsObjTyp 150;
BA_REL_ "GenSigTimeoutTime" BU_SG_REL_ CGW SG_ 126 DisplayVelocitySet 150;
BA_REL_ "GenSigTimeoutTime" BU_SG_REL_ CGW SG_ 126 PCWLatentWarnOnOffSts 150;
BA_REL_ "GenSigTimeoutTime" BU_SG_REL_ CGW SG_ 126 GoNotifierOnOffSts 150;
BA_REL_ "GenSigTimeoutTime" BU_SG_REL_ CGW SG_ 126 Textinfo 150;
BA_REL_ "GenSigTimeoutTime" BU_SG_REL_ CGW SG_ 126 TSRSpdLimDataOnOffSts 150;
BA_REL_ "GenSigTimeoutTime" BU_SG_REL_ CGW SG_ 126 AEBSts 150;
BA_REL_ "GenSigTimeoutTime" BU_SG_REL_ CGW SG_ 126 ClsObjDst 150;
BA_REL_ "GenSigTimeoutTime" BU_SG_REL_ CGW SG_ 126 FCWSetSts 150;
BA_REL_ "GenSigTimeoutTime" BU_SG_REL_ CGW SG_ 126 RAD_FC_03_MsgCntr 150;
BA_REL_ "GenSigTimeoutTime" BU_SG_REL_ CGW SG_ 126 RAD_FC_03_CRC 150;
BA_REL_ "GenSigTimeoutTime" BU_SG_REL_ CGW SG_ 126 TakeOverReq 150;
BA_REL_ "GenSigTimeoutTime" BU_SG_REL_ CGW SG_ 126 ObjValid 150;
BA_REL_ "GenSigTimeoutTime" BU_SG_REL_ CGW SG_ 126 PCWPreWarnOnOffSts 150;
BA_REL_ "GenSigTimeoutTime" BU_SG_REL_ CGW SG_ 126 ACC_FreeSpaceIntrusion 150;
BA_REL_ "GenSigTimeoutTime" BU_SG_REL_ CGW SG_ 126 ACC_CutInDetected 150;
BA_REL_ "GenSigTimeoutTime" BU_SG_REL_ CGW SG_ 126 ACCMode 150;
BA_REL_ "GenSigTimeoutTime" BU_SG_REL_ CGW SG_ 126 GoNotifierReq 150;
BA_REL_ "GenSigTimeoutTime" BU_SG_REL_ CGW SG_ 126 PCW_latentWarning 150;
BA_REL_ "GenSigTimeoutTime" BU_SG_REL_ CGW SG_ 126 TauGapSet 150;
BA_REL_ "GenSigTimeoutTime" BU_SG_REL_ CGW SG_ 126 PCW_preWarning 150;
BA_REL_ "GenSigTimeoutTime" BU_SG_REL_ APA SG_ 117 EPS_DrvOverRideDetn 150;
BA_REL_ "GenSigTimeoutTime" BU_SG_REL_ RAD_RR SG_ 117 EPS_02_MsgCntr 150;
BA_REL_ "GenSigTimeoutTime" BU_SG_REL_ RAD_FC SG_ 117 EPS_02_MsgCntr 150;
BA_REL_ "GenSigTimeoutTime" BU_SG_REL_ RAD_FR SG_ 117 EPS_02_MsgCntr 150;
BA_REL_ "GenSigTimeoutTime" BU_SG_REL_ RAD_RL SG_ 117 EPS_02_MsgCntr 150;
BA_REL_ "GenSigTimeoutTime" BU_SG_REL_ RAD_FL SG_ 117 EPS_02_MsgCntr 150;
BA_REL_ "GenSigTimeoutTime" BU_SG_REL_ APA SG_ 117 EPS_02_MsgCntr 150;
BA_REL_ "GenSigTimeoutTime" BU_SG_REL_ RAD_FC SG_ 117 EPS_02_CRC 150;
BA_REL_ "GenSigTimeoutTime" BU_SG_REL_ RAD_RL SG_ 117 EPS_02_CRC 150;
BA_REL_ "GenSigTimeoutTime" BU_SG_REL_ APA SG_ 117 EPS_02_CRC 150;
BA_REL_ "GenSigTimeoutTime" BU_SG_REL_ RAD_FL SG_ 117 EPS_02_CRC 150;
BA_REL_ "GenSigTimeoutTime" BU_SG_REL_ RAD_FR SG_ 117 EPS_02_CRC 150;
BA_REL_ "GenSigTimeoutTime" BU_SG_REL_ RAD_RR SG_ 117 EPS_02_CRC 150;
BA_REL_ "GenSigTimeoutTime" BU_SG_REL_ RAD_RR SG_ 117 EPS_PinionAg 150;
BA_REL_ "GenSigTimeoutTime" BU_SG_REL_ RAD_FL SG_ 117 EPS_PinionAg 150;
BA_REL_ "GenSigTimeoutTime" BU_SG_REL_ RAD_FC SG_ 117 EPS_PinionAg 150;
BA_REL_ "GenSigTimeoutTime" BU_SG_REL_ RAD_RL SG_ 117 EPS_PinionAg 150;
BA_REL_ "GenSigTimeoutTime" BU_SG_REL_ RAD_FR SG_ 117 EPS_PinionAg 150;
BA_REL_ "GenSigTimeoutTime" BU_SG_REL_ APA SG_ 117 EPS_PinionAg 150;
BA_REL_ "GenSigTimeoutTime" BU_SG_REL_ APA SG_ 117 EPS_PinionAgValid 150;
BA_REL_ "GenSigTimeoutTime" BU_SG_REL_ RAD_FC SG_ 117 EPS_PinionAgValid 150;
BA_REL_ "GenSigTimeoutTime" BU_SG_REL_ RAD_RL SG_ 117 EPS_PinionAgValid 150;
BA_REL_ "GenSigTimeoutTime" BU_SG_REL_ RAD_RR SG_ 117 EPS_PinionAgValid 150;
BA_REL_ "GenSigTimeoutTime" BU_SG_REL_ RAD_FR SG_ 117 EPS_PinionAgValid 150;
BA_REL_ "GenSigTimeoutTime" BU_SG_REL_ RAD_FL SG_ 117 EPS_PinionAgValid 150;
BA_REL_ "GenSigTimeoutTime" BU_SG_REL_ APA SG_ 116 EPS_01_CRC 150;
BA_REL_ "GenSigTimeoutTime" BU_SG_REL_ RAD_RR SG_ 116 EPS_01_CRC 150;
BA_REL_ "GenSigTimeoutTime" BU_SG_REL_ APA SG_ 116 EPS_ActvExtIf 150;
BA_REL_ "GenSigTimeoutTime" BU_SG_REL_ RAD_RR SG_ 116 EPS_ActvExtIf 150;
BA_REL_ "GenSigTimeoutTime" BU_SG_REL_ APA SG_ 116 APA_PinionAgReqAvl 150;
BA_REL_ "GenSigTimeoutTime" BU_SG_REL_ APA SG_ 116 EPSSts 150;
BA_REL_ "GenSigTimeoutTime" BU_SG_REL_ RAD_RR SG_ 116 EPSSts 150;
BA_REL_ "GenSigTimeoutTime" BU_SG_REL_ RAD_RR SG_ 116 RAD_RR_HapticWarn1Avl 150;
BA_REL_ "GenSigTimeoutTime" BU_SG_REL_ RAD_RR SG_ 116 RAD_RR_HapticWarn2Avl 150;
BA_REL_ "GenSigTimeoutTime" BU_SG_REL_ RAD_RR SG_ 116 EPS_01_MsgCntr 150;
BA_REL_ "GenSigTimeoutTime" BU_SG_REL_ APA SG_ 116 EPS_01_MsgCntr 150;
BA_REL_ "GenSigTimeoutTime" BU_SG_REL_ RAD_FR SG_ 946 Yr 5000;
BA_REL_ "GenSigTimeoutTime" BU_SG_REL_ RAD_FL SG_ 946 Yr 5000;
BA_REL_ "GenSigTimeoutTime" BU_SG_REL_ RAD_RR SG_ 946 Yr 5000;
BA_REL_ "GenSigTimeoutTime" BU_SG_REL_ RAD_RL SG_ 946 Yr 5000;
BA_REL_ "GenSigTimeoutTime" BU_SG_REL_ APA SG_ 946 Yr 5000;
BA_REL_ "GenSigTimeoutTime" BU_SG_REL_ RAD_FC SG_ 946 Yr 5000;
BA_REL_ "GenSigTimeoutTime" BU_SG_REL_ RAD_FL SG_ 946 Sec 5000;
BA_REL_ "GenSigTimeoutTime" BU_SG_REL_ RAD_FC SG_ 946 Sec 5000;
BA_REL_ "GenSigTimeoutTime" BU_SG_REL_ RAD_RL SG_ 946 Sec 5000;
BA_REL_ "GenSigTimeoutTime" BU_SG_REL_ RAD_RR SG_ 946 Sec 5000;
BA_REL_ "GenSigTimeoutTime" BU_SG_REL_ RAD_FR SG_ 946 Sec 5000;
BA_REL_ "GenSigTimeoutTime" BU_SG_REL_ APA SG_ 946 Sec 5000;
BA_REL_ "GenSigTimeoutTime" BU_SG_REL_ RAD_FL SG_ 946 Min 5000;
BA_REL_ "GenSigTimeoutTime" BU_SG_REL_ RAD_FC SG_ 946 Min 5000;
BA_REL_ "GenSigTimeoutTime" BU_SG_REL_ APA SG_ 946 Min 5000;
BA_REL_ "GenSigTimeoutTime" BU_SG_REL_ RAD_RL SG_ 946 Min 5000;
BA_REL_ "GenSigTimeoutTime" BU_SG_REL_ RAD_RR SG_ 946 Min 5000;
BA_REL_ "GenSigTimeoutTime" BU_SG_REL_ RAD_FR SG_ 946 Min 5000;
BA_REL_ "GenSigTimeoutTime" BU_SG_REL_ APA SG_ 946 Day 5000;
BA_REL_ "GenSigTimeoutTime" BU_SG_REL_ RAD_FL SG_ 946 Day 5000;
BA_REL_ "GenSigTimeoutTime" BU_SG_REL_ RAD_RL SG_ 946 Day 5000;
BA_REL_ "GenSigTimeoutTime" BU_SG_REL_ RAD_RR SG_ 946 Day 5000;
BA_REL_ "GenSigTimeoutTime" BU_SG_REL_ RAD_FR SG_ 946 Day 5000;
BA_REL_ "GenSigTimeoutTime" BU_SG_REL_ RAD_FC SG_ 946 Day 5000;
BA_REL_ "GenSigTimeoutTime" BU_SG_REL_ RAD_RL SG_ 946 Mth 5000;
BA_REL_ "GenSigTimeoutTime" BU_SG_REL_ RAD_RR SG_ 946 Mth 5000;
BA_REL_ "GenSigTimeoutTime" BU_SG_REL_ APA SG_ 946 Mth 5000;
BA_REL_ "GenSigTimeoutTime" BU_SG_REL_ RAD_FR SG_ 946 Mth 5000;
BA_REL_ "GenSigTimeoutTime" BU_SG_REL_ RAD_FC SG_ 946 Mth 5000;
BA_REL_ "GenSigTimeoutTime" BU_SG_REL_ RAD_FL SG_ 946 Mth 5000;
BA_REL_ "GenSigTimeoutTime" BU_SG_REL_ RAD_FC SG_ 946 Hr 5000;
BA_REL_ "GenSigTimeoutTime" BU_SG_REL_ RAD_FR SG_ 946 Hr 5000;
BA_REL_ "GenSigTimeoutTime" BU_SG_REL_ APA SG_ 946 Hr 5000;
BA_REL_ "GenSigTimeoutTime" BU_SG_REL_ RAD_RL SG_ 946 Hr 5000;
BA_REL_ "GenSigTimeoutTime" BU_SG_REL_ RAD_RR SG_ 946 Hr 5000;
BA_REL_ "GenSigTimeoutTime" BU_SG_REL_ RAD_FL SG_ 946 Hr 5000;
BA_REL_ "GenSigTimeoutTime" BU_SG_REL_ ADC SG_ 700 FogLiSCMCmd 500;
BA_REL_ "GenSigTimeoutTime" BU_SG_REL_ ADC SG_ 700 ReWiprSCMCmd 500;
BA_REL_ "GenSigTimeoutTime" BU_SG_REL_ ADC SG_ 700 HiBeamSCMCmd 500;
BA_REL_ "GenSigTimeoutTime" BU_SG_REL_ ADC SG_ 705 LiSnsrFailSts 500;
BA_REL_ "GenSigTimeoutTime" BU_SG_REL_ ADC SG_ 705 LiSnsrData 500;
BA_REL_ "GenSigTimeoutTime" BU_SG_REL_ ADC SG_ 957 BulbOutFenderBrkPosnLiReRi 5000;
BA_REL_ "GenSigTimeoutTime" BU_SG_REL_ ADC SG_ 957 BulbOutBrkLiTop 5000;
BA_REL_ "GenSigTimeoutTime" BU_SG_REL_ ADC SG_ 957 BulbOutFenderBrkPosnLiReLe 5000;
BA_REL_ "GenSigTimeoutTime" BU_SG_REL_ APA SG_ 707 VehState 150;
BA_REL_ "GenSigTimeoutTime" BU_SG_REL_ RAD_FC SG_ 707 VehState 150;
BA_REL_ "GenSigTimeoutTime" BU_SG_REL_ RAD_RL SG_ 707 VehState 150;
BA_REL_ "GenSigTimeoutTime" BU_SG_REL_ RAD_FL SG_ 707 VehState 150;
BA_REL_ "GenSigTimeoutTime" BU_SG_REL_ RAD_FR SG_ 707 VehState 150;
BA_REL_ "GenSigTimeoutTime" BU_SG_REL_ RAD_RR SG_ 707 VehState 150;
BA_REL_ "GenSigTimeoutTime" BU_SG_REL_ RAD_FC SG_ 737 VehDispdSpd 500;
BA_REL_ "GenSigTimeoutTime" BU_SG_REL_ RAD_FL SG_ 938 VehOdometer 5000;
BA_REL_ "GenSigTimeoutTime" BU_SG_REL_ APA SG_ 938 VehOdometer 5000;
BA_REL_ "GenSigTimeoutTime" BU_SG_REL_ RAD_RL SG_ 938 VehOdometer 5000;
BA_REL_ "GenSigTimeoutTime" BU_SG_REL_ RAD_RR SG_ 938 VehOdometer 5000;
BA_REL_ "GenSigTimeoutTime" BU_SG_REL_ RAD_FR SG_ 938 VehOdometer 5000;
BA_REL_ "GenSigTimeoutTime" BU_SG_REL_ RAD_FC SG_ 938 VehOdometer 5000;
BA_REL_ "GenSigTimeoutTime" BU_SG_REL_ APA SG_ 686 UPAReq 500;
BA_REL_ "GenSigTimeoutTime" BU_SG_REL_ ADC SG_ 686 UPAReq 500;
BA_REL_ "GenSigTimeoutTime" BU_SG_REL_ ADC SG_ 686 APAReq 500;
BA_REL_ "GenSigTimeoutTime" BU_SG_REL_ APA SG_ 686 APAReq 500;
BA_REL_ "GenSigTimeoutTime" BU_SG_REL_ ADC SG_ 685 NaviSpdLimUnit 500;
BA_REL_ "GenSigTimeoutTime" BU_SG_REL_ ADC SG_ 685 NaviSpdLim 500;
BA_REL_ "GenSigTimeoutTime" BU_SG_REL_ ADC SG_ 685 NaviSpdLimSts 500;
BA_REL_ "GenSigTimeoutTime" BU_SG_REL_ ADC SG_ 685 SetLKASteerSupportLvl 500;
BA_REL_ "GenSigTimeoutTime" BU_SG_REL_ ADC SG_ 685 NaviCurrentRoadTyp 500;
BA_REL_ "GenSigTimeoutTime" BU_SG_REL_ ADC SG_ 685 SetPilotLatContAutoEngage 500;
BA_REL_ "GenSigTimeoutTime" BU_SG_REL_ ADC SG_ 685 SetALC 500;
BA_REL_ "GenSigTimeoutTime" BU_SG_REL_ ADC SG_ 685 NavCtryCod 500;
BA_REL_ "GenSigTimeoutTime" BU_SG_REL_ ADC SG_ 685 SetPilotSteerSupportLvl 500;
BA_REL_ "GenSigTimeoutTime" BU_SG_REL_ ADC SG_ 684 MaiLiSet 500;
BA_REL_ "GenSigTimeoutTime" BU_SG_REL_ ADC SG_ 680 CDC_HU_03_MsgCntr 500;
BA_REL_ "GenSigTimeoutTime" BU_SG_REL_ ADC SG_ 680 DriverAlertSystemOnOff 500;
BA_REL_ "GenSigTimeoutTime" BU_SG_REL_ ADC SG_ 680 SetTSR 500;
BA_REL_ "GenSigTimeoutTime" BU_SG_REL_ RAD_RR SG_ 680 LCAOnOff 500;
BA_REL_ "GenSigTimeoutTime" BU_SG_REL_ ADC SG_ 680 SetLaneAssiAidTyp 500;
BA_REL_ "GenSigTimeoutTime" BU_SG_REL_ ADC SG_ 680 CDC_FailSts 500;
BA_REL_ "GenSigTimeoutTime" BU_SG_REL_ ADC SG_ 680 CDC_ADAS_FailSts 500;
BA_REL_ "GenSigTimeoutTime" BU_SG_REL_ ADC SG_ 680 AEBOnOff 500;
BA_REL_ "GenSigTimeoutTime" BU_SG_REL_ ADC SG_ 680 DAS_TactileOnOff 500;
BA_REL_ "GenSigTimeoutTime" BU_SG_REL_ ADC SG_ 680 LaneAssistTactileOnOff 500;
BA_REL_ "GenSigTimeoutTime" BU_SG_REL_ ADC SG_ 680 ACCTauGapStored 500;
BA_REL_ "GenSigTimeoutTime" BU_SG_REL_ RAD_RR SG_ 680 SdowOnOffReq 500;
BA_REL_ "GenSigTimeoutTime" BU_SG_REL_ RAD_RR SG_ 680 LCATactileWarningOnOff 500;
BA_REL_ "GenSigTimeoutTime" BU_SG_REL_ ADC SG_ 680 GoNotifierOnOff 500;
BA_REL_ "GenSigTimeoutTime" BU_SG_REL_ ADC SG_ 680 SetHMA 500;
BA_REL_ "GenSigTimeoutTime" BU_SG_REL_ ADC SG_ 680 SetLaneAssiSnvty 500;
BA_REL_ "GenSigTimeoutTime" BU_SG_REL_ RAD_RR SG_ 680 RCTAReq 500;
BA_REL_ "GenSigTimeoutTime" BU_SG_REL_ ADC SG_ 680 CDC_HU_03_CRC 500;
BA_REL_ "GenSigTimeoutTime" BU_SG_REL_ RAD_FL SG_ 788 AmbTemp 500;
BA_REL_ "GenSigTimeoutTime" BU_SG_REL_ RAD_RL SG_ 788 AmbTemp 500;
BA_REL_ "GenSigTimeoutTime" BU_SG_REL_ APA SG_ 788 AmbTemp 500;
BA_REL_ "GenSigTimeoutTime" BU_SG_REL_ RAD_FR SG_ 788 AmbTemp 500;
BA_REL_ "GenSigTimeoutTime" BU_SG_REL_ RAD_RR SG_ 788 AmbTemp 500;
BA_REL_ "GenSigTimeoutTime" BU_SG_REL_ RAD_RL SG_ 788 AmbTempValid 500;
BA_REL_ "GenSigTimeoutTime" BU_SG_REL_ RAD_FR SG_ 788 AmbTempValid 500;
BA_REL_ "GenSigTimeoutTime" BU_SG_REL_ APA SG_ 788 AmbTempValid 500;
BA_REL_ "GenSigTimeoutTime" BU_SG_REL_ RAD_RR SG_ 788 AmbTempValid 500;
BA_REL_ "GenSigTimeoutTime" BU_SG_REL_ RAD_FL SG_ 788 AmbTempValid 500;
BA_REL_ "GenSigTimeoutTime" BU_SG_REL_ CGW SG_ 552 HodWarnSeq 500;
BA_REL_ "GenSigTimeoutTime" BU_SG_REL_ CGW SG_ 552 LDWLKALaneAssiTyp 500;
BA_REL_ "GenSigTimeoutTime" BU_SG_REL_ CGW SG_ 552 AdasLeLine 500;
BA_REL_ "GenSigTimeoutTime" BU_SG_REL_ CGW SG_ 552 ACCDecelVis 500;
BA_REL_ "GenSigTimeoutTime" BU_SG_REL_ CGW SG_ 552 ACCNPSts 500;
BA_REL_ "GenSigTimeoutTime" BU_SG_REL_ CGW SG_ 552 ALCSts 500;
BA_REL_ "GenSigTimeoutTime" BU_SG_REL_ CGW SG_ 552 CAM_FC_03_CRC 500;
BA_REL_ "GenSigTimeoutTime" BU_SG_REL_ CGW SG_ 552 PilotTarObjTrackingSts 500;
BA_REL_ "GenSigTimeoutTime" BU_SG_REL_ CGW SG_ 552 ACCNPDriverMsg 500;
BA_REL_ "GenSigTimeoutTime" BU_SG_REL_ CGW SG_ 552 LKSTakeoverReq 500;
BA_REL_ "GenSigTimeoutTime" BU_SG_REL_ CGW SG_ 552 PilotLatContAutoEngage 500;
BA_REL_ "GenSigTimeoutTime" BU_SG_REL_ CGW SG_ 552 HzrdLiReq 500;
BA_REL_ "GenSigTimeoutTime" BU_SG_REL_ CGW SG_ 552 ACCAccrSts 500;
BA_REL_ "GenSigTimeoutTime" BU_SG_REL_ CGW SG_ 552 PilotSteerSupportLvl 500;
BA_REL_ "GenSigTimeoutTime" BU_SG_REL_ CGW SG_ 552 AdasRiLine 500;
BA_REL_ "GenSigTimeoutTime" BU_SG_REL_ CGW SG_ 552 LKASteerSupportLvl 500;
BA_REL_ "GenSigTimeoutTime" BU_SG_REL_ CGW SG_ 552 LaneAssiSnvty 500;
BA_REL_ "GenSigTimeoutTime" BU_SG_REL_ CGW SG_ 552 LKSSnsvty 500;
BA_REL_ "GenSigTimeoutTime" BU_SG_REL_ CGW SG_ 552 FCTAOnOffSts 500;
BA_REL_ "GenSigTimeoutTime" BU_SG_REL_ CGW SG_ 552 DoorUnlckReq 500;
BA_REL_ "GenSigTimeoutTime" BU_SG_REL_ CGW SG_ 552 ALC 500;
BA_REL_ "GenSigTimeoutTime" BU_SG_REL_ CGW SG_ 552 CAM_FC_03_MsgCntr 500;
BA_REL_ "GenSigTimeoutTime" BU_SG_REL_ APA SG_ 94 ABSActv 150;
BA_REL_ "GenSigTimeoutTime" BU_SG_REL_ RAD_RL SG_ 94 ABSActv 150;
BA_REL_ "GenSigTimeoutTime" BU_SG_REL_ RAD_FL SG_ 94 ABSActv 150;
BA_REL_ "GenSigTimeoutTime" BU_SG_REL_ RAD_RR SG_ 94 ABSActv 150;
BA_REL_ "GenSigTimeoutTime" BU_SG_REL_ RAD_FC SG_ 94 ABSActv 150;
BA_REL_ "GenSigTimeoutTime" BU_SG_REL_ RAD_FR SG_ 94 ABSActv 150;
BA_REL_ "GenSigTimeoutTime" BU_SG_REL_ RAD_RL SG_ 94 VDCDeactv 150;
BA_REL_ "GenSigTimeoutTime" BU_SG_REL_ RAD_FR SG_ 94 VDCDeactv 150;
BA_REL_ "GenSigTimeoutTime" BU_SG_REL_ RAD_RR SG_ 94 VDCDeactv 150;
BA_REL_ "GenSigTimeoutTime" BU_SG_REL_ RAD_FL SG_ 94 VDCDeactv 150;
BA_REL_ "GenSigTimeoutTime" BU_SG_REL_ RAD_FC SG_ 94 VDCDeactv 150;
BA_REL_ "GenSigTimeoutTime" BU_SG_REL_ RAD_RL SG_ 94 VDCActv 150;
BA_REL_ "GenSigTimeoutTime" BU_SG_REL_ RAD_FR SG_ 94 VDCActv 150;
BA_REL_ "GenSigTimeoutTime" BU_SG_REL_ RAD_FC SG_ 94 VDCActv 150;
BA_REL_ "GenSigTimeoutTime" BU_SG_REL_ APA SG_ 94 VDCActv 150;
BA_REL_ "GenSigTimeoutTime" BU_SG_REL_ RAD_RR SG_ 94 VDCActv 150;
BA_REL_ "GenSigTimeoutTime" BU_SG_REL_ RAD_FL SG_ 94 VDCActv 150;
BA_REL_ "GenSigTimeoutTime" BU_SG_REL_ APA SG_ 94 DTCActv 150;
BA_REL_ "GenSigTimeoutTime" BU_SG_REL_ RAD_FC SG_ 94 DTCActv 150;
BA_REL_ "GenSigTimeoutTime" BU_SG_REL_ RAD_RR SG_ 94 DTCActv 150;
BA_REL_ "GenSigTimeoutTime" BU_SG_REL_ RAD_FR SG_ 94 DTCActv 150;
BA_REL_ "GenSigTimeoutTime" BU_SG_REL_ RAD_RL SG_ 94 DTCActv 150;
BA_REL_ "GenSigTimeoutTime" BU_SG_REL_ RAD_FL SG_ 94 DTCActv 150;
BA_REL_ "GenSigTimeoutTime" BU_SG_REL_ RAD_FC SG_ 94 TCSDeactv 150;
BA_REL_ "GenSigTimeoutTime" BU_SG_REL_ RAD_RR SG_ 94 TCSDeactv 150;
BA_REL_ "GenSigTimeoutTime" BU_SG_REL_ RAD_FR SG_ 94 TCSDeactv 150;
BA_REL_ "GenSigTimeoutTime" BU_SG_REL_ RAD_RL SG_ 94 TCSDeactv 150;
BA_REL_ "GenSigTimeoutTime" BU_SG_REL_ RAD_FL SG_ 94 TCSDeactv 150;
BA_REL_ "GenSigTimeoutTime" BU_SG_REL_ RAD_RL SG_ 94 TCSActv 150;
BA_REL_ "GenSigTimeoutTime" BU_SG_REL_ RAD_RR SG_ 94 TCSActv 150;
BA_REL_ "GenSigTimeoutTime" BU_SG_REL_ RAD_FC SG_ 94 TCSActv 150;
BA_REL_ "GenSigTimeoutTime" BU_SG_REL_ APA SG_ 94 TCSActv 150;
BA_REL_ "GenSigTimeoutTime" BU_SG_REL_ RAD_FR SG_ 94 TCSActv 150;
BA_REL_ "GenSigTimeoutTime" BU_SG_REL_ RAD_FL SG_ 94 TCSActv 150;
BA_REL_ "GenSigTimeoutTime" BU_SG_REL_ RAD_RL SG_ 91 BrkPressValid 150;
BA_REL_ "GenSigTimeoutTime" BU_SG_REL_ RAD_RR SG_ 91 BrkPressValid 150;
BA_REL_ "GenSigTimeoutTime" BU_SG_REL_ RAD_FR SG_ 91 VehSpd 150;
BA_REL_ "GenSigTimeoutTime" BU_SG_REL_ APA SG_ 91 VehSpd 150;
BA_REL_ "GenSigTimeoutTime" BU_SG_REL_ RAD_FL SG_ 91 VehSpd 150;
BA_REL_ "GenSigTimeoutTime" BU_SG_REL_ RAD_FC SG_ 91 VehSpd 150;
BA_REL_ "GenSigTimeoutTime" BU_SG_REL_ RAD_RL SG_ 91 VehSpd 150;
BA_REL_ "GenSigTimeoutTime" BU_SG_REL_ RAD_RR SG_ 91 VehSpd 150;
BA_REL_ "GenSigTimeoutTime" BU_SG_REL_ RAD_RR SG_ 91 BrkPressOffset 150;
BA_REL_ "GenSigTimeoutTime" BU_SG_REL_ RAD_RL SG_ 91 BrkPressOffset 150;
BA_REL_ "GenSigTimeoutTime" BU_SG_REL_ RAD_FR SG_ 91 BCU_NoBrkF 150;
BA_REL_ "GenSigTimeoutTime" BU_SG_REL_ RAD_FL SG_ 91 BCU_NoBrkF 150;
BA_REL_ "GenSigTimeoutTime" BU_SG_REL_ RAD_FC SG_ 91 BCU_NoBrkF 150;
BA_REL_ "GenSigTimeoutTime" BU_SG_REL_ RAD_RL SG_ 91 BCU_NoBrkF 150;
BA_REL_ "GenSigTimeoutTime" BU_SG_REL_ RAD_RR SG_ 91 BCU_NoBrkF 150;
BA_REL_ "GenSigTimeoutTime" BU_SG_REL_ RAD_FR SG_ 91 BCU_04_CRC 150;
BA_REL_ "GenSigTimeoutTime" BU_SG_REL_ RAD_RR SG_ 91 BCU_04_CRC 150;
BA_REL_ "GenSigTimeoutTime" BU_SG_REL_ RAD_RL SG_ 91 BCU_04_CRC 150;
BA_REL_ "GenSigTimeoutTime" BU_SG_REL_ RAD_FC SG_ 91 BCU_04_CRC 150;
BA_REL_ "GenSigTimeoutTime" BU_SG_REL_ APA SG_ 91 BCU_04_CRC 150;
BA_REL_ "GenSigTimeoutTime" BU_SG_REL_ RAD_FL SG_ 91 BCU_04_CRC 150;
BA_REL_ "GenSigTimeoutTime" BU_SG_REL_ RAD_FC SG_ 91 VehMovgDir 150;
BA_REL_ "GenSigTimeoutTime" BU_SG_REL_ RAD_RL SG_ 91 VehMovgDir 150;
BA_REL_ "GenSigTimeoutTime" BU_SG_REL_ RAD_RR SG_ 91 VehMovgDir 150;
BA_REL_ "GenSigTimeoutTime" BU_SG_REL_ RAD_FL SG_ 91 VehMovgDir 150;
BA_REL_ "GenSigTimeoutTime" BU_SG_REL_ RAD_FR SG_ 91 VehMovgDir 150;
BA_REL_ "GenSigTimeoutTime" BU_SG_REL_ RAD_RL SG_ 91 VehSpdSts 150;
BA_REL_ "GenSigTimeoutTime" BU_SG_REL_ RAD_RR SG_ 91 VehSpdSts 150;
BA_REL_ "GenSigTimeoutTime" BU_SG_REL_ RAD_FR SG_ 91 VehSpdSts 150;
BA_REL_ "GenSigTimeoutTime" BU_SG_REL_ RAD_FL SG_ 91 VehSpdSts 150;
BA_REL_ "GenSigTimeoutTime" BU_SG_REL_ APA SG_ 91 VehSpdSts 150;
BA_REL_ "GenSigTimeoutTime" BU_SG_REL_ RAD_FC SG_ 91 VehSpdSts 150;
BA_REL_ "GenSigTimeoutTime" BU_SG_REL_ RAD_RR SG_ 91 BrkPedlSts 150;
BA_REL_ "GenSigTimeoutTime" BU_SG_REL_ RAD_RL SG_ 91 BrkPedlSts 150;
BA_REL_ "GenSigTimeoutTime" BU_SG_REL_ APA SG_ 91 EPBSts 150;
BA_REL_ "GenSigTimeoutTime" BU_SG_REL_ RAD_RR SG_ 91 BrkPress 150;
BA_REL_ "GenSigTimeoutTime" BU_SG_REL_ RAD_RL SG_ 91 BrkPress 150;
BA_REL_ "GenSigTimeoutTime" BU_SG_REL_ RAD_RR SG_ 91 BCU_04_MsgCntr 150;
BA_REL_ "GenSigTimeoutTime" BU_SG_REL_ RAD_FC SG_ 91 BCU_04_MsgCntr 150;
BA_REL_ "GenSigTimeoutTime" BU_SG_REL_ RAD_FL SG_ 91 BCU_04_MsgCntr 150;
BA_REL_ "GenSigTimeoutTime" BU_SG_REL_ RAD_RL SG_ 91 BCU_04_MsgCntr 150;
BA_REL_ "GenSigTimeoutTime" BU_SG_REL_ APA SG_ 91 BCU_04_MsgCntr 150;
BA_REL_ "GenSigTimeoutTime" BU_SG_REL_ RAD_FR SG_ 91 BCU_04_MsgCntr 150;
BA_REL_ "GenSigTimeoutTime" BU_SG_REL_ RAD_RL SG_ 91 BrkPressOffsetValid 150;
BA_REL_ "GenSigTimeoutTime" BU_SG_REL_ RAD_RR SG_ 91 BrkPressOffsetValid 150;
BA_REL_ "GenSigTimeoutTime" BU_SG_REL_ RAD_FC SG_ 90 WhlPlsCntrReLeVld 150;
BA_REL_ "GenSigTimeoutTime" BU_SG_REL_ APA SG_ 90 WhlPlsCntrReLeVld 150;
BA_REL_ "GenSigTimeoutTime" BU_SG_REL_ APA SG_ 90 WhlPlsCntrFrntLe 150;
BA_REL_ "GenSigTimeoutTime" BU_SG_REL_ RAD_FC SG_ 90 WhlPlsCntrFrntLe 150;
BA_REL_ "GenSigTimeoutTime" BU_SG_REL_ RAD_FC SG_ 90 WhlPlsCntrFrntRiVld 150;
BA_REL_ "GenSigTimeoutTime" BU_SG_REL_ APA SG_ 90 WhlPlsCntrFrntRiVld 150;
BA_REL_ "GenSigTimeoutTime" BU_SG_REL_ RAD_FC SG_ 90 BCU_03_CRC 150;
BA_REL_ "GenSigTimeoutTime" BU_SG_REL_ APA SG_ 90 BCU_03_CRC 150;
BA_REL_ "GenSigTimeoutTime" BU_SG_REL_ APA SG_ 90 WhlPlsCntrReRi 150;
BA_REL_ "GenSigTimeoutTime" BU_SG_REL_ RAD_FC SG_ 90 WhlPlsCntrReRi 150;
BA_REL_ "GenSigTimeoutTime" BU_SG_REL_ APA SG_ 90 WhlPlsCntrReRiVld 150;
BA_REL_ "GenSigTimeoutTime" BU_SG_REL_ RAD_FC SG_ 90 WhlPlsCntrReRiVld 150;
BA_REL_ "GenSigTimeoutTime" BU_SG_REL_ APA SG_ 90 WhlPlsCntrFrntLeVld 150;
BA_REL_ "GenSigTimeoutTime" BU_SG_REL_ RAD_FC SG_ 90 WhlPlsCntrFrntLeVld 150;
BA_REL_ "GenSigTimeoutTime" BU_SG_REL_ APA SG_ 90 WhlPlsCntrFrntRi 150;
BA_REL_ "GenSigTimeoutTime" BU_SG_REL_ RAD_FC SG_ 90 WhlPlsCntrFrntRi 150;
BA_REL_ "GenSigTimeoutTime" BU_SG_REL_ APA SG_ 90 WhlPlsCntrReLe 150;
BA_REL_ "GenSigTimeoutTime" BU_SG_REL_ RAD_FC SG_ 90 WhlPlsCntrReLe 150;
BA_REL_ "GenSigTimeoutTime" BU_SG_REL_ APA SG_ 90 BCU_03_MsgCntr 150;
BA_REL_ "GenSigTimeoutTime" BU_SG_REL_ RAD_FC SG_ 90 BCU_03_MsgCntr 150;
BA_REL_ "GenSigTimeoutTime" BU_SG_REL_ RAD_FC SG_ 89 WhlSpdReRiSts 150;
BA_REL_ "GenSigTimeoutTime" BU_SG_REL_ RAD_RR SG_ 89 WhlSpdReRiSts 150;
BA_REL_ "GenSigTimeoutTime" BU_SG_REL_ RAD_FL SG_ 89 WhlSpdReRiSts 150;
BA_REL_ "GenSigTimeoutTime" BU_SG_REL_ RAD_FR SG_ 89 WhlSpdReRiSts 150;
BA_REL_ "GenSigTimeoutTime" BU_SG_REL_ RAD_RL SG_ 89 WhlSpdReRiSts 150;
BA_REL_ "GenSigTimeoutTime" BU_SG_REL_ APA SG_ 89 WhlSpdReRiSts 150;
BA_REL_ "GenSigTimeoutTime" BU_SG_REL_ RAD_RR SG_ 89 WhlSpdReRiMovgDir 150;
BA_REL_ "GenSigTimeoutTime" BU_SG_REL_ RAD_FC SG_ 89 WhlSpdReRiMovgDir 150;
BA_REL_ "GenSigTimeoutTime" BU_SG_REL_ APA SG_ 89 WhlSpdReRiMovgDir 150;
BA_REL_ "GenSigTimeoutTime" BU_SG_REL_ RAD_FR SG_ 89 WhlSpdReRiMovgDir 150;
BA_REL_ "GenSigTimeoutTime" BU_SG_REL_ RAD_RL SG_ 89 WhlSpdReRiMovgDir 150;
BA_REL_ "GenSigTimeoutTime" BU_SG_REL_ RAD_FL SG_ 89 WhlSpdReRiMovgDir 150;
BA_REL_ "GenSigTimeoutTime" BU_SG_REL_ APA SG_ 89 WhlSpdReLeMovgDir 150;
BA_REL_ "GenSigTimeoutTime" BU_SG_REL_ RAD_FC SG_ 89 WhlSpdReLeMovgDir 150;
BA_REL_ "GenSigTimeoutTime" BU_SG_REL_ RAD_RR SG_ 89 WhlSpdReLeMovgDir 150;
BA_REL_ "GenSigTimeoutTime" BU_SG_REL_ RAD_FL SG_ 89 WhlSpdReLeMovgDir 150;
BA_REL_ "GenSigTimeoutTime" BU_SG_REL_ RAD_RL SG_ 89 WhlSpdReLeMovgDir 150;
BA_REL_ "GenSigTimeoutTime" BU_SG_REL_ RAD_FR SG_ 89 WhlSpdReLeMovgDir 150;
BA_REL_ "GenSigTimeoutTime" BU_SG_REL_ RAD_FC SG_ 89 BCU_02_MsgCntr 150;
BA_REL_ "GenSigTimeoutTime" BU_SG_REL_ APA SG_ 89 BCU_02_MsgCntr 150;
BA_REL_ "GenSigTimeoutTime" BU_SG_REL_ RAD_FL SG_ 89 BCU_02_MsgCntr 150;
BA_REL_ "GenSigTimeoutTime" BU_SG_REL_ RAD_RL SG_ 89 BCU_02_MsgCntr 150;
BA_REL_ "GenSigTimeoutTime" BU_SG_REL_ RAD_FR SG_ 89 BCU_02_MsgCntr 150;
BA_REL_ "GenSigTimeoutTime" BU_SG_REL_ RAD_RR SG_ 89 BCU_02_MsgCntr 150;
BA_REL_ "GenSigTimeoutTime" BU_SG_REL_ RAD_RL SG_ 89 WhlSpdReLe 150;
BA_REL_ "GenSigTimeoutTime" BU_SG_REL_ RAD_FC SG_ 89 WhlSpdReLe 150;
BA_REL_ "GenSigTimeoutTime" BU_SG_REL_ RAD_FL SG_ 89 WhlSpdReLe 150;
BA_REL_ "GenSigTimeoutTime" BU_SG_REL_ APA SG_ 89 WhlSpdReLe 150;
BA_REL_ "GenSigTimeoutTime" BU_SG_REL_ RAD_RR SG_ 89 WhlSpdReLe 150;
BA_REL_ "GenSigTimeoutTime" BU_SG_REL_ RAD_FR SG_ 89 WhlSpdReLe 150;
BA_REL_ "GenSigTimeoutTime" BU_SG_REL_ APA SG_ 89 BCU_02_CRC 150;
BA_REL_ "GenSigTimeoutTime" BU_SG_REL_ RAD_FL SG_ 89 BCU_02_CRC 150;
BA_REL_ "GenSigTimeoutTime" BU_SG_REL_ RAD_RL SG_ 89 BCU_02_CRC 150;
BA_REL_ "GenSigTimeoutTime" BU_SG_REL_ RAD_FC SG_ 89 BCU_02_CRC 150;
BA_REL_ "GenSigTimeoutTime" BU_SG_REL_ RAD_FR SG_ 89 BCU_02_CRC 150;
BA_REL_ "GenSigTimeoutTime" BU_SG_REL_ RAD_RR SG_ 89 BCU_02_CRC 150;
BA_REL_ "GenSigTimeoutTime" BU_SG_REL_ RAD_RL SG_ 89 WhlSpdReLeSts 150;
BA_REL_ "GenSigTimeoutTime" BU_SG_REL_ RAD_FL SG_ 89 WhlSpdReLeSts 150;
BA_REL_ "GenSigTimeoutTime" BU_SG_REL_ RAD_RR SG_ 89 WhlSpdReLeSts 150;
BA_REL_ "GenSigTimeoutTime" BU_SG_REL_ APA SG_ 89 WhlSpdReLeSts 150;
BA_REL_ "GenSigTimeoutTime" BU_SG_REL_ RAD_FC SG_ 89 WhlSpdReLeSts 150;
BA_REL_ "GenSigTimeoutTime" BU_SG_REL_ RAD_FR SG_ 89 WhlSpdReLeSts 150;
BA_REL_ "GenSigTimeoutTime" BU_SG_REL_ RAD_FC SG_ 89 WhlSpdReRi 150;
BA_REL_ "GenSigTimeoutTime" BU_SG_REL_ RAD_FR SG_ 89 WhlSpdReRi 150;
BA_REL_ "GenSigTimeoutTime" BU_SG_REL_ RAD_FL SG_ 89 WhlSpdReRi 150;
BA_REL_ "GenSigTimeoutTime" BU_SG_REL_ RAD_RL SG_ 89 WhlSpdReRi 150;
BA_REL_ "GenSigTimeoutTime" BU_SG_REL_ RAD_RR SG_ 89 WhlSpdReRi 150;
BA_REL_ "GenSigTimeoutTime" BU_SG_REL_ APA SG_ 89 WhlSpdReRi 150;
BA_REL_ "GenSigTimeoutTime" BU_SG_REL_ RAD_FL SG_ 88 WhlSpdFrntRiSts 150;
BA_REL_ "GenSigTimeoutTime" BU_SG_REL_ RAD_FC SG_ 88 WhlSpdFrntRiSts 150;
BA_REL_ "GenSigTimeoutTime" BU_SG_REL_ APA SG_ 88 WhlSpdFrntRiSts 150;
BA_REL_ "GenSigTimeoutTime" BU_SG_REL_ RAD_RR SG_ 88 WhlSpdFrntRiSts 150;
BA_REL_ "GenSigTimeoutTime" BU_SG_REL_ RAD_RL SG_ 88 WhlSpdFrntRiSts 150;
BA_REL_ "GenSigTimeoutTime" BU_SG_REL_ RAD_FR SG_ 88 WhlSpdFrntRiSts 150;
BA_REL_ "GenSigTimeoutTime" BU_SG_REL_ RAD_FC SG_ 88 WhlSpdFrntLeSts 150;
BA_REL_ "GenSigTimeoutTime" BU_SG_REL_ RAD_FR SG_ 88 WhlSpdFrntLeSts 150;
BA_REL_ "GenSigTimeoutTime" BU_SG_REL_ RAD_RL SG_ 88 WhlSpdFrntLeSts 150;
BA_REL_ "GenSigTimeoutTime" BU_SG_REL_ APA SG_ 88 WhlSpdFrntLeSts 150;
BA_REL_ "GenSigTimeoutTime" BU_SG_REL_ RAD_FL SG_ 88 WhlSpdFrntLeSts 150;
BA_REL_ "GenSigTimeoutTime" BU_SG_REL_ RAD_RR SG_ 88 WhlSpdFrntLeSts 150;
BA_REL_ "GenSigTimeoutTime" BU_SG_REL_ RAD_FL SG_ 88 BCU_01_CRC 150;
BA_REL_ "GenSigTimeoutTime" BU_SG_REL_ RAD_FR SG_ 88 BCU_01_CRC 150;
BA_REL_ "GenSigTimeoutTime" BU_SG_REL_ RAD_RL SG_ 88 BCU_01_CRC 150;
BA_REL_ "GenSigTimeoutTime" BU_SG_REL_ APA SG_ 88 BCU_01_CRC 150;
BA_REL_ "GenSigTimeoutTime" BU_SG_REL_ RAD_FC SG_ 88 BCU_01_CRC 150;
BA_REL_ "GenSigTimeoutTime" BU_SG_REL_ RAD_RR SG_ 88 BCU_01_CRC 150;
BA_REL_ "GenSigTimeoutTime" BU_SG_REL_ RAD_RL SG_ 88 BCU_01_MsgCntr 150;
BA_REL_ "GenSigTimeoutTime" BU_SG_REL_ RAD_RR SG_ 88 BCU_01_MsgCntr 150;
BA_REL_ "GenSigTimeoutTime" BU_SG_REL_ APA SG_ 88 BCU_01_MsgCntr 150;
BA_REL_ "GenSigTimeoutTime" BU_SG_REL_ RAD_FC SG_ 88 BCU_01_MsgCntr 150;
BA_REL_ "GenSigTimeoutTime" BU_SG_REL_ RAD_FR SG_ 88 BCU_01_MsgCntr 150;
BA_REL_ "GenSigTimeoutTime" BU_SG_REL_ RAD_FL SG_ 88 BCU_01_MsgCntr 150;
BA_REL_ "GenSigTimeoutTime" BU_SG_REL_ RAD_FR SG_ 88 WhlSpdFrntLe 150;
BA_REL_ "GenSigTimeoutTime" BU_SG_REL_ RAD_RR SG_ 88 WhlSpdFrntLe 150;
BA_REL_ "GenSigTimeoutTime" BU_SG_REL_ APA SG_ 88 WhlSpdFrntLe 150;
BA_REL_ "GenSigTimeoutTime" BU_SG_REL_ RAD_RL SG_ 88 WhlSpdFrntLe 150;
BA_REL_ "GenSigTimeoutTime" BU_SG_REL_ RAD_FL SG_ 88 WhlSpdFrntLe 150;
BA_REL_ "GenSigTimeoutTime" BU_SG_REL_ RAD_FC SG_ 88 WhlSpdFrntLe 150;
BA_REL_ "GenSigTimeoutTime" BU_SG_REL_ RAD_RL SG_ 88 WhlSpdFrntRiMovgDir 150;
BA_REL_ "GenSigTimeoutTime" BU_SG_REL_ RAD_FR SG_ 88 WhlSpdFrntRiMovgDir 150;
BA_REL_ "GenSigTimeoutTime" BU_SG_REL_ RAD_FL SG_ 88 WhlSpdFrntRiMovgDir 150;
BA_REL_ "GenSigTimeoutTime" BU_SG_REL_ RAD_RR SG_ 88 WhlSpdFrntRiMovgDir 150;
BA_REL_ "GenSigTimeoutTime" BU_SG_REL_ APA SG_ 88 WhlSpdFrntRiMovgDir 150;
BA_REL_ "GenSigTimeoutTime" BU_SG_REL_ RAD_FC SG_ 88 WhlSpdFrntRiMovgDir 150;
BA_REL_ "GenSigTimeoutTime" BU_SG_REL_ RAD_RR SG_ 88 WhlSpdFrntRi 150;
BA_REL_ "GenSigTimeoutTime" BU_SG_REL_ RAD_FC SG_ 88 WhlSpdFrntRi 150;
BA_REL_ "GenSigTimeoutTime" BU_SG_REL_ RAD_FL SG_ 88 WhlSpdFrntRi 150;
BA_REL_ "GenSigTimeoutTime" BU_SG_REL_ RAD_RL SG_ 88 WhlSpdFrntRi 150;
BA_REL_ "GenSigTimeoutTime" BU_SG_REL_ APA SG_ 88 WhlSpdFrntRi 150;
BA_REL_ "GenSigTimeoutTime" BU_SG_REL_ RAD_FR SG_ 88 WhlSpdFrntRi 150;
BA_REL_ "GenSigTimeoutTime" BU_SG_REL_ RAD_FR SG_ 88 WhlSpdFrntLeMovgDir 150;
BA_REL_ "GenSigTimeoutTime" BU_SG_REL_ RAD_RR SG_ 88 WhlSpdFrntLeMovgDir 150;
BA_REL_ "GenSigTimeoutTime" BU_SG_REL_ RAD_RL SG_ 88 WhlSpdFrntLeMovgDir 150;
BA_REL_ "GenSigTimeoutTime" BU_SG_REL_ APA SG_ 88 WhlSpdFrntLeMovgDir 150;
BA_REL_ "GenSigTimeoutTime" BU_SG_REL_ RAD_FL SG_ 88 WhlSpdFrntLeMovgDir 150;
BA_REL_ "GenSigTimeoutTime" BU_SG_REL_ RAD_FC SG_ 88 WhlSpdFrntLeMovgDir 150;
BA_REL_ "GenSigTimeoutTime" BU_SG_REL_ ADC SG_ 720 FogLiReSts 500;
BA_REL_ "GenSigTimeoutTime" BU_SG_REL_ ADC SG_ 720 ReWiprSts 500;
BA_REL_ "GenSigTimeoutTime" BU_SG_REL_ ADC SG_ 709 TpmsReLeWhlDeltaPressSts 1000;
BA_REL_ "GenSigTimeoutTime" BU_SG_REL_ ADC SG_ 709 TpmsFrntLeWhlDeltaPressSts 1000;
BA_REL_ "GenSigTimeoutTime" BU_SG_REL_ ADC SG_ 709 TpmsFrntRiWhlDeltaPressSts 1000;
BA_REL_ "GenSigTimeoutTime" BU_SG_REL_ ADC SG_ 709 TpmsReRiWhlDeltaPressSts 1000;
BA_REL_ "GenSigTimeoutTime" BU_SG_REL_ ADC SG_ 922 BrkFldLvl 5000;
BA_REL_ "GenSigTimeoutTime" BU_SG_REL_ ADC SG_ 922 BrkPadWearSts 5000;
BA_REL_ "GenSigTimeoutTime" BU_SG_REL_ ADC SG_ 706 FrntWiperParkSts 250;
BA_REL_ "GenSigTimeoutTime" BU_SG_REL_ ADC SG_ 706 FrntWiprSts 250;
BA_REL_ "GenSigTimeoutTime" BU_SG_REL_ ADC SG_ 704 FogLiFrntSts 500;
BA_REL_ "GenSigTimeoutTime" BU_SG_REL_ ADC SG_ 704 HzrdWarnSts 500;
BA_REL_ "GenSigTimeoutTime" BU_SG_REL_ ADC SG_ 704 RiTurnIndcrLiSts 500;
BA_REL_ "GenSigTimeoutTime" BU_SG_REL_ RAD_FL SG_ 704 RiTurnIndcrLiSts 500;
BA_REL_ "GenSigTimeoutTime" BU_SG_REL_ RAD_RL SG_ 704 RiTurnIndcrLiSts 500;
BA_REL_ "GenSigTimeoutTime" BU_SG_REL_ RAD_FR SG_ 704 RiTurnIndcrLiSts 500;
BA_REL_ "GenSigTimeoutTime" BU_SG_REL_ RAD_RR SG_ 704 RiTurnIndcrLiSts 500;
BA_REL_ "GenSigTimeoutTime" BU_SG_REL_ RAD_RR SG_ 704 LeTurnIndcrLiSts 500;
BA_REL_ "GenSigTimeoutTime" BU_SG_REL_ ADC SG_ 704 LeTurnIndcrLiSts 500;
BA_REL_ "GenSigTimeoutTime" BU_SG_REL_ RAD_FR SG_ 704 LeTurnIndcrLiSts 500;
BA_REL_ "GenSigTimeoutTime" BU_SG_REL_ RAD_RL SG_ 704 LeTurnIndcrLiSts 500;
BA_REL_ "GenSigTimeoutTime" BU_SG_REL_ RAD_FL SG_ 704 LeTurnIndcrLiSts 500;
BA_REL_ "GenSigTimeoutTime" BU_SG_REL_ ADC SG_ 704 LoBeamSts 500;
BA_REL_ "GenSigTimeoutTime" BU_SG_REL_ ADC SG_ 704 HiBeamSts 500;
BA_REL_ "GenSigTimeoutTime" BU_SG_REL_ APA SG_ 701 TrAjarSts 150;
BA_REL_ "GenSigTimeoutTime" BU_SG_REL_ RAD_RR SG_ 701 DoorAjarReRiSts 150;
BA_REL_ "GenSigTimeoutTime" BU_SG_REL_ RAD_RR SG_ 701 DoorAjarReLeSts 150;
BA_REL_ "GenSigTimeoutTime" BU_SG_REL_ RAD_RR SG_ 701 DoorAjarFrntRiSts 150;
BA_REL_ "GenSigTimeoutTime" BU_SG_REL_ APA SG_ 701 DoorAjarFrntLeSts 150;
BA_REL_ "GenSigTimeoutTime" BU_SG_REL_ RAD_RR SG_ 701 DoorAjarFrntLeSts 150;
BA_REL_ "GenSigTimeoutTime" BU_SG_REL_ RAD_RR SG_ 701 SeatOccpFrntLeSts 150;
VAL_ 537 VCUMotOverSpd 1 " request" 0 " no request" ;
VAL_ 537 VCUMotOverTemp 1 " request" 0 " no request" ;
VAL_ 537 VCUImdStopDriving 1 " request" 0 " no request" ;
VAL_ 537 VCUDrvModIndcn 7 " Invalid" 6 " Reserved" 5 " Reserved" 4 " Reserved" 3 " Sport mode" 2 " Comfort mode" 1 " Economy mode" 0 " Automatic Mode" ;
VAL_ 537 VCURmvAcChger 1 " request" 0 " no request" ;
VAL_ 537 CrrntLimdClsAirCdnrIndcn 1 "Request" 0 "No request" ;
VAL_ 537 DCStationCrrntLimdIndcn 1 "Limit indication" 0 "No limit indication" ;
VAL_ 537 DCChrgrPluginSts 1 "Plug in" 0 "Not plug in" ;
VAL_ 537 CrrntLimdLockVehIndcn 1 "Request" 0 "No request" ;
VAL_ 537 ACChrgrOverT 1 "Alarm" 0 "No alarm" ;
VAL_ 537 VehPwrLimdlampReq 1 "Lamp On" 0 "Lamp Off" ;
VAL_ 537 DCChrgPortTempHighIndcn 1 "Too High" 0 "Normal" ;
VAL_ 537 VCURgnCpLimdIndcn 1 "Limited" 0 "No limited" ;
VAL_ 537 VCUElecLockfail 1 " request" 0 " no request" ;
VAL_ 537 VCUShiftChangefail 1 " request" 0 " no request" ;
VAL_ 537 VCUBrakeRemind 1 " request" 0 " no request" ;
VAL_ 537 VCUVehRdy 1 " ready" 0 " no ready" ;
VAL_ 537 VCURegenSts 3 "Reserved" 2 "Off" 1 "low level" 0 "normal" ;
VAL_ 537 DCChrgrOverT 1 "Alarm" 0 "No alarm" ;
VAL_ 537 HiVoltCntctrSts 7 "Invalid" 6 "Reserved" 5 "Reserved" 4 "Reserved" 3 "Closed" 2 "Prechage" 1 "Open" 0 "Undetermine" ;
VAL_ 537 ACChrgrPluginSts 1 "Plug in" 0 "Not plug in" ;
VAL_ 537 VCUChrgDispLampReq 7 "Invalid" 6 "Reserved" 5 "Station charging error" 4 "Charging full" 3 "Vehicle charging error" 2 "Charging complete" 1 "Charging process " 0 "No charging" ;
VAL_ 537 DCChrgPortTempLowIndcn 1 "Too low" 0 "Normal" ;
VAL_ 537 ACChrgPortTempLowIndcn 1 "Too Low" 0 "Normal" ;
VAL_ 537 VCUHVILError 1 " request" 0 " no request" ;
VAL_ 537 ACChrgCurrentRng 3 "Reserved" 2 "16A and above" 1 "Below 16A" 0 "Undetermined" ;
VAL_ 537 ACChrgPortTempHighIndcn 1 "Too High" 0 "Normal" ;
VAL_ 537 ACChrgCmplSts 3 "Reserved" 2 "Completed" 1 "Not completed" 0 "Undetermined" ;
VAL_ 537 VCUFourWhlDrvIndcn 3 "No wheel driven" 2 "Four wheel driven" 1 "Rear wheel driven" 0 "Front wheel driven" ;
VAL_ 537 EPFaultLevelWarning 3 " invalid" 2 " reserved" 1 " error" 0 " no error" ;
VAL_ 537 VCUChgLineSts 1 " request" 0 " no request" ;
VAL_ 850 LVBattSOCSts 3 "Invalid" 2 "Deviation <= 10%" 1 "Deviation <= 15%" 0 "Deviation > 15%" ;
VAL_ 850 LVBattChgSts 7 " Invalid" 6 " reserved" 5 " reserved" 4 " reserved" 3 " charging fail" 2 " reserved" 1 " charging" 0 " no charge" ;
VAL_ 850 VCUHVBattCutOffWarn 3 " Invalid" 2 " Reserved" 1 " On" 0 " Off" ;
VAL_ 850 LoadShed 15 " Invalid" 14 " Reserved" 13 " Reserved" 12 " Reserved" 11 " Reserved" 10 " Reserved" 9 " Reserved" 8 " Reserved" 7 " Reserved" 6 " Load shed level 6" 5 " Load shed level 5" 4 " Load shed level 4" 3 " Load shed level 3" 2 " Load shed level 2" 1 " Load shed level 1" 0 " Normal" ;
VAL_ 850 VCULvBattWarn 3 "Invalid" 2 "Reserved" 1 "On" 0 "Off" ;
VAL_ 850 LVBattUSts 3 " Invalid" 2 " Failure" 1 " Degraded mode (from VCU)" 0 " Normal (from IBS)" ;
VAL_ 535 CruiseStatus 15 " invalid" 14 " Reserved" 13 " Reserved" 12 " Reserved" 11 " Reserved" 10 " Reserved" 9 " Reserved" 8 " Reserved" 7 " Reserved" 6 " Reserved" 5 " Reserved" 4 " Cruise Override" 3 " Cruise Active" 2 " Cruise Standby (Enabled but not functioning)" 1 " Cruise Off" 0 " Cruise Fault" ;
VAL_ 535 VCUTargetGearValid 1 " Invalid" 0 " Vaild" ;
VAL_ 535 VCUActGearValid 1 " Invalid" 0 " Vaild" ;
VAL_ 535 VCURvsLampReq 1 " Active request" 0 " Not request" ;
VAL_ 535 VCUEPBReq 3 " Invalid" 2 " Request" 1 " No request" 0 " Undetermined" ;
VAL_ 535 VCUPtWakeupReq 1 " Active request" 0 " Not request" ;
VAL_ 535 VCUCruiseCtrlMod 6 "CruiseCtrl_Resume" 5 "CruiseCtrl_Set" 4 "CruiseCtrl_DecreaseFast" 3 "CruiseCtrl_Decrease" 2 "CruiseCtrl_IncreaseFast" 1 "CruiseCtrl_Increase" 0 "CruiseCtrl_NoRequest" ;
VAL_ 535 VCUTargetGear 7 " Invalid" 6 " Reserved" 5 " Reserved" 4 " Reserved" 3 " Parking" 2 " Reverse" 1 " Drive" 0 " Neutral" ;
VAL_ 535 VCUActGear 7 " Invalid" 6 " Reserved" 5 " Reserved" 4 " Reserved" 3 " Parking" 2 " Reverse" 1 " Drive" 0 " Neutral" ;
VAL_ 535 VCUTqAvl 1 "Available" 0 "Not available" ;
VAL_ 535 VCUBrkLampReq 1 " Active request" 0 " Not request" ;
VAL_ 68 VCUTQCSts 7 "Reserved" 6 "Reserved" 5 "Reserved" 4 "Inhibt" 3 "Override" 2 "Active" 1 "Standby" 0 "Initialization" ;
VAL_ 68 VCUTotlMotPosTqCpValid 1 " Invalid" 0 " Valid" ;
VAL_ 68 VCUTotlMotNegTqCpValid 1 " Invalid" 0 " Valid" ;
VAL_ 663 FrntWiprInterSpd 7 " Invalid" 6 " Reserved" 5 " Reserved" 4 " Intermediate speed 4" 3 " Intermediate speed 3" 2 " Intermediate speed 2" 1 " Intermediate speed 1" 0 " Reserved" ;
VAL_ 663 FrntWiprSwtSts 7 " Invalid" 6 " Reserved" 5 " Reserved" 4 " Front wiper wipe one time" 3 " Front wiper intermediate speed" 2 " Front wiper high speed" 1 " Front wiper low speed" 0 " Front wiper off" ;
VAL_ 663 FogLiPushSwtSts 3 " Invalid" 2 " Reserved" 1 " Push switch pressed" 0 " Push switch not pressed" ;
VAL_ 663 WshrAndReWiprPushSwtSts 7 " Invalid" 6 " Reserved" 5 " Reserved" 4 " Reserved" 3 " Rear wiper command" 2 " Rear washer command" 1 " Front washer command" 0 " No command (default position)" ;
VAL_ 663 SCMFailSts 3 " Invalid" 2 " Reserved" 1 " Fail" 0 " Normal" ;
VAL_ 663 TurnIndcrSwtSts 3 " Invalid" 2 " Turn indicator right" 1 " Turn indicator left" 0 " No turn indicator" ;
VAL_ 663 WiprAutModPushSwtSts 3 " Invalid" 2 " Reserved" 1 " Push switch pressed" 0 " Push switch not pressed" ;
VAL_ 663 HiLowBeamPushSwtSts 3 " Invalid" 2 " Low beam or high beam command" 1 " Flash command" 0 " No command (Default position)" ;
VAL_ 212 SteerAgSnsrFailSts 3 " Invalid" 2 " Reserved" 1 " Failure" 0 " No failure" ;
VAL_ 212 SteerWhlAgDir 1 " Right (Minus)" 0 " Left (Plus)" ;
VAL_ 212 SteerWhlAgSpdDir 1 " Right (Minus)" 0 " Left (Plus)" ;
VAL_ 212 SteerWhlAgAndSpdValid 1 " Invalid" 0 " Valid" ;
VAL_ 212 SteerAgSnsrCalSts 1 " not calibrated" 0 " Calibrated" ;
VAL_ 168 BSDLCAReLeWarnReq 3 " reserved" 2 " warning level 2" 1 " warning level 1" 0 " no warning" ;
VAL_ 168 ExtReqRAD_RR 7 " Reserved" 6 " Reserved" 5 " Haptic request nb 2" 4 " Haptic request nb 1" 3 " Reserved" 2 " Reserved" 1 " Reserved" 0 " No request" ;
VAL_ 168 BSDLCAReRiWarnReq 3 " reserved" 2 " warning level 2" 1 " warning level 1" 0 " no warning" ;
VAL_ 168 SdowLeWarnReq 3 " Invalid" 2 " Reserved" 1 " Warning" 0 " No warning" ;
VAL_ 168 SDOWOnOffSts 1 "SDOW On" 0 "SDOW Off" ;
VAL_ 168 LCAHapticOnOffSts 1 "On" 0 "Off" ;
VAL_ 168 BSDLCAOnOffSts 1 " ON" 0 " OFF" ;
VAL_ 168 SdowRiWarnReq 3 " Invalid" 2 " Reserved" 1 " Warning" 0 " No warning" ;
VAL_ 168 CTAReLeWarnReq 3 " reserved" 2 " warning level 2" 1 " reserved" 0 " no warning" ;
VAL_ 168 ReRiRSDSDisp 14 "Reserved" 13 "Reserved" 12 "Reserved" 11 "Reserved" 10 "Reserved" 9 "Reserved" 8 "BSD/LCA/CTA/SDOW blindness" 7 "BSD/LCA/CTA/SDOW error" 6 "Trailer mode, CTA not available" 5 "Trailer mode, BSD/LCA not available" 4 "Reserved" 3 "Reserved" 2 "Reserved" 1 "Reserved" 0 "No display" ;
VAL_ 168 RCTAOnOffSts 1 "RCTA On" 0 "RCTA Off" ;
VAL_ 168 CTAReRiWarnReq 3 " Reserved" 2 " Warning level 2" 1 " Reserved" 0 " No warning" ;
VAL_ 160 FrntRiRSDSDisp 15 " reserved" 14 " reserved" 13 " reserved" 12 " reserved" 11 " reserved" 10 " reserved" 9 " reserved" 8 " BSD/LCA/CTA blindness" 7 " BSD/LCA/CTA error" 6 "reserved" 5 "reserved" 4 "reserved" 3 "reserved" 2 "reserved" 1 "reserved" 0 " no display" ;
VAL_ 160 CTAFrntRiWarnReq 3 "incoming traffic with immiment collision (warning lv3)" 2 "incoming traffic with potential danger (warning lv2)" 1 "incoming traffic without danger (warning lv1)" 0 " No warning" ;
VAL_ 156 FrntLeRSDSDisp 15 " reserved" 14 " reserved" 13 " reserved" 12 " reserved" 11 " reserved" 10 " reserved" 9 " reserved" 8 "BSD/LCA/CTA blindness" 7 "BSD/LCA/CTA error" 6 "reserved" 5 "reserved" 4 "reserved" 3 "reserved" 2 "reserved" 1 "reserved" 0 "no display" ;
VAL_ 156 CTAFrntLeWarnReq 3 "incoming traffic with immiment collision (warning lv3)" 2 "incoming traffic with potential danger (warning lv2)" 1 "incoming traffic without danger (warning lv1)" 0 " no warning" ;
VAL_ 126 ClsObjTyp 15 " reserved" 14 " reserved" 13 " reserved" 12 " reserved" 11 " reserved" 10 " reserved" 9 " reserved" 8 " reserved" 7 " reserved" 6 " Buss" 5 " Truck" 4 " Car" 3 " Motorcycle" 2 " Bicycle" 1 " Pedestrian" 0 " Unknown" ;
VAL_ 126 PCWLatentWarnOnOffSts 1 "On" 0 "Off" ;
VAL_ 126 GoNotifierOnOffSts 1 "On" 0 "Off" ;
VAL_ 126 Textinfo 19 " Chime only" 18 " Steering support not available" 17 " ACC not available ESP is off" 16 " ACC not available seatbelt not buckled" 15 " ACC not available brake issue present" 14 "General take over warning on inhibit" 13 "Take-Over Warning on Soft Inhibit during Controlled Deceleration" 12 " MRR blindness" 11 " ACC switched Off" 10 " ACC switched On" 9 "AEB-PEDP error(only AEB-PEDP irrerversible error)" 8 "AEB-PEDP temp error(only AEB-PEDP reversible  error)" 7 "ACC temp  error(ACC is reversible error and PEBS no error)(PEBS inluces FCW, AEB, AEB-PEDP function.)" 6 "PEBS temp error(PEBS is reversible error and ACC no error)" 5 "ACC and PEBS temp error (both ACC and PEBS are reversible error)" 4 "ACC and PEBS error (both ACC and PEBS are irreversible error)" 3 "Active" 2 "ACC cancelled" 1 "Unable to activate ACC" 0 "No display" ;
VAL_ 126 TSRSpdLimDataOnOffSts 1 "On" 0 "Off" ;
VAL_ 126 AEBSts 3 " Reserved" 2 " AEB Activate (triggered by RAD_FC)" 1 " AEB Function On by driver (or default)" 0 " AEB Function Off by driver" ;
VAL_ 126 FCWSetSts 3 "Invalid" 2 "Late" 1 "Normal" 0 "Early" ;
VAL_ 126 TakeOverReq 1 " Valid TakeOver request" 0 " No TakeOver request" ;
VAL_ 126 ObjValid 1 " Target object detected" 0 " No object" ;
VAL_ 126 PCWPreWarnOnOffSts 1 "On" 0 "Off" ;
VAL_ 126 ACC_FreeSpaceIntrusion 3 "Objects intruding from both sides" 2 "Object intruding from right side" 1 "Object intruding from left side" 0 "No free space intrusion detected" ;
VAL_ 126 ACC_CutInDetected 3 "Objects cutting in from both sides considered for longitudinal control" 2 "Object cutting in from right side became new longitudinal control target" 1 "Object cutting in from left side became new longitudinal control target" 0 "No cut-in detected" ;
VAL_ 126 ACCMode 7 "   Failure mode" 6 "   Standstill mode" 5 "   Override" 4 "   Brake-Only mode" 3 "   Active-Control mode" 2 "   Stand-By mode" 1 "   Passive mode" 0 "   OFF mode" ;
VAL_ 126 GoNotifierReq 3 " Invalid" 2 " Reserved" 1 " Request" 0 " No request" ;
VAL_ 126 PCW_latentWarning 1 " Warning" 0 " No warning" ;
VAL_ 126 TauGapSet 7 " Reserved" 6 " Reserved" 5 " Reserved" 4 " tauGap_4 (2.6s)" 3 " tauGap_3 (2.2s)" 2 " tauGap_2 (1.8s)" 1 " tauGap_1 (1.4s)" 0 " tauGap_0 (1.0s)" ;
VAL_ 126 PCW_preWarning 1 " Warning" 0 " No warning" ;
VAL_ 117 EPS_DrvOverRideDetn 3 "No active ADC request" 2 "Signal not available" 1 "Override not detected" 0 "Override detected" ;
VAL_ 117 EPS_EstRackForceValid 3 "Reserved" 2 "Signal not available" 1 "Invalid" 0 "Valid" ;
VAL_ 117 EPS_PinionAgValid 3 "Reserved" 2 "Signal not available" 1 "Invalid" 0 "Valid" ;
VAL_ 117 EPS_MotorTqValid 3 "Reserved" 2 "Signal not available" 1 "Invalid" 0 "Valid" ;
VAL_ 117 EPS_HandsOffDetnConfidence 15 "Signal not avalible" 14 "Hands-off confidence level14" 13 "Hands-off confidence level13" 12 "Hands-off confidence level12" 11 "Hands-off confidence level11" 10 "Hands-off confidence level10" 9 "Hands-off confidence level9" 8 "Hands-off confidence level8" 7 "Hands-off confidence level7" 6 "Hands-off confidence level6" 5 "Hands-off confidence level5" 4 "Hands-off confidence level4" 3 "Hands-off confidence level3" 2 "Hands-off confidence level2" 1 "Hands-off confidence level1" 0 "Hands-on" ;
VAL_ 116 DSR_AddlTqReqAvl 1 "Available" 0 "Not available" ;
VAL_ 116 EPS_ActvExtIf 15 "Signal not available" 14 "Reserved_14" 13 "Reserved_13" 12 "Reserved_12" 11 "Reserved_11" 10 "Active HI_2 request" 9 "Active HI_1 request" 8 "Active DAI request" 7 "Active PAI request " 6 "Active TOI request" 5 "Active haptic request Nb 2 RAR_RR" 4 "Active haptic request Nb 1 RAD_RR" 3 "Active absolute pinion angle request APA" 2 "Reserved_2" 1 "Active DSR request" 0 "No active request" ;
VAL_ 116 EPS_DrvngMod 7 " Invalid" 6 " Reserved_6" 5 " Reserved_5" 4 " Reserved_4" 3 " Reserved_3" 2 " Heavy" 1 " Medium (default)" 0 " Light" ;
VAL_ 116 EPS_DAIAvl 1 " Available" 0 " Not available" ;
VAL_ 116 EPS_PAIAvl 1 " Available" 0 " Not available" ;
VAL_ 116 EPS_WarnLampReq 3 "Reserved" 2 "Signal not available" 1 "On" 0 "Off" ;
VAL_ 116 APA_PinionAgReqAvl 1 "Available" 0 "Not Available" ;
VAL_ 116 EPSSts 7 "Invalid" 6 "Reserved_6" 5 "Reserved_5" 4 "Permanent error" 3 "Temporary error" 2 "Degraded" 1 "Normal" 0 "Init" ;
VAL_ 116 RAD_RR_HapticWarn1Avl 1 "Available" 0 " Not available" ;
VAL_ 116 RAD_RR_HapticWarn2Avl 1 " Available" 0 " Not available" ;
VAL_ 116 EPS_TOIAvl 1 " Available" 0 " Not available" ;
VAL_ 116 EPS_HIAvl 1 " Available" 0 " Not available" ;
VAL_ 116 EPS_TorsBarTqValid 3 "Reserved" 2 "Signal not available" 1 "Invalid" 0 "Valid" ;
VAL_ 946 Mth 15 " Invalid" 14 " Reserved" 13 " Reserved" 12 " December" 11 " November" 10 " October" 9 " September" 8 " August" 7 " July" 6 " June" 5 " May" 4 " April" 3 " March" 2 " February" 1 " January" 0 " Unknown" ;
VAL_ 700 FogLiSCMCmd 3 " Invalid" 2 " Fog lights front and rear" 1 " Fog light rear only" 0 " Fog light off" ;
VAL_ 700 ReWiprSCMCmd 3 " Invalid" 2 " Reserved" 1 " Rear wiper on" 0 " Rear wiper off" ;
VAL_ 700 HiBeamSCMCmd 3 " Invalid" 2 " Reserved" 1 " High beam" 0 " Default (low beam)" ;
VAL_ 705 HeadLampsOn 1 "Headlamp On" 0 "Headlamp Off" ;
VAL_ 705 LiSnsrFailSts 1 " Failure" 0 " Normal" ;
VAL_ 957 BulbOutFogLiFrntLe 1 " Outage" 0 " No outage" ;
VAL_ 957 BulbOutHiBeamRi 1 " Outage" 0 " No outage" ;
VAL_ 957 BulbOutTurnIndcnFrntLe 1 " Outage" 0 " No outage" ;
VAL_ 957 BulbOutTrBrkPosnLiReRi 1 " Outage" 0 " No outage" ;
VAL_ 957 BulbOutDayTiRunngLiFrntLe 1 " Outage" 0 " No outage" ;
VAL_ 957 BulbOutLoBeamLe 1 " Outage" 0 " No outage" ;
VAL_ 957 BulbOutFenderBrkPosnLiReRi 1 " Outage" 0 " No outage" ;
VAL_ 957 BulbOutTrBrkPosnLiReLe 1 " Outage" 0 " No outage" ;
VAL_ 957 BulbOutFogLiFrntRi 1 " Outage" 0 " No outage" ;
VAL_ 957 BulbOutLoBeamRi 1 " Outage" 0 " No outage" ;
VAL_ 957 BulbOutHiBeamLe 1 " Outage" 0 " No outage" ;
VAL_ 957 BulbOutResvLiLe 1 " Outage" 0 " No outage" ;
VAL_ 957 BulbOutTurnIndcnReRi 1 " Outage" 0 " No outage" ;
VAL_ 957 BulbOutFogLiReRi 1 " Outage" 0 " No outage" ;
VAL_ 957 BulbOutBrkLiTop 1 " Outage" 0 " No outage" ;
VAL_ 957 BulbOutTurnIndcnFrntRi 1 " Outage" 0 " No outage" ;
VAL_ 957 BulbOutTurnIndcnReLe 1 " Outage" 0 " No outage" ;
VAL_ 957 BulbOutFogLiReLe 1 " Outage" 0 " No outage" ;
VAL_ 957 BulbOutDayTiRunngLiFrntRi 1 " Outage" 0 " No outage" ;
VAL_ 957 BulbOutFenderBrkPosnLiReLe 1 " Outage" 0 " No outage" ;
VAL_ 957 BulbOutResvLiRi 1 " Outage" 0 " No outage" ;
VAL_ 707 KeyPrsntSts 3 "Invalid" 2 "Reserved" 1 "Key valid" 0 "No key" ;
VAL_ 707 ImobEnaReq 3 "Invalid" 2 "Enable AID2" 1 "Enable AID1" 0 "Disable" ;
VAL_ 707 ComfEna 3 " Invalid" 2 " Reserved" 1 " Comfort enabled" 0 " Comfort not enabled" ;
VAL_ 707 FOTAHvPwrMgnt 3 "Invalid" 2 "Reserved" 1 "FOTA high voltage power management enable" 0 "FOTA high voltage power management disable" ;
VAL_ 707 ImobSts 3 "Immo Failure ( PEUF/R or BCM) " 2 "Not Authorised ( NFC)" 1 "No key Present  " 0 "No Error" ;
VAL_ 707 VehState 15 " Invalid" 14 " Reserved" 13 " Reserved" 12 " Reserved" 11 " Reserved" 10 " Reserved" 9 " Reserved" 8 " Reserved" 7 " Reserved" 6 " Reserved" 5 " Reserved" 4 " Reserved" 3 " Software update" 2 " Driving" 1 "Driver present(On)" 0 "Parked vehicle(Off)" ;
VAL_ 707 KeyAuthSts 3 " Reserved" 2 " Fail" 1 " Pass (valid)" 0 " Idle" ;
VAL_ 737 AirbLampFailSts 3 " Failure" 2 " No failure AND lamp Blinking" 1 " No failure AND lamp On" 0 " No failure AND lamp Off" ;
VAL_ 737 AirbPassLampFailSts 3 " Failure" 2 " No failure AND lamp blinking" 1 " No failure AND lamp On" 0 " No failure AND lamp Off" ;
VAL_ 737 IC_VideoSrcReq 3 "Invalid" 2 "Reserved" 1 "Active" 0 "Not active" ;
VAL_ 686 TowModActv 3 " signal fault" 2 " Tow Mode active" 1 " Tow mode not active" 0 " Undefined" ;
VAL_ 686 ACChrgCurrentLimReq 3 "Reserved" 2 "Limited to 32A" 1 "Limited to 16A" 0 "Undetermined" ;
VAL_ 686 HVPwrInhbReq 3 "Reserved" 2 "Reserved" 1 "Inhibit" 0 "Not Inhibit" ;
VAL_ 686 HMIStopChargingReq 3 "Reserved" 2 "Request" 1 "No Request" 0 "Undetermined" ;
VAL_ 686 UPAReq 3 " Invalid" 2 " Reserved" 1 " Off" 0 " On" ;
VAL_ 686 HillDescentControlReq 3 " Invalid" 2 " Reserved" 1 " Off" 0 " On" ;
VAL_ 686 ESCAndTCSReq 3 " Invalid" 2 " Reserved" 1 " Off" 0 " On" ;
VAL_ 686 APAReq 15 " Invalid" 14 " Reserved" 13 " Reserved" 12 " Reserved" 11 " Reserved" 10 " Reserved" 9 " Sna" 8 " Abort" 7 " PocRight" 6 " PocLeft" 5 " CrossRight" 4 " CrossLeft" 3 " ParallelRight" 2 " ParallelLeft" 1 " Search" 0 " None" ;
VAL_ 686 TowEPBReq 3 " Invalid" 2 " Reserved" 1 " EPB apply" 0 " No request" ;
VAL_ 686 LC_EasyEntryEna 3 "signal fault" 2 "undefined" 1 "Enabled" 0 "Not enabled" ;
VAL_ 686 CreepOnOff 3 " Invalid" 2 " Reserved" 1 " Off" 0 " On" ;
VAL_ 686 TowModOnOff 3 " signal fault" 2 " Tow Mode On" 1 " Tow mode Off" 0 " Undefined" ;
VAL_ 686 CargoReq 3 "Invalid" 2 "Reserved" 1 "Off" 0 "On" ;
VAL_ 686 APAPrkgModReq 15 " Invalid" 6 " -14 Reserved" 5 " Not parking" 4 " Park in" 3 " Parking exit" 1 " Perpendicular parking" 0 " Parallel parking" ;
VAL_ 686 PassAirbInhbnReq 3 " Invalid" 2 " Reserved" 1 " Passenger airbag Off" 0 " Passenger airbag On" ;
VAL_ 686 CDCUnlockACChrgr 3 "Reserved" 2 "No unlock request" 1 "Unlock request" 0 "Undetermined" ;
VAL_ 686 CDC_EPBSwtSts 3 " Invalid" 2 " Reserved" 1 " Pressed" 0 " Not pressed" ;
VAL_ 686 LC_Deactivation_Request 3 " signal fault" 2 " undefined" 1 " requested" 0 " no request" ;
VAL_ 685 NaviSpdLimUnit 3 " Reserved." 2 " mph" 1 " km/h" 0 " Unknown" ;
VAL_ 685 NaviSpdLimSts 3 " Plural data exsits." 2 " No limit (no limitation, e.g. Germany motor way)" 1 " Exists (data available)" 0 " Unknown" ;
VAL_ 685 SetLKASteerSupportLvl 3 "Invalid" 2 "Strong steering force" 1 "Medium steering force" 0 "Light steering forc" ;
VAL_ 685 NaviCurrentRoadTyp 15 " Reserved" 14 " Reserved" 13 " Reserved" 12 " Reserved" 11 " Reserved" 10 " Reserved" 9 " Reserved" 8 " Reserved" 7 " Highway" 6 " City Highway" 5 " National road" 4 " Provincial major" 3 " Local major" 2 " Local" 1 " Pedestrian" 0 " Unknown" ;
VAL_ 685 SetPilotLatContAutoEngage 3 "Invalid" 2 "Reserved" 1 "Manual" 0 "Auto" ;
VAL_ 685 SetALC 3 "Invalid" 2 "On turn light and driver torque" 1 "On turn light only" 0 "Off" ;
VAL_ 685 SetPilotSteerSupportLvl 3 "Invalid" 2 "Strong lane centering support" 1 "Medium lane centering support" 0 "Light lane centering support" ;
VAL_ 684 MaiLiSet 7 " Invalid" 6 " Reserved" 5 " Reserved" 4 " Reserved" 3 " Automatic" 2 " Low Beam" 1 " Position light" 0 " Light off" ;
VAL_ 684 FolwMeHomeOnOff 3 " Invalid" 2 " Reserved" 1 " On" 0 " Off" ;
VAL_ 684 FolwMeHomeTiSet 7 " Invalid" 6 " Reserved" 5 " Reserved" 4 " Reserved" 3 " Reserved" 2 " 60 seconds" 1 " 30 seconds" 0 " 15 seconds" ;
VAL_ 684 WiprSrvReq 3 " Invalid" 2 " Service requested" 1 " Service not requested" 0 " No action" ;
VAL_ 684 ReWiprAutoSetOnOff 3 " Invalid" 2 " Reserved" 1 " On" 0 " Off" ;
VAL_ 684 StrWhlHeatingReq 7 "Invalid" 6 "Reserved" 5 "Reserved" 4 "Reserved" 3 "Reserved" 2 "Reserved" 1 "Heater on" 0 "No heater" ;
VAL_ 684 WelcomeLiOnOff 3 " Invalid" 2 " Reserved" 1 " On" 0 " Off" ;
VAL_ 684 ExtraWiprModOnOff 3 " Invalid" 2 " Reserved" 1 " On" 0 " Off" ;
VAL_ 684 AVAOnOffReq 3 " Invalid" 2 " Reserved" 1 " On(Default)" 0 " Off" ;
VAL_ 684 AmbLiOnOff 3 " Invalid" 2 " Reserved" 1 " On" 0 " Off" ;
VAL_ 684 CbnLiSet 3 " Invalid" 2 " Reserved" 1 " Cabin light On (when opening door)" 0 " Cabin ligh Off (when opening door)" ;
VAL_ 680 GuestModCdcReq 3 "Invalid" 2 "Turn Off Guest Mode" 1 "Turn On Guest Mode" 0 "No request" ;
VAL_ 680 DriverAlertSystemOnOff 3 " Invalid" 2 " Reserved" 1 " On" 0 " Off" ;
VAL_ 680 TSRSpdLimDataOnOff 3 " Invalid" 2 " Reserved" 1 " On" 0 " Off" ;
VAL_ 680 SetTSR 3 " Invalid" 2 " Reserved" 1 " TSR On" 0 " TSR Off" ;
VAL_ 680 LCAOnOff 3 " Invalid" 2 " Reserved" 1 " On" 0 " Off" ;
VAL_ 680 FCWSet 3 "Invalid" 2 "Late" 1 "Normal" 0 "Early" ;
VAL_ 680 SetLaneAssiAidTyp 7 " Invalid" 6 " Reserved" 5 " LDW and LKS" 4 " LDW and LKA" 3 " LKS" 2 " LKA" 1 " LDW" 0 " Off" ;
VAL_ 680 CDC_FailSts 3 "Invalid" 2 "Reserved" 1 "Failure" 0 "No failure" ;
VAL_ 680 CDC_ADAS_FailSts 1 "Failure" 0 "No failure" ;
VAL_ 680 PCW_PreWarningOnOff 3 " Invalid" 2 " Reserved" 1 " On" 0 " Off" ;
VAL_ 680 PCW_LatentWarningOnOff 3 " Invalid" 2 " Reserved" 1 " On" 0 " Off" ;
VAL_ 680 AEBOnOff 3 " Invalid" 2 " Reserved" 1 " On" 0 " Off" ;
VAL_ 680 DAS_TactileOnOff 3 " Invalid" 2 " Reserved" 1 " On" 0 " Off" ;
VAL_ 680 LaneAssistTactileOnOff 3 " Invalid" 2 " Reserved" 1 " On" 0 " Off" ;
VAL_ 680 ACCTauGapStored 7 " Reserved" 6 " Reserved" 5 " Reserved" 4 " tauGap_3 (2.6s)" 3 " tauGap_3 (2.2s)" 2 " tauGap_2 (1.8s)" 1 " tauGap_1 (1.4s)" 0 " tauGap_0 (1.0s)" ;
VAL_ 680 SdowOnOffReq 3 " Invalid" 2 " Reserved" 1 " On" 0 " Off" ;
VAL_ 680 LCATactileWarningOnOff 3 " Invalid" 2 " Reserved" 1 " On" 0 " Off" ;
VAL_ 680 FCTAOnOffCmd 3 " Invalid" 2 " Reserved" 1 " On" 0 " Off" ;
VAL_ 680 VldKeyfobChkReq 3 "Invalid" 2 "Reserved" 1 "Request" 0 "No request" ;
VAL_ 680 GoNotifierOnOff 3 " Invalid" 2 " Reserved" 1 " On" 0 " Off" ;
VAL_ 680 SetHMA 3 " Invalid" 2 " Reserved" 1 " High Beam Assist (HMA) On" 0 " High Beam Assist (HMA) Off" ;
VAL_ 680 SetLaneAssiSnvty 3 " Invalid" 2 " High sensitivity" 1 " Normal sensitivity" 0 " Low sensitivity" ;
VAL_ 680 RCTAReq 3 " Invalid" 2 " Reserved" 1 " On" 0 " Off" ;
VAL_ 788 CbnACSysSts 1 "Active" 0 "Not active" ;
VAL_ 788 CCUActPwrLimEna 1 "Enable" 0 "Disable" ;
VAL_ 788 PtcReFailSts 1 " PTC rear failure" 0 " PTC rear no failure" ;
VAL_ 788 PtcFrntFailSts 1 " PTC front failure" 0 " PTC front no failure" ;
VAL_ 788 CmprOnOffSts 1 " Compressor On" 0 " Compressor Off" ;
VAL_ 788 PtcReOnOffSts 1 " PTC rear On" 0 " PTC rear Off" ;
VAL_ 788 PtcFrntOnOffSts 1 " PTC front On" 0 " PTC front Off" ;
VAL_ 788 ComprFaultSts 1 " Compressor failure" 0 " No failure" ;
VAL_ 788 ComprlimSts 1 "Rpm limited" 0 "Rpm not limited" ;
VAL_ 788 AmbTempValid 1 " Ambient temperature not valid" 0 " Ambient temperature valid" ;
VAL_ 552 HodWarnSeq 7 "Reserved" 6 "Reserved" 5 "Hands-off level5" 4 "Hands-off level4" 3 "Hands-off level3" 2 "Hands-off level2" 1 "Hands-off level1" 0 "Hands-on" ;
VAL_ 552 LDWLKALaneAssiTyp 7 " Invalid" 6 " Reserved" 5 " LDW and LKS" 4 " LDW and LKA" 3 " LKS" 2 " LKA" 1 " LDW" 0 " Not selected" ;
VAL_ 552 AdasLeLine 7 "Left line active lane change-aborted" 6 "Left line active lane change-ongoing" 5 "Left line active lane change-preparing" 4 "Left line as L2 Pilot target" 3 "Left LKA warning" 2 "Left LDW warning" 1 "Left line detected" 0 "Left line not detected" ;
VAL_ 552 ACCDecelVis 3 "mid strength deceleration" 2 "soft deceleration" 1 "decel imminent" 0 "no deceleration imminent " ;
VAL_ 552 ACCNPSts 7 "Pilot Standby" 6 "Lateral Unavailable" 5 "Pilot Active" 4 "ACC Standby" 3 "ACC Active" 2 "System Ready" 1 "System Passive" 0 "System Off" ;
VAL_ 552 ALCSts 3 "ALC currently preparing for or conducting a lane change" 2 "ALC setting on and ready (would engage if triggered)" 1 "ALC setting on, but not all activation conditions true" 0 "ALC setting off" ;
VAL_ 552 PilotTarObjTrackingSts 3 "Invalid" 2 "Reserved" 1 "Lateral control on target object" 0 "No lateral control on target object" ;
VAL_ 552 LKSTakeoverReq 1 " Active" 0 " Inactive" ;
VAL_ 552 PilotLatContAutoEngage 3 "Invalid" 2 "Reserved" 1 "Manual" 0 "Auto" ;
VAL_ 552 HzrdLiReq 3 "Invalid" 2 "Reserved" 1 "Request to activate hazard lights" 0 "No request for hazard lights" ;
VAL_ 552 ACCAccrSts 3 "acceleration" 2 "standstill" 1 "deceleration" 0 "no value" ;
VAL_ 552 PilotSteerSupportLvl 3 "Invalid" 2 "Strong lane centering support" 1 "Medium lane centering support" 0 "Light lane centering support" ;
VAL_ 552 AdasRiLine 7 "Right line active lane change-aborted" 6 "Right line active lane change-ongoing" 5 "Right line active lane change-preparing" 4 "Right line as L2 Pilot target" 3 "Right LKA warning" 2 "Right LDW warning" 1 "Right line detected" 0 "Right line not detected" ;
VAL_ 552 LKASteerSupportLvl 3 "Invalid" 2 "Strong steering force" 1 "Medium steering force" 0 "Light steering force" ;
VAL_ 552 LaneAssiSnvty 3 " Invalid" 2 " High sensitivity" 1 " Normal sensitivity" 0 " Low sensitivity" ;
VAL_ 552 LKSSnsvty 3 " Reserved" 2 " HighSensitivity" 1 " NormalSensitivity" 0 " LowSensitivity" ;
VAL_ 552 FCTAOnOffSts 3 "Invalid" 2 "Reserved" 1 "On" 0 "Off" ;
VAL_ 552 DoorUnlckReq 3 "Invalid" 2 "Reserved" 1 "Request to unlock door" 0 "No request to unlock door" ;
VAL_ 552 ALC 3 "Invalid" 2 "On turn light and driver torque" 1 "On turn light only" 0 "Off" ;
VAL_ 94 QDCACCFail 3 "Reserved" 2 "Reserved" 1 "Error" 0 "No error" ;
VAL_ 94 ABSActv 1 " Active" 0 " Not active" ;
VAL_ 94 PEDPActv 1 " Active" 0 " Not active" ;
VAL_ 94 CDDSActv 1 " Active" 0 " Not active" ;
VAL_ 94 VDCDeactv 1 " Deactivated" 0 " Not deactivated" ;
VAL_ 94 AutoBrkgActv 1 " Active" 0 " Not active" ;
VAL_ 94 VDCActv 1 " Active" 0 " Not active" ;
VAL_ 94 AVHSts 3 "Reserved" 2 "Active(AVH lamp on with green color)" 1 "Standby(AVH lamp off)" 0 "Failure(AVH lamp on with yellow color)" ;
VAL_ 94 ABPAvl 1 " available" 0 " Not available" ;
VAL_ 94 AutoBrkgAvl 1 "Available" 0 "Not available" ;
VAL_ 94 HRBActv 1 " Active" 0 " Not active" ;
VAL_ 94 CDPAvail 1 " available" 0 " Not available" ;
VAL_ 94 ABAAvl 1 " available" 0 " Not available" ;
VAL_ 94 EBDActv 1 " Active" 0 " Not active" ;
VAL_ 94 ABPActv 1 " Active" 0 " Not active" ;
VAL_ 94 AEBAvl 1 " available" 0 " Not available" ;
VAL_ 94 HBAActv 1 "Active" 0 "Not active" ;
VAL_ 94 ECDTTempOffs 1 " Temeprature too high" 0 " Temperature not high" ;
VAL_ 94 HHCActv 1 " Active" 0 " Not active" ;
VAL_ 94 AWBAvl 1 " available" 0 " Not available" ;
VAL_ 94 HFCActv 1 " Active" 0 " Not active" ;
VAL_ 94 DTCActv 1 " Active" 0 " Not active" ;
VAL_ 94 HDCSts 3 "Active" 2 "Standby" 1 "Failure" 0 "Off" ;
VAL_ 94 StandstillSts 7 "Reserved" 6 "Reserved" 5 "Parked vehicle (autonomous park brake)" 4 "Transition to a non-hold" 3 "Hold by service brakes" 2 "Temporary Hold by service brakes" 1 "Soft-Stop" 0 "Non hold" ;
VAL_ 94 EBAActv 1 " Active" 0 " Not active" ;
VAL_ 94 AEBActv 1 " Active" 0 " Not active" ;
VAL_ 94 AWBActv 1 " Active" 0 " Not active" ;
VAL_ 94 ABAActv 1 " Active" 0 " Not active" ;
VAL_ 94 TCSDeactv 1 " Deactivated" 0 " Not deactivated" ;
VAL_ 94 CDPActv 1 " Active" 0 " Not active" ;
VAL_ 94 EBAAvl 1 " available" 0 " Not available" ;
VAL_ 94 SCMAvl 1 " available" 0 " Not available" ;
VAL_ 94 CDDSAvl 1 " available" 0 " Not available" ;
VAL_ 94 SCMActv 1 " Active" 0 " Not active" ;
VAL_ 94 HHCAvail 1 " available" 0 " Not available" ;
VAL_ 94 PEDPAvl 1 " available" 0 " Not available" ;
VAL_ 94 TCSActv 1 " Active" 0 " Not active" ;
VAL_ 91 BrkPressValid 1 " Invalid" 0 " Valid" ;
VAL_ 91 BCU_NoBrkF 1 " Brake force applied" 0 " No brake force applied" ;
VAL_ 91 VehMovgDir 3 "Reserved" 2 "Backward" 1 "Forward" 0 "Standstill" ;
VAL_ 91 VehSpdSts 1 " Invalid" 0 " Valid" ;
VAL_ 91 BrkPedlSts 3 " Invalid (Error)" 2 " Reserved" 1 " Pressed" 0 " Not pressed" ;
VAL_ 91 BCUBrkLiReq 3 " Invalid" 2 " Reserved" 1 " Request" 0 " No request" ;
VAL_ 91 EPBSts 7 " Reserved" 6 " Reserved" 5 " Reserved" 4 " EPB applying" 3 " EPB not applied" 2 " EPB releasing" 1 " EPB applied" 0 " Unknown" ;
VAL_ 91 EPBSwtSts 3 " Invalid" 2 " Reserved" 1 " Pressed" 0 " Not pressed" ;
VAL_ 91 BrkOverHeat 1 " Brake temperature too high" 0 " Brake temperature not high" ;
VAL_ 91 HAZReq 1 " Hazard warning request" 0 " Hazard warning no request" ;
VAL_ 91 BrkPressOffsetValid 1 " Invalid" 0 " Valid" ;
VAL_ 90 WhlPlsCntrReLeVld 1 " Invalid" 0 " Valid" ;
VAL_ 90 WhlPlsCntrFrntRiVld 1 " Invalid" 0 " Valid" ;
VAL_ 90 WhlPlsCntrReRiVld 1 " Invalid" 0 " Valid" ;
VAL_ 90 WhlPlsCntrFrntLeVld 1 " Invalid" 0 " Valid" ;
VAL_ 89 WhlSpdReRiSts 3 " Reserved" 2 " Initialization" 1 " Invalid" 0 " Valid" ;
VAL_ 89 WhlSpdReRiMovgDir 3 " Invalid" 2 " Backward" 1 " Forward" 0 " Standstill" ;
VAL_ 89 WhlSpdReLeMovgDir 3 " Invalid" 2 " Backward" 1 " Forward" 0 " Standstill" ;
VAL_ 89 WhlSpdReLeSts 3 " Reserved" 2 " Initialization" 1 " Invalid" 0 " Valid" ;
VAL_ 88 WhlSpdFrntRiSts 3 " Reserved" 2 " Initialization" 1 " Invalid" 0 " Valid" ;
VAL_ 88 WhlSpdFrntLeSts 3 " Reserved" 2 " Initialization" 1 " Invalid" 0 " Valid" ;
VAL_ 88 WhlSpdFrntRiMovgDir 3 " Invalid" 2 " Backward" 1 " Forward" 0 " Standstill" ;
VAL_ 88 WhlSpdFrntLeMovgDir 3 " Invalid" 2 " Backward" 1 " Forward" 0 " Standstill" ;
VAL_ 720 PuddleLiTrCmdSts 3 " Invalid or failure" 2 " Reserved" 1 " On" 0 " Off" ;
VAL_ 720 FogLiReSts 3 " Invalid" 2 " Reserved" 1 " On" 0 " Off" ;
VAL_ 720 BCMVoltWakeupReq 3 "Invalid" 2 "Reserved" 1 "Request" 0 "No request(default)" ;
VAL_ 720 ChrgrPortACAjarSts 3 "Invalid" 2 "Reserved" 1 "Closed" 0 "Opened" ;
VAL_ 720 WshingTankPortAjarSts 3 "Invalid" 2 "Reserved" 1 "Closed" 0 "Opened" ;
VAL_ 720 WshrMotDir 3 " Invalid" 2 " Motor washer rear" 1 " Motor washer front" 0 " Motor Off" ;
VAL_ 720 TrLiSts 3 " Invalid or failure" 2 " Reserved" 1 " On" 0 " Off" ;
VAL_ 720 ReWinDefrstSts 3 "Invalid" 2 "Reserved" 1 "On" 0 "Off" ;
VAL_ 720 RvsLiSts 3 " Invalid" 2 " Reserved" 1 " On" 0 " Off" ;
VAL_ 720 QuickAcsBtn 3 "Invalid" 2 "Reserved" 1 "Pressed" 0 "Not pressed" ;
VAL_ 720 WiprWshrPmpFailSts 3 " Invalid" 2 " Reserved" 1 " Failure" 0 " Normal" ;
VAL_ 720 ChrgrPortDCAjarSts 3 "Invalid" 2 "Reserved" 1 "Closed" 0 "Opened" ;
VAL_ 720 ReWiprBlkSts 3 " Invalid" 2 " Reserved" 1 " Block" 0 " No block" ;
VAL_ 720 ReWiprParkSts 3 " Invalid" 2 " Reserved" 1 " No park" 0 " Park" ;
VAL_ 720 BrkLiSts 3 " Invalid" 2 " Blinking" 1 " On" 0 " Off" ;
VAL_ 720 ReWiprSts 3 " Invalid" 2 " Reserved" 1 " Rear wiper on" 0 " Rear wiper off" ;
VAL_ 709 TpmsFrntLeWhlTempSts 1 " High temperature" 0 " Nornal" ;
VAL_ 709 TpmsFrntLeWhlPressSts 3 "Description for the value '0x3'" 2 "Low pressure" 1 "Reserved" 0 "Normal Pressure" ;
VAL_ 709 TpmsReLeBatSts 1 "Low voltage" 0 "Normal voltage" ;
VAL_ 709 TpmsFrntRiWhlPressSts 3 "Reserved" 2 "Low pressure" 1 "Reserved" 0 "Normal Pressure" ;
VAL_ 709 TpmsReRiWhlTempSts 1 " High temperature" 0 " Nornal" ;
VAL_ 709 TpmsFrntRiWhlTempSts 1 " High temperature" 0 " Nornal" ;
VAL_ 709 TpmsReLeWhlDeltaPressSts 1 "Pressure changed fast" 0 "Pressure not changed fast" ;
VAL_ 709 TpmsFrntLeBatSts 1 "Low voltage" 0 "Normal voltage" ;
VAL_ 709 TpmsReRiBatSts 1 "Low voltage" 0 "Normal voltage" ;
VAL_ 709 TpmsReRiSnsrFailSts 1 " Failure" 0 " No failure" ;
VAL_ 709 TpmsFrntRiBatSts 1 "Low voltage" 0 "Normal voltage" ;
VAL_ 709 TpmsFrntLeWhlDeltaPressSts 1 "Pressure changed fast" 0 "Pressure not changed fast" ;
VAL_ 709 TpmsReRiWhlPressSts 3 "Reserved" 2 "Low pressure" 1 "Reserved" 0 "Normal Pressure" ;
VAL_ 709 TpmsFrntLeSnsrFailSts 1 " Failure" 0 " No failure" ;
VAL_ 709 TpmsReLeWhlPressSts 3 "Reserved" 2 "Low pressure" 1 "Reserved" 0 "Normal Pressure" ;
VAL_ 709 TpmsReLeWhlTempSts 1 " High temperature" 0 " Nornal" ;
VAL_ 709 TpmsSts 3 "Reserved" 2 "Pressure abnormal" 1 "System Not OK" 0 "System OK" ;
VAL_ 709 TpmsFrntRiSnsrFailSts 1 " Failure" 0 " No failure" ;
VAL_ 709 TpmsReLeSnsrFailSts 1 " Failure" 0 " No failure" ;
VAL_ 709 TpmsFrntRiWhlDeltaPressSts 1 "Description for the value '0x1'" 0 "Pressure not changed fast" ;
VAL_ 709 TpmsReRiWhlDeltaPressSts 1 "Pressure changed fast" 0 "Pressure not changed fast" ;
VAL_ 922 BrkFldLvl 3 " Invalid" 2 " Reserved" 1 " Level low" 0 " Level normal" ;
VAL_ 922 LockFailWarnReq 1 " Off" 0 " On" ;
VAL_ 922 LockFailSrc 7 " Invalid" 6 " Reserved" 5 " Reserved" 4 " Reserved" 3 " Reserved" 2 " One of the door or trunk is opened" 1 " Vehicle state" 0 " No failure" ;
VAL_ 922 FindMeSts 3 "Invalid" 2 "Reserved" 1 "FindMe status on" 0 "FindMe status off" ;
VAL_ 922 PEPS_FOBLowBATWarning 1 " On" 0 " Off" ;
VAL_ 922 AntiTheftWarnSts 7 "Reserved" 6 "Reserved" 5 "Reserved" 4 "Alarm" 3 "Reserved" 2 "Armed" 1 "Partial armed" 0 "Disarmed" ;
VAL_ 922 PEPS_ECUFailWarning 1 " On" 0 " Off" ;
VAL_ 922 BrkFldWarnReq 3 " Invalid" 2 " Reserved" 1 " Warning" 0 " No warning" ;
VAL_ 922 BrkPadWearSts 3 " Invalid" 2 " Reserved" 1 " Pad worn" 0 " Normal" ;
VAL_ 922 KeyInsdWarnReq 1 " Off" 0 " On" ;
VAL_ 922 BrkPadWearWarnReq 3 " Invalid" 2 " Reserved" 1 " Warning" 0 " No warning" ;
VAL_ 922 KeyOutWarnReq 1 " On" 0 " Off" ;
VAL_ 706 MirrFrntRiSts 3 " Invalid" 2 " Folding / unfolding" 1 " Folded" 0 " Not folded" ;
VAL_ 706 MirrCtrlSts 7 "Invalid" 6 "Reserved" 5 "Reserved" 4 "Reserved" 3 "System failure" 2 "Recall" 1 "Manual control" 0 "No action" ;
VAL_ 706 FrntWiperBlkSts 3 " Invalid" 2 " Reserved" 1 " Block" 0 " No block" ;
VAL_ 706 FrntWiperParkSts 3 " Invalid" 2 " Reserved" 1 " No park" 0 " Park" ;
VAL_ 706 WiprServReqSts 3 " Invalid" 2 " Reserved" 1 " Wiper service enabled" 0 " Wiper service disabled" ;
VAL_ 706 MirrFrntLeSts 3 " Invalid" 2 " Folding / unfolding" 1 " Folded" 0 " Not folded" ;
VAL_ 706 WiprWshrLvl 3 " Invalid" 2 " Reserved" 1 " Level low" 0 " Level normal" ;
VAL_ 706 FrntWiprSts 7 " Invalid" 6 " Reserved" 5 " Reserved" 4 " Reserved" 3 " Reserved" 2 " Front wiper high speed" 1 " Front wiper low speed" 0 " Front wiper off" ;
VAL_ 706 MirrHeatSts 3 " Invalid" 2 " Reserved" 1 " Heater On" 0 " Heater Off" ;
VAL_ 704 ScurKeyInvd 3 " Reserved" 2 " Reserved" 1 " Key invalid" 0 " Key valid" ;
VAL_ 704 FogLiFrntRiDrvrSts 3 " Invalid" 2 " Reserved" 1 " On" 0 " Off" ;
VAL_ 704 FogLiFrntSts 3 " Invalid" 2 " Reserved" 1 " On" 0 " Off" ;
VAL_ 704 WelcomeLiReq 3 "Invalid" 2 "Reserved" 1 "Request" 0 "No request" ;
VAL_ 704 HzrdWarnSts 3 " Invalid" 2 " On 1 Hz (Alarm flash)" 1 " On 1.25 Hz (Hazard)" 0 " Off" ;
VAL_ 704 DrowsinessIndexSts 3 "Reserved" 2 "Input signal error" 1 "Valid" 0 "Initial state" ;
VAL_ 704 DrowsinessIndex 15 "Reserved" 14 "Reserved" 13 "Reserved" 12 "Reserved" 11 "Reserved" 10 "Reserved" 9 "Extreme sleepy, cannot stay awake" 8 "Very sleepy, high effort to stay awake" 7 "Sleep, with effort to stay awake" 6 "Sleepy, without effort to stay awake" 5 "Slightly sleepy" 4 "Neither awake nor sleepy" 3 "Quite awake" 2 "Normal awak" 1 "Very awake" 0 "Reserved" ;
VAL_ 704 RiTurnIndcrLiSts 3 " Invalid" 2 " Reserved" 1 " On" 0 " Off" ;
VAL_ 704 LeTurnIndcrLiSts 3 " Invalid" 2 " Reserved" 1 " On" 0 " Off" ;
VAL_ 704 PuddleLiFrntLeSts 3 " Invalid" 2 " Reserved" 1 " On" 0 " Off" ;
VAL_ 704 PuddleLiReLeSts 3 " Invalid" 2 " Reserved" 1 " On" 0 " Off" ;
VAL_ 704 ImmoAuthWarning 1 " Warning" 0 " No waring" ;
VAL_ 704 DrowsyWarning 1 "Warning On" 0 "No warning" ;
VAL_ 704 HndlLiSts 3 " Invalid" 2 " Reserved" 1 " On" 0 " Off" ;
VAL_ 704 LtgPwrSplyEnaSts 3 " Invalid" 2 " Reserved" 1 " lighting power supply enabled" 0 " lighting power supply not enabled" ;
VAL_ 704 LoBeamSts 3 " Invalid" 2 " Reserved" 1 " On" 0 " Off" ;
VAL_ 704 IntrLiFootWellSts 3 " Invalid" 2 " Reserved" 1 " On" 0 " Off" ;
VAL_ 704 DASFctSts 3 "Reserved" 2 "Reserved" 1 "DAS On" 0 "DAS Off" ;
VAL_ 704 HiBeamSts 3 " Invalid" 2 " Reserved" 1 " On" 0 " Off" ;
VAL_ 704 PosnLiSts 3 " Invalid" 2 " Reserved" 1 " On" 0 " Off" ;
VAL_ 704 FogLiFrntLeDrvrSts 3 " Invalid" 2 " Reserved" 1 " On" 0 " Off" ;
VAL_ 704 DayTiRunngLiSts 3 " Invalid" 2 " Reserved" 1 " On" 0 " Off" ;
VAL_ 704 PuddleLiFrntRiSts 3 " Invalid" 2 " Reserved" 1 " On" 0 " Off" ;
VAL_ 704 PuddleLiReRiSts 3 " Invalid" 2 " Reserved" 1 " On" 0 " Off" ;
VAL_ 701 TrAjarSts 3 " Invalid" 2 " Reserved" 1 " Closed" 0 " Opened" ;
VAL_ 701 DoorAjarReRiSts 3 " Invalid" 2 " Reserved" 1 " Closed" 0 " Opened" ;
VAL_ 701 CooltLvlLowWarnReq 3 "Invalid" 2 "Reserved" 1 "Request" 0 "No request" ;
VAL_ 701 DoorAjarReLeSts 3 " Invalid" 2 " Reserved" 1 " Closed" 0 " Opened" ;
VAL_ 701 DoorAjarFrntRiSts 3 " Invalid" 2 " Reserved" 1 " Closed" 0 " Opened" ;
VAL_ 701 SeatOccpFrntLeFail 3 "Invalid" 2 "Reserved" 1 "Failure" 0 "No failure" ;
VAL_ 701 DoorAjarFrntLeSts 3 " Invalid" 2 " Reserved" 1 " Closed" 0 " Opened" ;
VAL_ 701 SteerWhlHeatSts 3 " Invalid" 2 " Reserved" 1 " Heater on" 0 " Heater off" ;
VAL_ 701 SeatOccpFrntLeSts 3 " Invalid" 2 " Reserved" 1 " Occupant" 0 " No occupant" ;
VAL_ 701 HoodAjarSts 3 " Invalid" 2 " Reserved" 1 " Closed" 0 " Opened" ;
